VERSION "10.9.1"

NS_ :

BS_:

BU_: ACM ADAS_Body APM ASU_Gateway BCM BCM_BPM CCU_F CCU_R DUMMY_BCM_BPM DUMMY_ECU ETG LDM_L LDM_R OCS_P PSM_D SHVU_F SHVU_R TRM XGW_Body

BO_ 1112 MHU_BCM_Color_Req: 8 XGW_Body
 SG_ AmbLightColorZoneReq : 7|8@0+ (1,0) [0|31] "-"  BCM
 SG_ AmbLightColorRed : 15|8@0+ (1,0) [0|255] ""  BCM
 SG_ AmbLightColorGreen : 23|8@0+ (1,0) [0|255] "-"  BCM
 SG_ AmbLightColorBlue : 31|8@0+ (1,0) [0|255] "-"  BCM
 SG_ SECCAN_BCM_Clr_Rq : 63|8@0+ (1,0) [0|255] ""  BCM

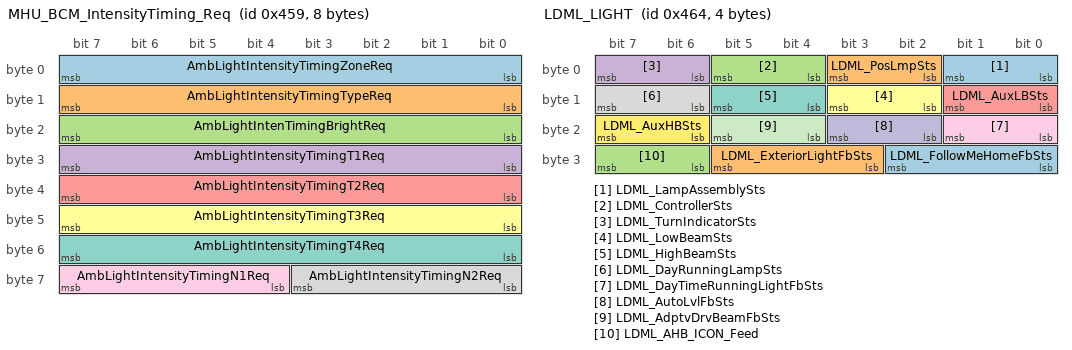
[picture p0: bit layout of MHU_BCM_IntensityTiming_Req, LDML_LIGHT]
BO_ 1113 MHU_BCM_IntensityTiming_Req: 8 XGW_Body
 SG_ AmbLightIntensityTimingZoneReq : 7|8@0+ (1,0) [0|31] ""  BCM
 SG_ AmbLightIntensityTimingTypeReq : 15|8@0+ (1,0) [0|5] ""  BCM
 SG_ AmbLightIntenTimingBrightReq : 23|8@0+ (1,0) [0|100] ""  BCM
 SG_ AmbLightIntensityTimingT1Req : 31|8@0+ (0.1,0) [0|25.5] "s"  BCM
 SG_ AmbLightIntensityTimingT2Req : 39|8@0+ (0.1,0) [0|25.5] "s"  BCM
 SG_ AmbLightIntensityTimingT3Req : 47|8@0+ (0.1,0) [0|25.5] "s"  BCM
 SG_ AmbLightIntensityTimingT4Req : 55|8@0+ (0.1,0) [0|25.5] "s"  BCM
 SG_ AmbLightIntensityTimingN2Req : 59|4@0+ (1,0) [0|15] "-"  BCM
 SG_ AmbLightIntensityTimingN1Req : 63|4@0+ (1,0) [0|15] ""  BCM

BO_ 1115 ADAS_HOD: 8 ADAS_Body
 SG_ HOD_steering_wheel_type : 5|4@0+ (1,0) [0|15] ""  XGW_Body
 SG_ HOD_vehicle_type : 15|8@0+ (1,0) [0|255] ""  XGW_Body
 SG_ ADAS_HOD_state_requesting : 57|2@0+ (1,0) [0|3] ""  XGW_Body

BO_ 1124 LDML_LIGHT: 4 LDM_L
 SG_ LDML_LampAssemblySts : 1|2@0+ (1,0) [0|3] "-"  BCM,XGW_Body
 SG_ LDML_PosLmpSts : 3|2@0+ (1,0) [0|3] ""  BCM,XGW_Body
 SG_ LDML_ControllerSts : 5|2@0+ (1,0) [0|3] ""  BCM,XGW_Body
 SG_ LDML_TurnIndicatorSts : 7|2@0+ (1,0) [0|3] ""  BCM,XGW_Body
 SG_ LDML_AuxLBSts : 9|2@0+ (1,0) [0|3] "-"  BCM,XGW_Body
 SG_ LDML_LowBeamSts : 11|2@0+ (1,0) [0|3] "-"  BCM,XGW_Body
 SG_ LDML_HighBeamSts : 13|2@0+ (1,0) [0|3] ""  BCM,XGW_Body
 SG_ LDML_DayRunningLampSts : 15|2@0+ (1,0) [0|3] ""  BCM,XGW_Body
 SG_ LDML_DayTimeRunningLightFbSts : 17|2@0+ (1,0) [0|3] ""  BCM,XGW_Body
 SG_ LDML_AutoLvlFbSts : 19|2@0+ (1,0) [0|3] ""  BCM,XGW_Body
 SG_ LDML_AdptvDrvBeamFbSts : 21|2@0+ (1,0) [0|3] "-"  BCM,XGW_Body
 SG_ LDML_AuxHBSts : 23|2@0+ (1,0) [0|3] "-"  BCM,XGW_Body
 SG_ LDML_FollowMeHomeFbSts : 26|3@0+ (1,0) [0|5] "-"  BCM,XGW_Body
 SG_ LDML_ExteriorLightFbSts : 29|3@0+ (1,0) [0|4] "-"  BCM,XGW_Body
 SG_ LDML_AHB_ICON_Feed : 31|2@0+ (1,0) [0|3] ""  XGW_Body

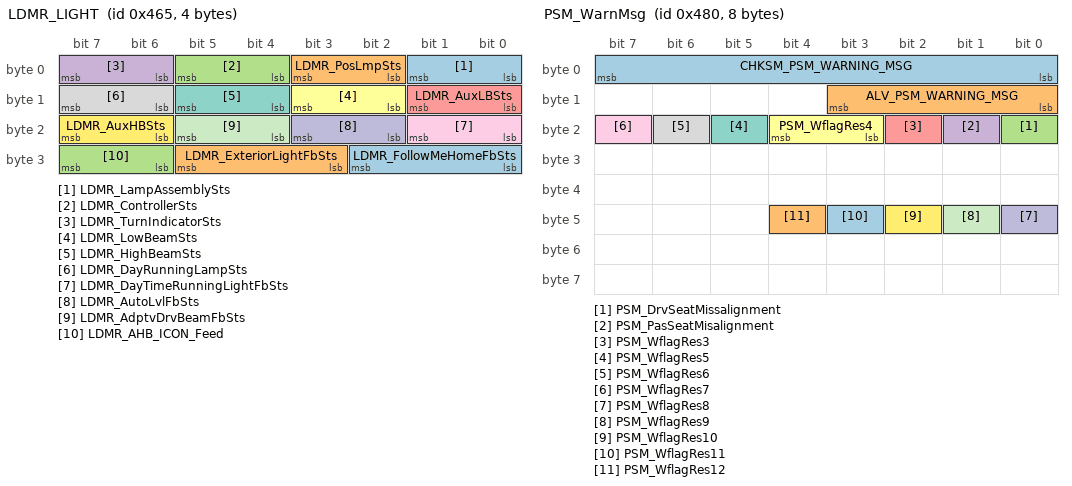
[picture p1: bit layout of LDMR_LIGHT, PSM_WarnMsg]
BO_ 1125 LDMR_LIGHT: 4 LDM_R
 SG_ LDMR_LampAssemblySts : 1|2@0+ (1,0) [0|3] ""  BCM,XGW_Body
 SG_ LDMR_PosLmpSts : 3|2@0+ (1,0) [0|3] "-"  BCM,XGW_Body
 SG_ LDMR_ControllerSts : 5|2@0+ (1,0) [0|3] ""  BCM,XGW_Body
 SG_ LDMR_TurnIndicatorSts : 7|2@0+ (1,0) [0|3] "-"  BCM,XGW_Body
 SG_ LDMR_AuxLBSts : 9|2@0+ (1,0) [0|3] "-"  BCM,XGW_Body
 SG_ LDMR_LowBeamSts : 11|2@0+ (1,0) [0|3] "-"  BCM,XGW_Body
 SG_ LDMR_HighBeamSts : 13|2@0+ (1,0) [0|3] ""  BCM,XGW_Body
 SG_ LDMR_DayRunningLampSts : 15|2@0+ (1,0) [0|3] ""  BCM,XGW_Body
 SG_ LDMR_DayTimeRunningLightFbSts : 17|2@0+ (1,0) [0|3] "-"  BCM,XGW_Body
 SG_ LDMR_AutoLvlFbSts : 19|2@0+ (1,0) [0|3] "-"  BCM,XGW_Body
 SG_ LDMR_AdptvDrvBeamFbSts : 21|2@0+ (1,0) [0|3] ""  BCM,XGW_Body
 SG_ LDMR_AuxHBSts : 23|2@0+ (1,0) [0|3] "-"  BCM,XGW_Body
 SG_ LDMR_FollowMeHomeFbSts : 26|3@0+ (1,0) [0|5] ""  BCM,XGW_Body
 SG_ LDMR_ExteriorLightFbSts : 29|3@0+ (1,0) [0|4] "-"  BCM,XGW_Body
 SG_ LDMR_AHB_ICON_Feed : 31|2@0+ (1,0) [0|3] ""  XGW_Body

BO_ 1152 PSM_WarnMsg: 8 PSM_D
 SG_ CHKSM_PSM_WARNING_MSG : 7|8@0+ (1,0) [0|255] ""  XGW_Body
 SG_ ALV_PSM_WARNING_MSG : 11|4@0+ (1,0) [0|14] ""  XGW_Body
 SG_ PSM_DrvSeatMissalignment : 16|1@0+ (1,0) [0|1] ""  XGW_Body
 SG_ PSM_PasSeatMisalignment : 17|1@0+ (1,0) [0|1] "Bit"  XGW_Body
 SG_ PSM_WflagRes3 : 18|1@0+ (1,0) [0|1] "Bit"  XGW_Body
 SG_ PSM_WflagRes4 : 20|2@0+ (1,0) [0|3] "Bit"  XGW_Body
 SG_ PSM_WflagRes5 : 21|1@0+ (1,0) [0|1] "-"  XGW_Body
 SG_ PSM_WflagRes6 : 22|1@0+ (1,0) [0|1] "-"  XGW_Body
 SG_ PSM_WflagRes7 : 23|1@0+ (1,0) [0|1] "-"  XGW_Body
 SG_ PSM_WflagRes8 : 40|1@0+ (1,0) [0|1] ""  XGW_Body
 SG_ PSM_WflagRes9 : 41|1@0+ (1,0) [0|1] ""  XGW_Body
 SG_ PSM_WflagRes10 : 42|1@0+ (1,0) [0|1] "-"  XGW_Body
 SG_ PSM_WflagRes11 : 43|1@0+ (1,0) [0|1] "-"  XGW_Body
 SG_ PSM_WflagRes12 : 44|1@0+ (1,0) [0|1] "-"  XGW_Body

BO_ 1153 BCM_WarnMsg: 8 BCM
 SG_ CHSKM_BCM_WarnMsg : 7|8@0+ (1,0) [0|255] "" XGW_Body
 SG_ ALV_BCM_WarnMsg : 11|4@0+ (1,0) [0|14] "" XGW_Body
 SG_ BCM_NoValidKey_1 : 12|1@0+ (1,0) [0|1] "" XGW_Body
 SG_ BCM_SSB_defect : 13|1@0+ (1,0) [0|1] "" XGW_Body
 SG_ BCM_WrongGearPosToStart : 14|1@0+ (1,0) [0|1] "" XGW_Body
 SG_ BCM_NoValidKey_2 : 15|1@0+ (1,0) [0|1] "" XGW_Body
 SG_ BCM_PressBrakeToStart : 16|1@0+ (1,0) [0|1] "" XGW_Body
 SG_ BCM_TurnOffPosLightRemindr : 17|1@0+ (1,0) [0|1] "" XGW_Body
 SG_ BCM_KeyFob_LowBattery : 18|1@0+ (1,0) [0|1] "" XGW_Body
 SG_ BCM_StopLightDefect : 19|1@0+ (1,0) [0|1] "" XGW_Body
 SG_ BCM_LowBeamDefect : 20|1@0+ (1,0) [0|1] "" XGW_Body
 SG_ BCM_HighBeamDefect : 21|1@0+ (1,0) [0|1] "" XGW_Body
 SG_ BCM_PositionLightDefect : 22|1@0+ (1,0) [0|1] "" XGW_Body
 SG_ BCM_CHMLS_Defect : 23|1@0+ (1,0) [0|1] "" XGW_Body
 SG_ BCM_LicencePlateLight_Defect : 24|1@0+ (1,0) [0|1] "" XGW_Body
 SG_ BCM_FrontFog_Defect : 25|1@0+ (1,0) [0|1] "" XGW_Body
 SG_ BCM_RearFog_Defect : 26|1@0+ (1,0) [0|1] "" XGW_Body
 SG_ BCM_ReverseLightDefect : 27|1@0+ (1,0) [0|1] "" XGW_Body
 SG_ BCM_RLS_Malfunction : 28|1@0+ (1,0) [0|1] "" XGW_Body
 SG_ BCM_12VBattery_LowLevel : 29|1@0+ (1,0) [0|1] "" XGW_Body
 SG_ BCM_ForgetKeyFOBInCar : 30|1@0+ (1,0) [0|1] "" XGW_Body
 SG_ BCM_12VBattery_Discharging : 31|1@0+ (1,0) [0|1] "" XGW_Body
 SG_ BCM_TurnIndicatorDefect : 32|1@0+ (1,0) [0|1] "" XGW_Body
 SG_ BCM_dTPMS_Malfunc : 33|1@0+ (1,0) [0|1] "" XGW_Body
 SG_ BCM_dTPMS_Malfunc_LostSensor : 34|1@0+ (1,0) [0|1] "" XGW_Body
 SG_ BCM_dTPMS_LowPressure : 35|1@0+ (1,0) [0|1] "" XGW_Body
 SG_ BCM_dTPMS_RapidLeak : 36|1@0+ (1,0) [0|1] "" XGW_Body
 SG_ BCM_dTPMS_HighTemperature : 37|1@0+ (1,0) [0|1] "" XGW_Body
 SG_ BCM_dTPMS_HighPressure : 38|1@0+ (1,0) [0|1] "" XGW_Body
 SG_ BCM_dTPMS_LowBattery : 39|1@0+ (1,0) [0|1] "" XGW_Body
 SG_ BCM_Keyfob_Leftcar : 40|1@0+ (1,0) [0|1] "" XGW_Body
 SG_ BCM_IDB_Brakelight_Malfunction : 41|1@0+ (1,0) [0|1] "" XGW_Body
 SG_ BCM_VCU_Brakelight_Malfunction : 42|1@0+ (1,0) [0|1] "" XGW_Body
 SG_ BCM_ADAS_Turnlight_Malfunction : 43|1@0+ (1,0) [0|1] "" XGW_Body
 SG_ BCM_ADAS_Highbeam_Malfunction : 44|1@0+ (1,0) [0|1] "" XGW_Body
 SG_ BCM_ADAS_LowBeam_Malfunction : 45|1@0+ (1,0) [0|1] "" XGW_Body
 SG_ BCM_MHU_Malfunction : 46|1@0+ (1,0) [0|1] "" XGW_Body
 SG_ BCM_BCM_Malfunction : 47|1@0+ (1,0) [0|1] "" XGW_Body
 SG_ BCM_SCM_Malfunction : 48|1@0+ (1,0) [0|1] "" XGW_Body
 SG_ BCM_CrashSignalDefect : 49|1@0+ (1,0) [0|1] "" XGW_Body
 SG_ BCM_FrontWiperDefect : 51|1@0+ (1,0) [0|1] "" XGW_Body
 SG_ BCM_Rear_RightDoorLockDefect : 52|1@0+ (1,0) [0|1] "" XGW_Body
 SG_ BCM_RearLeftDoorLockDefect : 53|1@0+ (1,0) [0|1] "" XGW_Body
 SG_ BCM_Front_RightDoorLockDefect : 54|1@0+ (1,0) [0|1] "" XGW_Body
 SG_ BCM_FrontLeftDoorLockDefect : 55|1@0+ (1,0) [0|1] "" XGW_Body
 SG_ BCM_LDML_Malfunction : 56|1@0+ (1,0) [0|1] "" XGW_Body
 SG_ BCM_LDMR_Malfunction : 57|1@0+ (1,0) [0|1] "" XGW_Body
 SG_ BCM_RLBL_Malfunction : 58|1@0+ (1,0) [0|1] "" XGW_Body
 SG_ BCM_RLBR_Malfunction : 59|1@0+ (1,0) [0|1] "" XGW_Body
 SG_ BCM_RLT_Malfunction : 60|1@0+ (1,0) [0|1] "" XGW_Body
 SG_ BCM_BCM_POWER_Malfunction : 61|1@0+ (1,0) [0|1] "" XGW_Body
 SG_ BCM_IDB_AutoHazardBlinking_Malf : 62|1@0+ (1,0) [0|1] "" XGW_Body

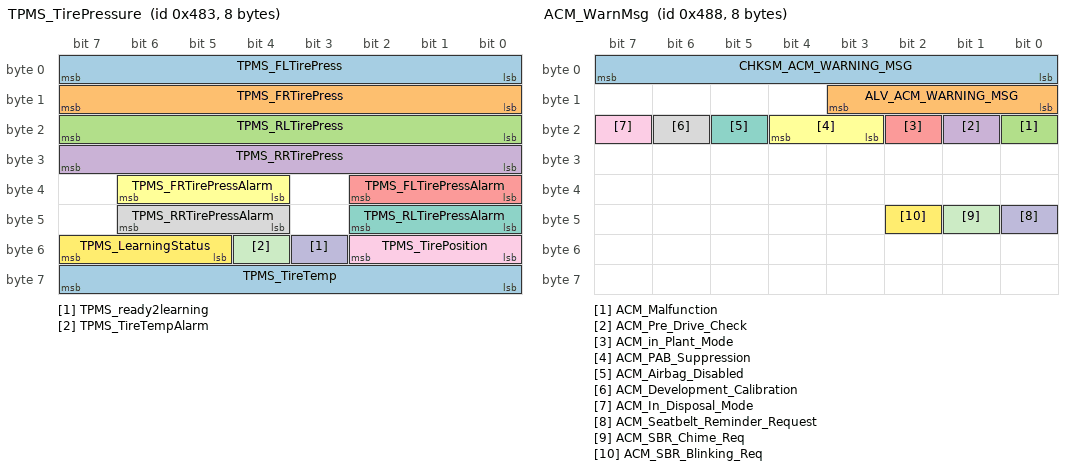
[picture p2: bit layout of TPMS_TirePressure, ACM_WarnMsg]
BO_ 1155 TPMS_TirePressure: 8 BCM
 SG_ TPMS_FLTirePress : 7|8@0+ (1.373,0) [0|350] "kPa"  ADAS_Body,XGW_Body
 SG_ TPMS_FRTirePress : 15|8@0+ (1.373,0) [0|350] "kPa"  ADAS_Body,XGW_Body
 SG_ TPMS_RLTirePress : 23|8@0+ (1.373,0) [0|350] "kPa"  ADAS_Body,XGW_Body
 SG_ TPMS_RRTirePress : 31|8@0+ (1.373,0) [0|350] "kPa"  ADAS_Body,XGW_Body
 SG_ TPMS_FLTirePressAlarm : 34|3@0+ (1,0) [0|7] ""  ADAS_Body,XGW_Body
 SG_ TPMS_FRTirePressAlarm : 38|3@0+ (1,0) [0|7] "-"  ADAS_Body,XGW_Body
 SG_ TPMS_RLTirePressAlarm : 42|3@0+ (1,0) [0|7] ""  ADAS_Body,XGW_Body
 SG_ TPMS_RRTirePressAlarm : 46|3@0+ (1,0) [0|7] ""  ADAS_Body,XGW_Body
 SG_ TPMS_TirePosition : 50|3@0+ (1,0) [0|7] "-"  XGW_Body
 SG_ TPMS_ready2learning : 51|1@0+ (1,0) [0|1] "-"  XGW_Body
 SG_ TPMS_TireTempAlarm : 52|1@0+ (1,0) [0|1] "-"  XGW_Body
 SG_ TPMS_LearningStatus : 55|3@0+ (1,0) [0|7] "-"  XGW_Body
 SG_ TPMS_TireTemp : 63|8@0+ (1,-40) [-40|215] "Degree C"  XGW_Body

BO_ 1160 ACM_WarnMsg: 8 ACM
 SG_ CHKSM_ACM_WARNING_MSG : 7|8@0+ (1,0) [0|255] ""  XGW_Body
 SG_ ALV_ACM_WARNING_MSG : 11|4@0+ (1,0) [0|14] ""  XGW_Body
 SG_ ACM_Malfunction : 16|1@0+ (1,0) [0|1] ""  XGW_Body
 SG_ ACM_Pre_Drive_Check : 17|1@0+ (1,0) [0|1] "Bit"  XGW_Body
 SG_ ACM_in_Plant_Mode : 18|1@0+ (1,0) [0|1] "Bit"  XGW_Body
 SG_ ACM_PAB_Suppression : 20|2@0+ (1,0) [0|3] "Bit"  XGW_Body
 SG_ ACM_Airbag_Disabled : 21|1@0+ (1,0) [0|1] "-"  XGW_Body
 SG_ ACM_Development_Calibration : 22|1@0+ (1,0) [0|1] "-"  XGW_Body
 SG_ ACM_In_Disposal_Mode : 23|1@0+ (1,0) [0|1] ""  XGW_Body
 SG_ ACM_Seatbelt_Reminder_Request : 40|1@0+ (1,0) [0|1] "-"  XGW_Body
 SG_ ACM_SBR_Chime_Req : 41|1@0+ (1,0) [0|1] ""  XGW_Body
 SG_ ACM_SBR_Blinking_Req : 42|1@0+ (1,0) [0|1] ""  XGW_Body

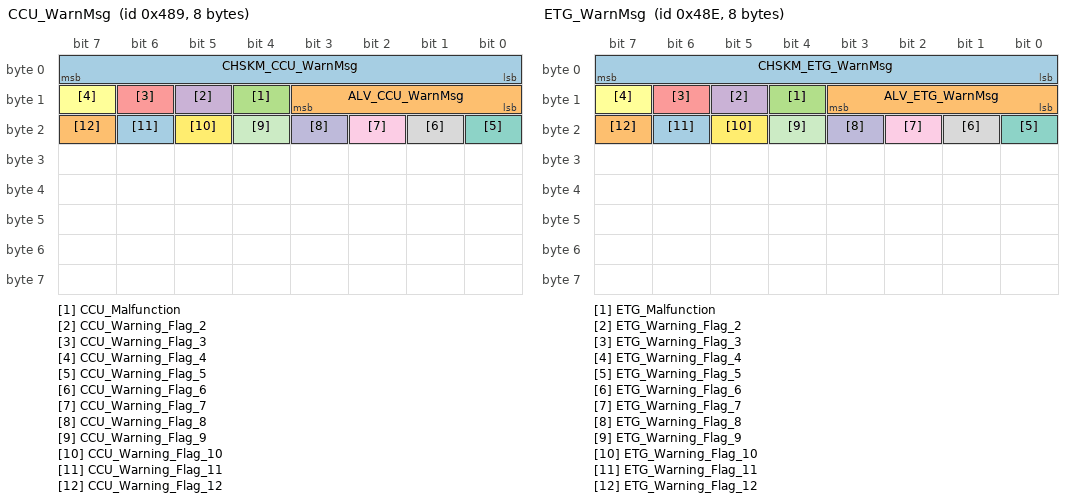
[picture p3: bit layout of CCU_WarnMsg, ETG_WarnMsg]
BO_ 1161 CCU_WarnMsg: 8 CCU_F
 SG_ CHSKM_CCU_WarnMsg : 7|8@0+ (1,0) [0|255] ""  XGW_Body
 SG_ ALV_CCU_WarnMsg : 11|4@0+ (1,0) [0|14] ""  XGW_Body
 SG_ CCU_Malfunction : 12|1@0+ (1,0) [0|1] ""  XGW_Body
 SG_ CCU_Warning_Flag_2 : 13|1@0+ (1,0) [0|1] "-"  XGW_Body
 SG_ CCU_Warning_Flag_3 : 14|1@0+ (1,0) [0|1] ""  XGW_Body
 SG_ CCU_Warning_Flag_4 : 15|1@0+ (1,0) [0|1] "-"  XGW_Body
 SG_ CCU_Warning_Flag_5 : 16|1@0+ (1,0) [0|1] "-"  XGW_Body
 SG_ CCU_Warning_Flag_6 : 17|1@0+ (1,0) [0|1] "-"  XGW_Body
 SG_ CCU_Warning_Flag_7 : 18|1@0+ (1,0) [0|1] "-"  XGW_Body
 SG_ CCU_Warning_Flag_8 : 19|1@0+ (1,0) [0|1] ""  XGW_Body
 SG_ CCU_Warning_Flag_9 : 20|1@0+ (1,0) [0|1] ""  XGW_Body
 SG_ CCU_Warning_Flag_10 : 21|1@0+ (1,0) [0|1] ""  XGW_Body
 SG_ CCU_Warning_Flag_11 : 22|1@0+ (1,0) [0|1] ""  XGW_Body
 SG_ CCU_Warning_Flag_12 : 23|1@0+ (1,0) [0|1] ""  XGW_Body

BO_ 1166 ETG_WarnMsg: 8 ETG
 SG_ CHSKM_ETG_WarnMsg : 7|8@0+ (1,0) [0|255] ""  XGW_Body
 SG_ ALV_ETG_WarnMsg : 11|4@0+ (1,0) [0|14] ""  XGW_Body
 SG_ ETG_Malfunction : 12|1@0+ (1,0) [0|1] "-"  XGW_Body
 SG_ ETG_Warning_Flag_2 : 13|1@0+ (1,0) [0|1] "-"  XGW_Body
 SG_ ETG_Warning_Flag_3 : 14|1@0+ (1,0) [0|1] ""  XGW_Body
 SG_ ETG_Warning_Flag_4 : 15|1@0+ (1,0) [0|1] ""  XGW_Body
 SG_ ETG_Warning_Flag_5 : 16|1@0+ (1,0) [0|1] "-"  XGW_Body
 SG_ ETG_Warning_Flag_6 : 17|1@0+ (1,0) [0|1] "-"  XGW_Body
 SG_ ETG_Warning_Flag_7 : 18|1@0+ (1,0) [0|1] "-"  XGW_Body
 SG_ ETG_Warning_Flag_8 : 19|1@0+ (1,0) [0|1] ""  XGW_Body
 SG_ ETG_Warning_Flag_9 : 20|1@0+ (1,0) [0|1] ""  XGW_Body
 SG_ ETG_Warning_Flag_10 : 21|1@0+ (1,0) [0|1] ""  XGW_Body
 SG_ ETG_Warning_Flag_11 : 22|1@0+ (1,0) [0|1] "-"  XGW_Body
 SG_ ETG_Warning_Flag_12 : 23|1@0+ (1,0) [0|1] ""  XGW_Body

BO_ 1171 BMS_WarnMsg: 8 XGW_Body
 SG_ CHSKM_BMS_WarnMsg : 7|8@0+ (1,0) [0|255] "" BCM
 SG_ ALV_BMS_WarnMsg : 11|4@0+ (1,0) [0|14] "" BCM
 SG_ BMS_PackTempSts : 13|2@0+ (1,0) [0|3] "" BCM
 SG_ BMS_ThermalRunaway : 14|1@0+ (1,0) [0|1] "" BCM
 SG_ BMS_BatteryReplacement : 15|1@0+ (1,0) [0|1] "" BCM
 SG_ BMS_Warning_PowerDegrade : 16|1@0+ (1,0) [0|1] "" BCM
 SG_ BMS_Warning_DeltaSoC : 17|1@0+ (1,0) [0|1] "" BCM
 SG_ BMS_Warning_HVILSts : 18|1@0+ (1,0) [0|1] "" BCM
 SG_ BMS_Warning_Isolation : 19|1@0+ (1,0) [0|1] "" BCM
 SG_ BMS_Warning_CoolantLeakage : 20|1@0+ (1,0) [0|1] "" BCM
 SG_ BMS_MalfunctionSts : 21|1@0+ (1,0) [0|1] "" BCM
 SG_ BMS_LowBattery : 23|2@0+ (1,0) [0|3] "" BCM
 SG_ BMS_Warning_DeltaTemperature : 31|8@0+ (1,0) [0|255] "" BCM
 SG_ BMS_Warning_BDUTemperatureSts : 39|8@0+ (1,0) [0|255] "" BCM
 SG_ BMS_Warning_Contactor_Aging : 47|1@0+ (1,0) [0|1] "" DUMMY_ECU
 SG_ BMS_Reserved_signal4 : 55|8@0+ (1,0) [0|255] "" BCM
 SG_ BMS_Reserved_signal5 : 63|8@0+ (1,0) [0|255] "" BCM

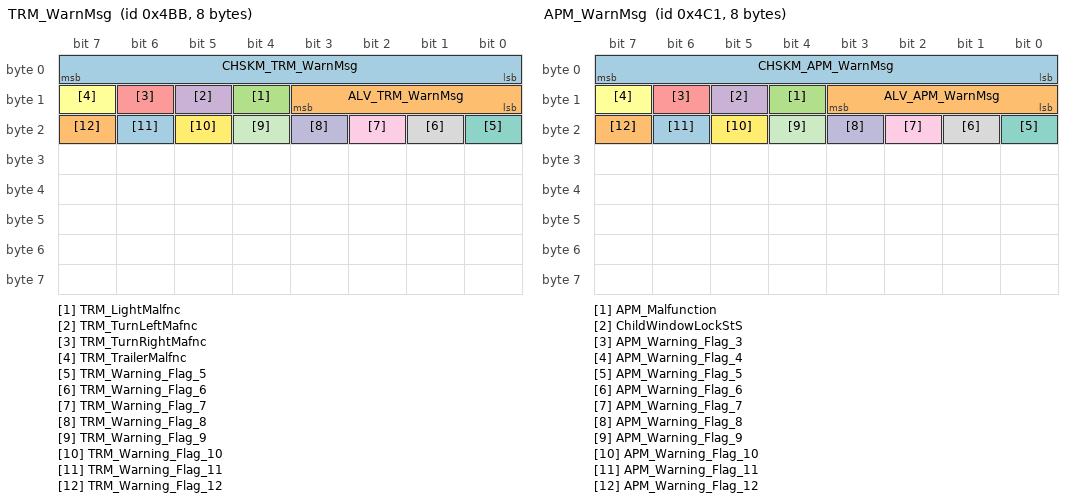
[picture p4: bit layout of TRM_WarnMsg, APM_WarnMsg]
BO_ 1211 TRM_WarnMsg: 8 TRM
 SG_ CHSKM_TRM_WarnMsg : 7|8@0+ (1,0) [0|255] ""  XGW_Body
 SG_ ALV_TRM_WarnMsg : 11|4@0+ (1,0) [0|14] ""  XGW_Body
 SG_ TRM_LightMalfnc : 12|1@0+ (1,0) [0|1] "-"  XGW_Body
 SG_ TRM_TurnLeftMafnc : 13|1@0+ (1,0) [0|1] "-"  XGW_Body
 SG_ TRM_TurnRightMafnc : 14|1@0+ (1,0) [0|1] ""  XGW_Body
 SG_ TRM_TrailerMalfnc : 15|1@0+ (1,0) [0|1] ""  XGW_Body
 SG_ TRM_Warning_Flag_5 : 16|1@0+ (1,0) [0|1] "-"  XGW_Body
 SG_ TRM_Warning_Flag_6 : 17|1@0+ (1,0) [0|1] ""  XGW_Body
 SG_ TRM_Warning_Flag_7 : 18|1@0+ (1,0) [0|1] ""  XGW_Body
 SG_ TRM_Warning_Flag_8 : 19|1@0+ (1,0) [0|1] "-"  XGW_Body
 SG_ TRM_Warning_Flag_9 : 20|1@0+ (1,0) [0|1] "-"  XGW_Body
 SG_ TRM_Warning_Flag_10 : 21|1@0+ (1,0) [0|1] "-"  XGW_Body
 SG_ TRM_Warning_Flag_11 : 22|1@0+ (1,0) [0|1] ""  XGW_Body
 SG_ TRM_Warning_Flag_12 : 23|1@0+ (1,0) [0|1] ""  XGW_Body

BO_ 1216 BCM_STAT_DOOR: 8 BCM
 SG_ SECCAN_BCM_STAT_Door : 55|8@0+ (1,0) [0|255] ""  ADAS_Body
 SG_ BCM_STAT_DoorHandleRR : 56|1@0+ (1,0) [0|1] ""  ADAS_Body
 SG_ BCM_STAT_DoorHandleRL : 57|1@0+ (1,0) [0|1] ""  ADAS_Body
 SG_ BCM_STAT_DoorHandleFR : 58|1@0+ (1,0) [0|1] ""  ADAS_Body
 SG_ BCM_STAT_DoorHandleFL : 59|1@0+ (1,0) [0|1] ""  ADAS_Body

BO_ 1217 APM_WarnMsg: 8 APM
 SG_ CHSKM_APM_WarnMsg : 7|8@0+ (1,0) [0|255] ""  XGW_Body
 SG_ ALV_APM_WarnMsg : 11|4@0+ (1,0) [0|14] ""  XGW_Body
 SG_ APM_Malfunction : 12|1@0+ (1,0) [0|1] ""  XGW_Body
 SG_ ChildWindowLockStS : 13|1@0+ (1,0) [0|1] "-"  XGW_Body
 SG_ APM_Warning_Flag_3 : 14|1@0+ (1,0) [0|1] ""  XGW_Body
 SG_ APM_Warning_Flag_4 : 15|1@0+ (1,0) [0|1] ""  XGW_Body
 SG_ APM_Warning_Flag_5 : 16|1@0+ (1,0) [0|1] "-"  XGW_Body
 SG_ APM_Warning_Flag_6 : 17|1@0+ (1,0) [0|1] ""  XGW_Body
 SG_ APM_Warning_Flag_7 : 18|1@0+ (1,0) [0|1] "-"  XGW_Body
 SG_ APM_Warning_Flag_8 : 19|1@0+ (1,0) [0|1] ""  XGW_Body
 SG_ APM_Warning_Flag_9 : 20|1@0+ (1,0) [0|1] ""  XGW_Body
 SG_ APM_Warning_Flag_10 : 21|1@0+ (1,0) [0|1] ""  XGW_Body
 SG_ APM_Warning_Flag_11 : 22|1@0+ (1,0) [0|1] ""  XGW_Body
 SG_ APM_Warning_Flag_12 : 23|1@0+ (1,0) [0|1] "-"  XGW_Body

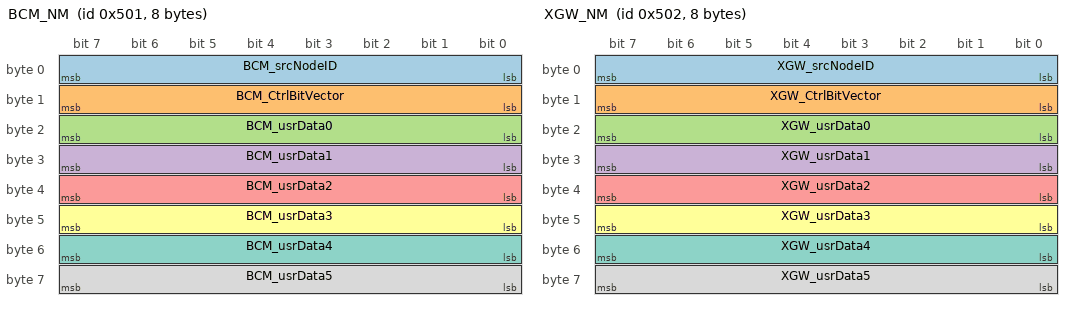
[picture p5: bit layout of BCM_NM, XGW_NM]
BO_ 1281 BCM_NM: 8 BCM
 SG_ BCM_srcNodeID : 7|8@0+ (1,0) [0|255] ""  APM,CCU_F,CCU_R,ETG,LDM_L,LDM_R,PSM_D,TRM,XGW_Body
 SG_ BCM_CtrlBitVector : 15|8@0+ (1,0) [0|255] ""  APM,CCU_F,CCU_R,ETG,LDM_L,LDM_R,PSM_D,TRM,XGW_Body
 SG_ BCM_usrData0 : 23|8@0+ (1,0) [0|255] ""  APM,CCU_F,CCU_R,ETG,LDM_L,LDM_R,PSM_D,TRM,XGW_Body
 SG_ BCM_usrData1 : 31|8@0+ (1,0) [0|255] ""  APM,CCU_F,CCU_R,ETG,LDM_L,LDM_R,PSM_D,TRM,XGW_Body
 SG_ BCM_usrData2 : 39|8@0+ (1,0) [0|255] ""  APM,CCU_F,CCU_R,ETG,LDM_L,LDM_R,PSM_D,TRM,XGW_Body
 SG_ BCM_usrData3 : 47|8@0+ (1,0) [0|255] ""  APM,CCU_F,CCU_R,ETG,LDM_L,LDM_R,PSM_D,TRM,XGW_Body
 SG_ BCM_usrData4 : 55|8@0+ (1,0) [0|255] ""  APM,CCU_F,CCU_R,ETG,LDM_L,LDM_R,PSM_D,TRM,XGW_Body
 SG_ BCM_usrData5 : 63|8@0+ (1,0) [0|255] ""  APM,CCU_F,CCU_R,ETG,LDM_L,LDM_R,PSM_D,TRM,XGW_Body

BO_ 1282 XGW_NM: 8 XGW_Body
 SG_ XGW_srcNodeID : 7|8@0+ (1,0) [0|255] ""  APM,ASU_Gateway,BCM,CCU_F,CCU_R,ETG,LDM_L,LDM_R,PSM_D,TRM
 SG_ XGW_CtrlBitVector : 15|8@0+ (1,0) [0|255] ""  APM,ASU_Gateway,BCM,CCU_F,CCU_R,ETG,LDM_L,LDM_R,PSM_D,TRM
 SG_ XGW_usrData0 : 23|8@0+ (1,0) [0|255] ""  APM,ASU_Gateway,BCM,CCU_F,CCU_R,ETG,LDM_L,LDM_R,PSM_D,TRM
 SG_ XGW_usrData1 : 31|8@0+ (1,0) [0|255] ""  APM,ASU_Gateway,BCM,CCU_F,CCU_R,ETG,LDM_L,LDM_R,PSM_D,TRM
 SG_ XGW_usrData2 : 39|8@0+ (1,0) [0|255] ""  APM,ASU_Gateway,BCM,CCU_F,CCU_R,ETG,LDM_L,LDM_R,PSM_D,TRM
 SG_ XGW_usrData3 : 47|8@0+ (1,0) [0|255] ""  APM,ASU_Gateway,BCM,CCU_F,CCU_R,ETG,LDM_L,LDM_R,PSM_D,TRM
 SG_ XGW_usrData4 : 55|8@0+ (1,0) [0|255] ""  APM,ASU_Gateway,BCM,CCU_F,CCU_R,ETG,LDM_L,LDM_R,PSM_D,TRM
 SG_ XGW_usrData5 : 63|8@0+ (1,0) [0|255] ""  APM,ASU_Gateway,BCM,CCU_F,CCU_R,ETG,LDM_L,LDM_R,PSM_D,TRM

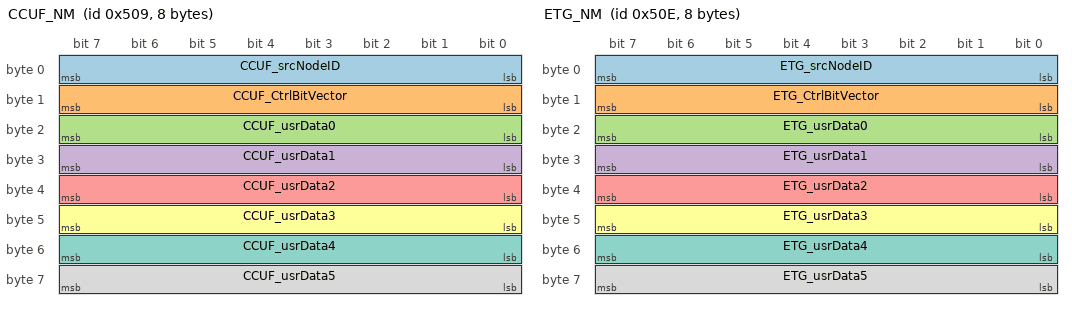
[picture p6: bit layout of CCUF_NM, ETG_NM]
BO_ 1289 CCUF_NM: 8 CCU_F
 SG_ CCUF_srcNodeID : 7|8@0+ (1,0) [0|255] ""  APM,BCM,CCU_R,ETG,LDM_L,LDM_R,PSM_D,TRM,XGW_Body
 SG_ CCUF_CtrlBitVector : 15|8@0+ (1,0) [0|255] ""  APM,BCM,CCU_R,ETG,LDM_L,LDM_R,PSM_D,TRM,XGW_Body
 SG_ CCUF_usrData0 : 23|8@0+ (1,0) [0|255] ""  APM,BCM,CCU_R,ETG,LDM_L,LDM_R,PSM_D,TRM,XGW_Body
 SG_ CCUF_usrData1 : 31|8@0+ (1,0) [0|255] ""  APM,BCM,CCU_R,ETG,LDM_L,LDM_R,PSM_D,TRM,XGW_Body
 SG_ CCUF_usrData2 : 39|8@0+ (1,0) [0|255] ""  APM,BCM,CCU_R,ETG,LDM_L,LDM_R,PSM_D,TRM,XGW_Body
 SG_ CCUF_usrData3 : 47|8@0+ (1,0) [0|255] ""  APM,BCM,CCU_R,ETG,LDM_L,LDM_R,PSM_D,TRM,XGW_Body
 SG_ CCUF_usrData4 : 55|8@0+ (1,0) [0|255] ""  APM,BCM,CCU_R,ETG,LDM_L,LDM_R,PSM_D,TRM,XGW_Body
 SG_ CCUF_usrData5 : 63|8@0+ (1,0) [0|255] ""  APM,BCM,CCU_R,ETG,LDM_L,LDM_R,PSM_D,TRM,XGW_Body

BO_ 1294 ETG_NM: 8 ETG
 SG_ ETG_srcNodeID : 7|8@0+ (1,0) [0|255] ""  APM,BCM,CCU_F,CCU_R,LDM_L,LDM_R,PSM_D,TRM,XGW_Body
 SG_ ETG_CtrlBitVector : 15|8@0+ (1,0) [0|255] ""  APM,BCM,CCU_F,CCU_R,LDM_L,LDM_R,PSM_D,TRM,XGW_Body
 SG_ ETG_usrData0 : 23|8@0+ (1,0) [0|255] ""  APM,BCM,CCU_F,CCU_R,LDM_L,LDM_R,PSM_D,TRM,XGW_Body
 SG_ ETG_usrData1 : 31|8@0+ (1,0) [0|255] ""  APM,BCM,CCU_F,CCU_R,LDM_L,LDM_R,PSM_D,TRM,XGW_Body
 SG_ ETG_usrData2 : 39|8@0+ (1,0) [0|255] ""  APM,BCM,CCU_F,CCU_R,LDM_L,LDM_R,PSM_D,TRM,XGW_Body
 SG_ ETG_usrData3 : 47|8@0+ (1,0) [0|255] ""  APM,BCM,CCU_F,CCU_R,LDM_L,LDM_R,PSM_D,TRM,XGW_Body
 SG_ ETG_usrData4 : 55|8@0+ (1,0) [0|255] ""  APM,BCM,CCU_F,CCU_R,LDM_L,LDM_R,PSM_D,TRM,XGW_Body
 SG_ ETG_usrData5 : 63|8@0+ (1,0) [0|255] ""  APM,BCM,CCU_F,CCU_R,LDM_L,LDM_R,PSM_D,TRM,XGW_Body

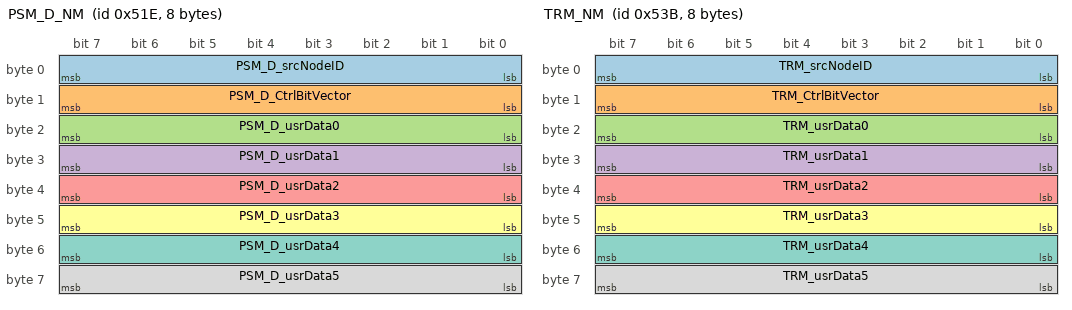
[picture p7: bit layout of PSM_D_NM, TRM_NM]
BO_ 1310 PSM_D_NM: 8 PSM_D
 SG_ PSM_D_srcNodeID : 7|8@0+ (1,0) [0|255] ""  APM,BCM,CCU_F,CCU_R,ETG,LDM_L,LDM_R,TRM,XGW_Body
 SG_ PSM_D_CtrlBitVector : 15|8@0+ (1,0) [0|255] ""  APM,BCM,CCU_F,CCU_R,ETG,LDM_L,LDM_R,TRM,XGW_Body
 SG_ PSM_D_usrData0 : 23|8@0+ (1,0) [0|255] ""  APM,BCM,CCU_F,CCU_R,ETG,LDM_L,LDM_R,TRM,XGW_Body
 SG_ PSM_D_usrData1 : 31|8@0+ (1,0) [0|255] ""  APM,BCM,CCU_F,CCU_R,ETG,LDM_L,LDM_R,TRM,XGW_Body
 SG_ PSM_D_usrData2 : 39|8@0+ (1,0) [0|255] ""  APM,BCM,CCU_F,CCU_R,ETG,LDM_L,LDM_R,TRM,XGW_Body
 SG_ PSM_D_usrData3 : 47|8@0+ (1,0) [0|255] ""  APM,BCM,CCU_F,CCU_R,ETG,LDM_L,LDM_R,TRM,XGW_Body
 SG_ PSM_D_usrData4 : 55|8@0+ (1,0) [0|255] ""  APM,BCM,CCU_F,CCU_R,ETG,LDM_L,LDM_R,TRM,XGW_Body
 SG_ PSM_D_usrData5 : 63|8@0+ (1,0) [0|255] ""  APM,BCM,CCU_F,CCU_R,ETG,LDM_L,LDM_R,TRM,XGW_Body

BO_ 1339 TRM_NM: 8 TRM
SG_ TRM_srcNodeID : 7|8@0+ (1,0) [0|255] ""  LDM_R,LDM_L,XGW_Body,BCM,ETG,APM,CCU_F,PSM_D,CCU_R
SG_ TRM_CtrlBitVector : 15|8@0+ (1,0) [0|255] ""  LDM_R,LDM_L,XGW_Body,BCM,ETG,APM,CCU_F,PSM_D,CCU_R
SG_ TRM_usrData0 : 23|8@0+ (1,0) [0|255] ""  LDM_R,LDM_L,XGW_Body,BCM,ETG,APM,CCU_F,PSM_D,CCU_R
SG_ TRM_usrData1 : 31|8@0+ (1,0) [0|255] ""  LDM_R,LDM_L,XGW_Body,BCM,ETG,APM,CCU_F,PSM_D,CCU_R
SG_ TRM_usrData2 : 39|8@0+ (1,0) [0|255] ""  LDM_R,LDM_L,XGW_Body,BCM,ETG,APM,CCU_F,PSM_D,CCU_R
SG_ TRM_usrData3 : 47|8@0+ (1,0) [0|255] ""  LDM_R,LDM_L,XGW_Body,BCM,ETG,APM,CCU_F,PSM_D,CCU_R
SG_ TRM_usrData4 : 55|8@0+ (1,0) [0|255] ""  LDM_R,LDM_L,XGW_Body,BCM,ETG,APM,CCU_F,PSM_D,CCU_R
SG_ TRM_usrData5 : 63|8@0+ (1,0) [0|255] ""  LDM_R,LDM_L,XGW_Body,BCM,ETG,APM,CCU_F,PSM_D,CCU_R

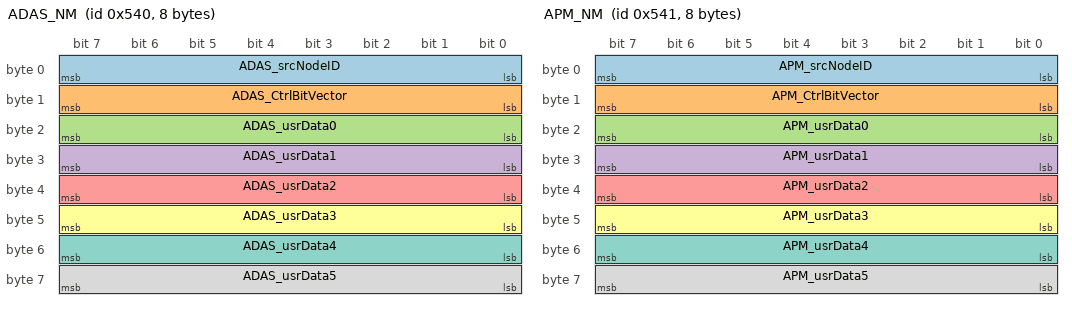
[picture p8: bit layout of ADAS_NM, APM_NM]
BO_ 1344 ADAS_NM: 8 ADAS_Body
 SG_ ADAS_srcNodeID : 7|8@0+ (1,0) [0|255] ""  ACM,APM,BCM,BCM_BPM,CCU_F,CCU_R,ETG,LDM_L,LDM_R,OCS_P,PSM_D,SHVU_F,SHVU_R,TRM,XGW_Body
 SG_ ADAS_CtrlBitVector : 15|8@0+ (1,0) [0|255] "-"  ACM,APM,BCM,BCM_BPM,CCU_F,CCU_R,ETG,LDM_L,LDM_R,OCS_P,PSM_D,SHVU_F,SHVU_R,TRM,XGW_Body
 SG_ ADAS_usrData0 : 23|8@0+ (1,0) [0|255] ""  ACM,APM,BCM,BCM_BPM,CCU_F,CCU_R,ETG,LDM_L,LDM_R,OCS_P,PSM_D,SHVU_F,SHVU_R,TRM,XGW_Body
 SG_ ADAS_usrData1 : 31|8@0+ (1,0) [0|255] ""  ACM,APM,BCM,BCM_BPM,CCU_F,CCU_R,ETG,LDM_L,LDM_R,OCS_P,PSM_D,SHVU_F,SHVU_R,TRM,XGW_Body
 SG_ ADAS_usrData2 : 39|8@0+ (1,0) [0|255] ""  ACM,APM,BCM,BCM_BPM,CCU_F,CCU_R,ETG,LDM_L,LDM_R,OCS_P,PSM_D,SHVU_F,SHVU_R,TRM,XGW_Body
 SG_ ADAS_usrData3 : 47|8@0+ (1,0) [0|255] "-"  ACM,APM,BCM,BCM_BPM,CCU_F,CCU_R,ETG,LDM_L,LDM_R,OCS_P,PSM_D,SHVU_F,SHVU_R,TRM,XGW_Body
 SG_ ADAS_usrData4 : 55|8@0+ (1,0) [0|255] "-"  ACM,APM,BCM,BCM_BPM,CCU_F,CCU_R,ETG,LDM_L,LDM_R,OCS_P,PSM_D,SHVU_F,SHVU_R,TRM,XGW_Body
 SG_ ADAS_usrData5 : 63|8@0+ (1,0) [0|255] "-"  ACM,APM,BCM,BCM_BPM,CCU_F,CCU_R,ETG,LDM_L,LDM_R,OCS_P,PSM_D,SHVU_F,SHVU_R,TRM,XGW_Body

BO_ 1345 APM_NM: 8 APM
 SG_ APM_srcNodeID : 7|8@0+ (1,0) [0|255] ""  BCM,CCU_F,CCU_R,ETG,LDM_L,LDM_R,PSM_D,TRM,XGW_Body
 SG_ APM_CtrlBitVector : 15|8@0+ (1,0) [0|255] ""  BCM,CCU_F,CCU_R,ETG,LDM_L,LDM_R,PSM_D,TRM,XGW_Body
 SG_ APM_usrData0 : 23|8@0+ (1,0) [0|255] ""  BCM,CCU_F,CCU_R,ETG,LDM_L,LDM_R,PSM_D,TRM,XGW_Body
 SG_ APM_usrData1 : 31|8@0+ (1,0) [0|255] ""  BCM,CCU_F,CCU_R,ETG,LDM_L,LDM_R,PSM_D,TRM,XGW_Body
 SG_ APM_usrData2 : 39|8@0+ (1,0) [0|255] ""  BCM,CCU_F,CCU_R,ETG,LDM_L,LDM_R,PSM_D,TRM,XGW_Body
 SG_ APM_usrData3 : 47|8@0+ (1,0) [0|255] ""  BCM,CCU_F,CCU_R,ETG,LDM_L,LDM_R,PSM_D,TRM,XGW_Body
 SG_ APM_usrData4 : 55|8@0+ (1,0) [0|255] ""  BCM,CCU_F,CCU_R,ETG,LDM_L,LDM_R,PSM_D,TRM,XGW_Body
 SG_ APM_usrData5 : 63|8@0+ (1,0) [0|255] ""  BCM,CCU_F,CCU_R,ETG,LDM_L,LDM_R,PSM_D,TRM,XGW_Body

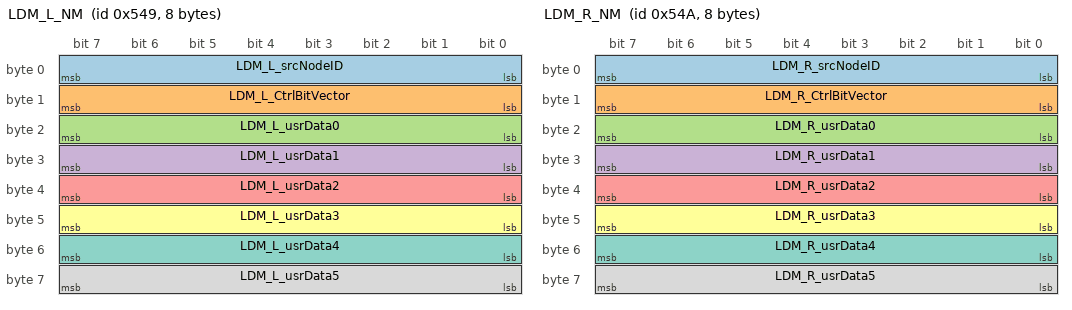
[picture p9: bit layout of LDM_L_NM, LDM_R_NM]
BO_ 1353 LDM_L_NM: 8 LDM_L
 SG_ LDM_L_srcNodeID : 7|8@0+ (1,0) [0|255] ""  APM,BCM,CCU_F,CCU_R,ETG,PSM_D,TRM,XGW_Body
 SG_ LDM_L_CtrlBitVector : 15|8@0+ (1,0) [0|255] ""  APM,BCM,CCU_F,CCU_R,ETG,PSM_D,TRM,XGW_Body
 SG_ LDM_L_usrData0 : 23|8@0+ (1,0) [0|255] ""  APM,BCM,CCU_F,CCU_R,ETG,PSM_D,TRM,XGW_Body
 SG_ LDM_L_usrData1 : 31|8@0+ (1,0) [0|255] ""  APM,BCM,CCU_F,CCU_R,ETG,PSM_D,TRM,XGW_Body
 SG_ LDM_L_usrData2 : 39|8@0+ (1,0) [0|255] ""  APM,BCM,CCU_F,CCU_R,ETG,PSM_D,TRM,XGW_Body
 SG_ LDM_L_usrData3 : 47|8@0+ (1,0) [0|255] ""  APM,BCM,CCU_F,CCU_R,ETG,PSM_D,TRM,XGW_Body
 SG_ LDM_L_usrData4 : 55|8@0+ (1,0) [0|255] ""  APM,BCM,CCU_F,CCU_R,ETG,PSM_D,TRM,XGW_Body
 SG_ LDM_L_usrData5 : 63|8@0+ (1,0) [0|255] ""  APM,BCM,CCU_F,CCU_R,ETG,PSM_D,TRM,XGW_Body

BO_ 1354 LDM_R_NM: 8 LDM_R
 SG_ LDM_R_srcNodeID : 7|8@0+ (1,0) [0|255] ""  APM,BCM,CCU_F,CCU_R,ETG,LDM_L,PSM_D,TRM,XGW_Body
 SG_ LDM_R_CtrlBitVector : 15|8@0+ (1,0) [0|255] ""  APM,BCM,CCU_F,CCU_R,ETG,LDM_L,PSM_D,TRM,XGW_Body
 SG_ LDM_R_usrData0 : 23|8@0+ (1,0) [0|255] ""  APM,BCM,CCU_F,CCU_R,ETG,LDM_L,PSM_D,TRM,XGW_Body
 SG_ LDM_R_usrData1 : 31|8@0+ (1,0) [0|255] ""  APM,BCM,CCU_F,CCU_R,ETG,LDM_L,PSM_D,TRM,XGW_Body
 SG_ LDM_R_usrData2 : 39|8@0+ (1,0) [0|255] ""  APM,BCM,CCU_F,CCU_R,ETG,LDM_L,PSM_D,TRM,XGW_Body
 SG_ LDM_R_usrData3 : 47|8@0+ (1,0) [0|255] ""  APM,BCM,CCU_F,CCU_R,ETG,LDM_L,PSM_D,TRM,XGW_Body
 SG_ LDM_R_usrData4 : 55|8@0+ (1,0) [0|255] ""  APM,BCM,CCU_F,CCU_R,ETG,LDM_L,PSM_D,TRM,XGW_Body
 SG_ LDM_R_usrData5 : 63|8@0+ (1,0) [0|255] ""  APM,BCM,CCU_F,CCU_R,ETG,LDM_L,PSM_D,TRM,XGW_Body

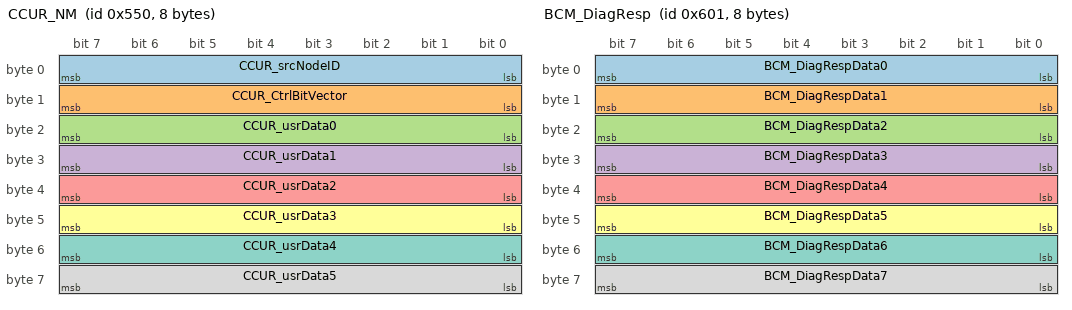
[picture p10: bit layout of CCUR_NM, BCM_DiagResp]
BO_ 1360 CCUR_NM: 8 CCU_R
 SG_ CCUR_srcNodeID : 7|8@0+ (1,0) [0|255] ""  APM,BCM,CCU_F,ETG,LDM_L,LDM_R,PSM_D,TRM,XGW_Body
 SG_ CCUR_CtrlBitVector : 15|8@0+ (1,0) [0|255] ""  APM,BCM,CCU_F,ETG,LDM_L,LDM_R,PSM_D,TRM,XGW_Body
 SG_ CCUR_usrData0 : 23|8@0+ (1,0) [0|255] ""  APM,BCM,CCU_F,ETG,LDM_L,LDM_R,PSM_D,TRM,XGW_Body
 SG_ CCUR_usrData1 : 31|8@0+ (1,0) [0|255] ""  APM,BCM,CCU_F,ETG,LDM_L,LDM_R,PSM_D,TRM,XGW_Body
 SG_ CCUR_usrData2 : 39|8@0+ (1,0) [0|255] ""  APM,BCM,CCU_F,ETG,LDM_L,LDM_R,PSM_D,TRM,XGW_Body
 SG_ CCUR_usrData3 : 47|8@0+ (1,0) [0|255] ""  APM,BCM,CCU_F,ETG,LDM_L,LDM_R,PSM_D,TRM,XGW_Body
 SG_ CCUR_usrData4 : 55|8@0+ (1,0) [0|255] ""  APM,BCM,CCU_F,ETG,LDM_L,LDM_R,PSM_D,TRM,XGW_Body
 SG_ CCUR_usrData5 : 63|8@0+ (1,0) [0|255] ""  APM,BCM,CCU_F,ETG,LDM_L,LDM_R,PSM_D,TRM,XGW_Body

BO_ 1537 BCM_DiagResp: 8 BCM
 SG_ BCM_DiagRespData0 : 7|8@0+ (1,0) [0|255] ""  XGW_Body
 SG_ BCM_DiagRespData1 : 15|8@0+ (1,0) [0|255] "-"  XGW_Body
 SG_ BCM_DiagRespData2 : 23|8@0+ (1,0) [0|255] ""  XGW_Body
 SG_ BCM_DiagRespData3 : 31|8@0+ (1,0) [0|255] ""  XGW_Body
 SG_ BCM_DiagRespData4 : 39|8@0+ (1,0) [0|255] ""  XGW_Body
 SG_ BCM_DiagRespData5 : 47|8@0+ (1,0) [0|255] ""  XGW_Body
 SG_ BCM_DiagRespData6 : 55|8@0+ (1,0) [0|255] "-"  XGW_Body
 SG_ BCM_DiagRespData7 : 63|8@0+ (1,0) [0|255] ""  XGW_Body

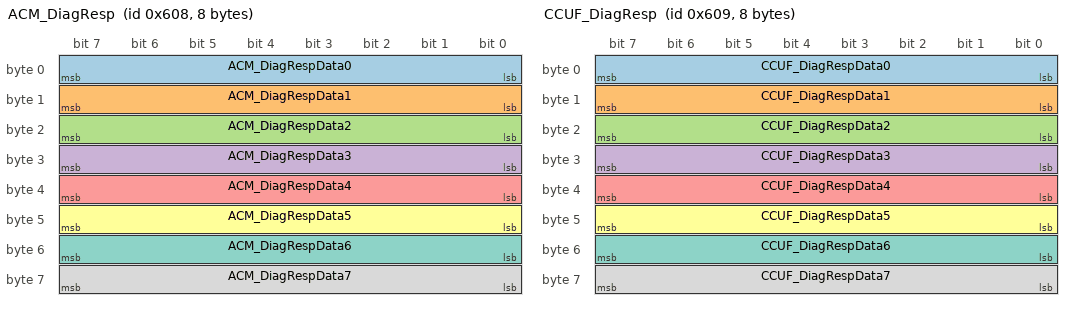
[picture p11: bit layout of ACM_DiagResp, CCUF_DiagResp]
BO_ 1544 ACM_DiagResp: 8 ACM
 SG_ ACM_DiagRespData0 : 7|8@0+ (1,0) [0|255] ""  XGW_Body
 SG_ ACM_DiagRespData1 : 15|8@0+ (1,0) [0|255] "-"  XGW_Body
 SG_ ACM_DiagRespData2 : 23|8@0+ (1,0) [0|255] ""  XGW_Body
 SG_ ACM_DiagRespData3 : 31|8@0+ (1,0) [0|255] "-"  XGW_Body
 SG_ ACM_DiagRespData4 : 39|8@0+ (1,0) [0|255] ""  XGW_Body
 SG_ ACM_DiagRespData5 : 47|8@0+ (1,0) [0|255] "-"  XGW_Body
 SG_ ACM_DiagRespData6 : 55|8@0+ (1,0) [0|255] ""  XGW_Body
 SG_ ACM_DiagRespData7 : 63|8@0+ (1,0) [0|255] "-"  XGW_Body

BO_ 1545 CCUF_DiagResp: 8 CCU_F
 SG_ CCUF_DiagRespData0 : 7|8@0+ (1,0) [0|255] ""  XGW_Body
 SG_ CCUF_DiagRespData1 : 15|8@0+ (1,0) [0|255] "-"  XGW_Body
 SG_ CCUF_DiagRespData2 : 23|8@0+ (1,0) [0|255] "-"  XGW_Body
 SG_ CCUF_DiagRespData3 : 31|8@0+ (1,0) [0|255] ""  XGW_Body
 SG_ CCUF_DiagRespData4 : 39|8@0+ (1,0) [0|255] ""  XGW_Body
 SG_ CCUF_DiagRespData5 : 47|8@0+ (1,0) [0|255] "-"  XGW_Body
 SG_ CCUF_DiagRespData6 : 55|8@0+ (1,0) [0|255] "-"  XGW_Body
 SG_ CCUF_DiagRespData7 : 63|8@0+ (1,0) [0|255] ""  XGW_Body

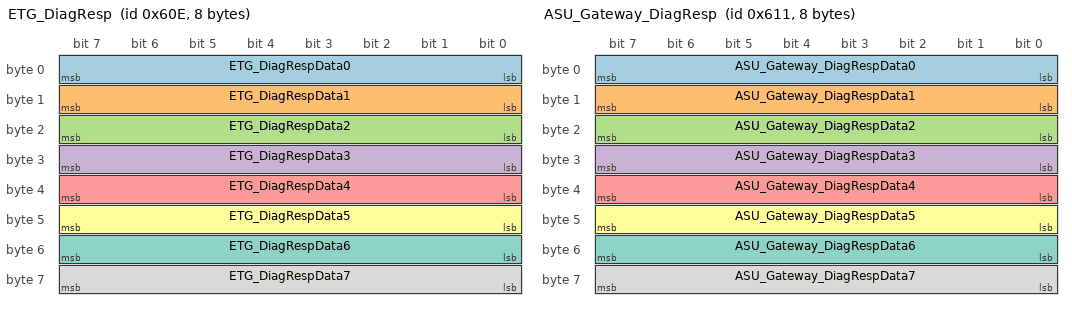
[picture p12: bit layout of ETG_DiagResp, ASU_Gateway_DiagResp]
BO_ 1550 ETG_DiagResp: 8 ETG
 SG_ ETG_DiagRespData0 : 7|8@0+ (1,0) [0|255] ""  XGW_Body
 SG_ ETG_DiagRespData1 : 15|8@0+ (1,0) [0|255] ""  XGW_Body
 SG_ ETG_DiagRespData2 : 23|8@0+ (1,0) [0|255] ""  XGW_Body
 SG_ ETG_DiagRespData3 : 31|8@0+ (1,0) [0|255] "-"  XGW_Body
 SG_ ETG_DiagRespData4 : 39|8@0+ (1,0) [0|255] ""  XGW_Body
 SG_ ETG_DiagRespData5 : 47|8@0+ (1,0) [0|255] ""  XGW_Body
 SG_ ETG_DiagRespData6 : 55|8@0+ (1,0) [0|255] ""  XGW_Body
 SG_ ETG_DiagRespData7 : 63|8@0+ (1,0) [0|255] ""  XGW_Body

BO_ 1553 ASU_Gateway_DiagResp: 8 ASU_Gateway
 SG_ ASU_Gateway_DiagRespData0 : 7|8@0+ (1,0) [0|255] "-"  XGW_Body
 SG_ ASU_Gateway_DiagRespData1 : 15|8@0+ (1,0) [0|255] "-"  XGW_Body
 SG_ ASU_Gateway_DiagRespData2 : 23|8@0+ (1,0) [0|255] "-"  XGW_Body
 SG_ ASU_Gateway_DiagRespData3 : 31|8@0+ (1,0) [0|255] "-"  XGW_Body
 SG_ ASU_Gateway_DiagRespData4 : 39|8@0+ (1,0) [0|255] "-"  XGW_Body
 SG_ ASU_Gateway_DiagRespData5 : 47|8@0+ (1,0) [0|255] "-"  XGW_Body
 SG_ ASU_Gateway_DiagRespData6 : 55|8@0+ (1,0) [0|255] "-"  XGW_Body
 SG_ ASU_Gateway_DiagRespData7 : 63|8@0+ (1,0) [0|255] "-"  XGW_Body

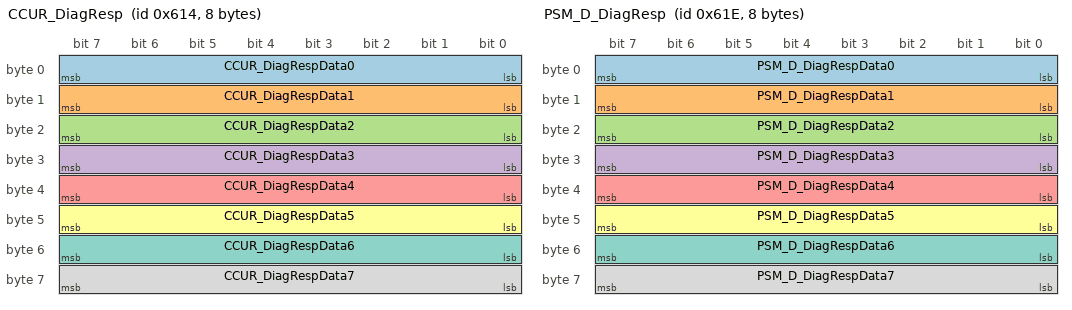
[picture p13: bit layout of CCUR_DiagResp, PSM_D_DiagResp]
BO_ 1556 CCUR_DiagResp: 8 CCU_R
 SG_ CCUR_DiagRespData0 : 7|8@0+ (1,0) [0|255] ""  XGW_Body
 SG_ CCUR_DiagRespData1 : 15|8@0+ (1,0) [0|255] ""  XGW_Body
 SG_ CCUR_DiagRespData2 : 23|8@0+ (1,0) [0|255] ""  XGW_Body
 SG_ CCUR_DiagRespData3 : 31|8@0+ (1,0) [0|255] ""  XGW_Body
 SG_ CCUR_DiagRespData4 : 39|8@0+ (1,0) [0|255] "-"  XGW_Body
 SG_ CCUR_DiagRespData5 : 47|8@0+ (1,0) [0|255] ""  XGW_Body
 SG_ CCUR_DiagRespData6 : 55|8@0+ (1,0) [0|255] "-"  XGW_Body
 SG_ CCUR_DiagRespData7 : 63|8@0+ (1,0) [0|255] ""  XGW_Body

BO_ 1566 PSM_D_DiagResp: 8 PSM_D
 SG_ PSM_D_DiagRespData0 : 7|8@0+ (1,0) [0|255] ""  XGW_Body
 SG_ PSM_D_DiagRespData1 : 15|8@0+ (1,0) [0|255] ""  XGW_Body
 SG_ PSM_D_DiagRespData2 : 23|8@0+ (1,0) [0|255] ""  XGW_Body
 SG_ PSM_D_DiagRespData3 : 31|8@0+ (1,0) [0|255] "-"  XGW_Body
 SG_ PSM_D_DiagRespData4 : 39|8@0+ (1,0) [0|255] ""  XGW_Body
 SG_ PSM_D_DiagRespData5 : 47|8@0+ (1,0) [0|255] ""  XGW_Body
 SG_ PSM_D_DiagRespData6 : 55|8@0+ (1,0) [0|255] ""  XGW_Body
 SG_ PSM_D_DiagRespData7 : 63|8@0+ (1,0) [0|255] ""  XGW_Body

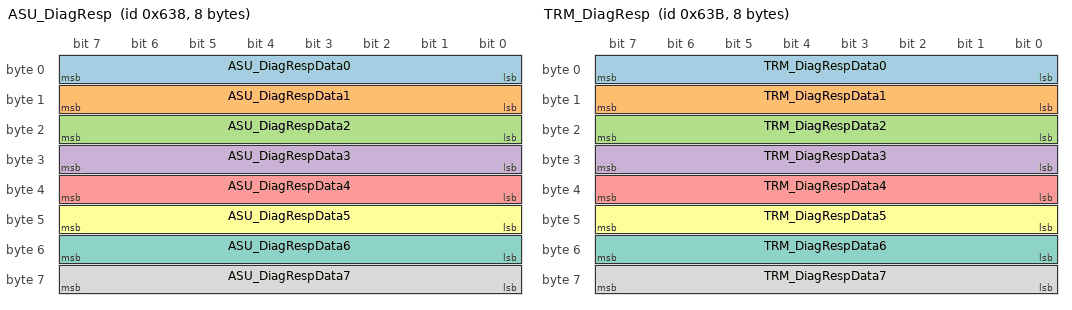
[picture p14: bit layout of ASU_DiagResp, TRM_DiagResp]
BO_ 1592 ASU_DiagResp: 8 ASU_Gateway
 SG_ ASU_DiagRespData0 : 7|8@0+ (1,0) [0|255] "-"  XGW_Body
 SG_ ASU_DiagRespData1 : 15|8@0+ (1,0) [0|255] "-"  XGW_Body
 SG_ ASU_DiagRespData2 : 23|8@0+ (1,0) [0|255] "-"  XGW_Body
 SG_ ASU_DiagRespData3 : 31|8@0+ (1,0) [0|255] "-"  XGW_Body
 SG_ ASU_DiagRespData4 : 39|8@0+ (1,0) [0|255] "-"  XGW_Body
 SG_ ASU_DiagRespData5 : 47|8@0+ (1,0) [0|255] "-"  XGW_Body
 SG_ ASU_DiagRespData6 : 55|8@0+ (1,0) [0|255] "-"  XGW_Body
 SG_ ASU_DiagRespData7 : 63|8@0+ (1,0) [0|255] "-"  XGW_Body

BO_ 1595 TRM_DiagResp: 8 TRM
 SG_ TRM_DiagRespData0 : 7|8@0+ (1,0) [0|255] ""  XGW_Body
 SG_ TRM_DiagRespData1 : 15|8@0+ (1,0) [0|255] ""  XGW_Body
 SG_ TRM_DiagRespData2 : 23|8@0+ (1,0) [0|255] ""  XGW_Body
 SG_ TRM_DiagRespData3 : 31|8@0+ (1,0) [0|255] "-"  XGW_Body
 SG_ TRM_DiagRespData4 : 39|8@0+ (1,0) [0|255] "-"  XGW_Body
 SG_ TRM_DiagRespData5 : 47|8@0+ (1,0) [0|255] "-"  XGW_Body
 SG_ TRM_DiagRespData6 : 55|8@0+ (1,0) [0|255] ""  XGW_Body
 SG_ TRM_DiagRespData7 : 63|8@0+ (1,0) [0|255] "-"  XGW_Body

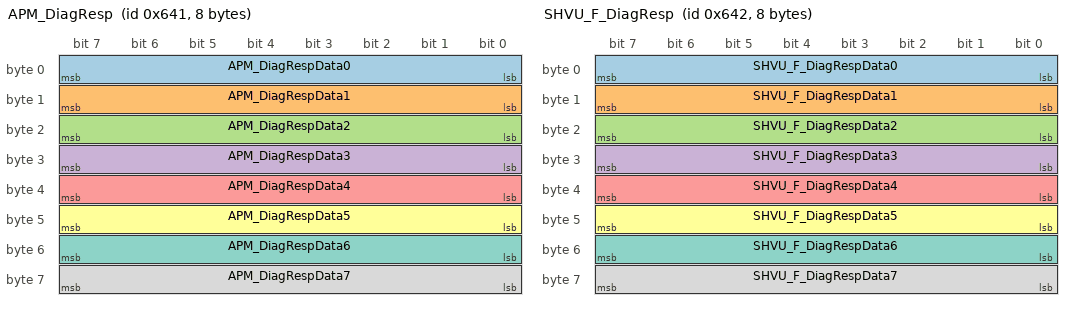
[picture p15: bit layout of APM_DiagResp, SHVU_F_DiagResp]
BO_ 1601 APM_DiagResp: 8 APM
 SG_ APM_DiagRespData0 : 7|8@0+ (1,0) [0|255] ""  XGW_Body
 SG_ APM_DiagRespData1 : 15|8@0+ (1,0) [0|255] ""  XGW_Body
 SG_ APM_DiagRespData2 : 23|8@0+ (1,0) [0|255] ""  XGW_Body
 SG_ APM_DiagRespData3 : 31|8@0+ (1,0) [0|255] ""  XGW_Body
 SG_ APM_DiagRespData4 : 39|8@0+ (1,0) [0|255] "-"  XGW_Body
 SG_ APM_DiagRespData5 : 47|8@0+ (1,0) [0|255] ""  XGW_Body
 SG_ APM_DiagRespData6 : 55|8@0+ (1,0) [0|255] "-"  XGW_Body
 SG_ APM_DiagRespData7 : 63|8@0+ (1,0) [0|255] ""  XGW_Body

BO_ 1602 SHVU_F_DiagResp: 8 SHVU_F
 SG_ SHVU_F_DiagRespData0 : 7|8@0+ (1,0) [0|255] ""  XGW_Body
 SG_ SHVU_F_DiagRespData1 : 15|8@0+ (1,0) [0|255] ""  XGW_Body
 SG_ SHVU_F_DiagRespData2 : 23|8@0+ (1,0) [0|255] "-"  XGW_Body
 SG_ SHVU_F_DiagRespData3 : 31|8@0+ (1,0) [0|255] ""  XGW_Body
 SG_ SHVU_F_DiagRespData4 : 39|8@0+ (1,0) [0|255] ""  XGW_Body
 SG_ SHVU_F_DiagRespData5 : 47|8@0+ (1,0) [0|255] ""  XGW_Body
 SG_ SHVU_F_DiagRespData6 : 55|8@0+ (1,0) [0|255] "-"  XGW_Body
 SG_ SHVU_F_DiagRespData7 : 63|8@0+ (1,0) [0|255] ""  XGW_Body

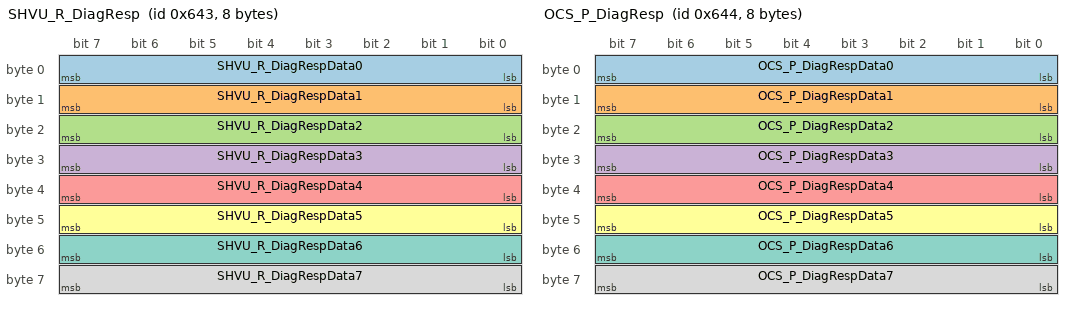
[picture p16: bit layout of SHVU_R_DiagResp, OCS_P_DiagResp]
BO_ 1603 SHVU_R_DiagResp: 8 SHVU_R
 SG_ SHVU_R_DiagRespData0 : 7|8@0+ (1,0) [0|255] ""  XGW_Body
 SG_ SHVU_R_DiagRespData1 : 15|8@0+ (1,0) [0|255] "-"  XGW_Body
 SG_ SHVU_R_DiagRespData2 : 23|8@0+ (1,0) [0|255] ""  XGW_Body
 SG_ SHVU_R_DiagRespData3 : 31|8@0+ (1,0) [0|255] "-"  XGW_Body
 SG_ SHVU_R_DiagRespData4 : 39|8@0+ (1,0) [0|255] "-"  XGW_Body
 SG_ SHVU_R_DiagRespData5 : 47|8@0+ (1,0) [0|255] ""  XGW_Body
 SG_ SHVU_R_DiagRespData6 : 55|8@0+ (1,0) [0|255] "-"  XGW_Body
 SG_ SHVU_R_DiagRespData7 : 63|8@0+ (1,0) [0|255] ""  XGW_Body

BO_ 1604 OCS_P_DiagResp: 8 OCS_P
 SG_ OCS_P_DiagRespData0 : 7|8@0+ (1,0) [0|255] ""  XGW_Body
 SG_ OCS_P_DiagRespData1 : 15|8@0+ (1,0) [0|255] "-"  XGW_Body
 SG_ OCS_P_DiagRespData2 : 23|8@0+ (1,0) [0|255] ""  XGW_Body
 SG_ OCS_P_DiagRespData3 : 31|8@0+ (1,0) [0|255] "-"  XGW_Body
 SG_ OCS_P_DiagRespData4 : 39|8@0+ (1,0) [0|255] ""  XGW_Body
 SG_ OCS_P_DiagRespData5 : 47|8@0+ (1,0) [0|255] ""  XGW_Body
 SG_ OCS_P_DiagRespData6 : 55|8@0+ (1,0) [0|255] ""  XGW_Body
 SG_ OCS_P_DiagRespData7 : 63|8@0+ (1,0) [0|255] ""  XGW_Body

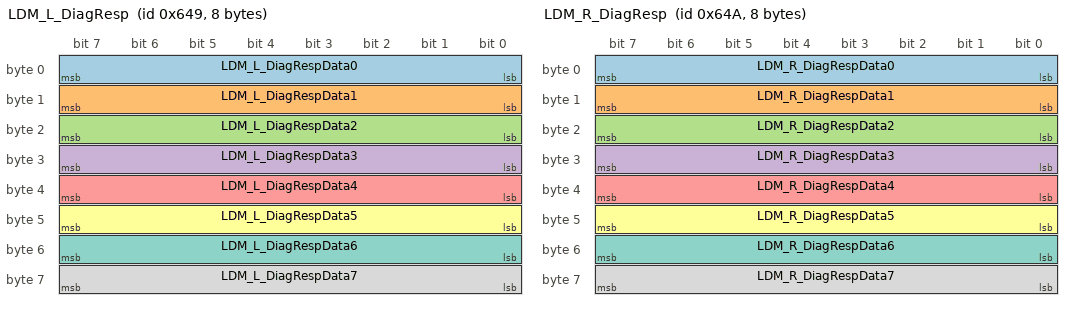
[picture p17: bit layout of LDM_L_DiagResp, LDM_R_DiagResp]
BO_ 1609 LDM_L_DiagResp: 8 LDM_L
 SG_ LDM_L_DiagRespData0 : 7|8@0+ (1,0) [0|255] "-"  XGW_Body
 SG_ LDM_L_DiagRespData1 : 15|8@0+ (1,0) [0|255] ""  XGW_Body
 SG_ LDM_L_DiagRespData2 : 23|8@0+ (1,0) [0|255] "-"  XGW_Body
 SG_ LDM_L_DiagRespData3 : 31|8@0+ (1,0) [0|255] ""  XGW_Body
 SG_ LDM_L_DiagRespData4 : 39|8@0+ (1,0) [0|255] ""  XGW_Body
 SG_ LDM_L_DiagRespData5 : 47|8@0+ (1,0) [0|255] "-"  XGW_Body
 SG_ LDM_L_DiagRespData6 : 55|8@0+ (1,0) [0|255] ""  XGW_Body
 SG_ LDM_L_DiagRespData7 : 63|8@0+ (1,0) [0|255] "-"  XGW_Body

BO_ 1610 LDM_R_DiagResp: 8 LDM_R
 SG_ LDM_R_DiagRespData0 : 7|8@0+ (1,0) [0|255] ""  XGW_Body
 SG_ LDM_R_DiagRespData1 : 15|8@0+ (1,0) [0|255] "-"  XGW_Body
 SG_ LDM_R_DiagRespData2 : 23|8@0+ (1,0) [0|255] ""  XGW_Body
 SG_ LDM_R_DiagRespData3 : 31|8@0+ (1,0) [0|255] ""  XGW_Body
 SG_ LDM_R_DiagRespData4 : 39|8@0+ (1,0) [0|255] "-"  XGW_Body
 SG_ LDM_R_DiagRespData5 : 47|8@0+ (1,0) [0|255] ""  XGW_Body
 SG_ LDM_R_DiagRespData6 : 55|8@0+ (1,0) [0|255] ""  XGW_Body
 SG_ LDM_R_DiagRespData7 : 63|8@0+ (1,0) [0|255] "-"  XGW_Body

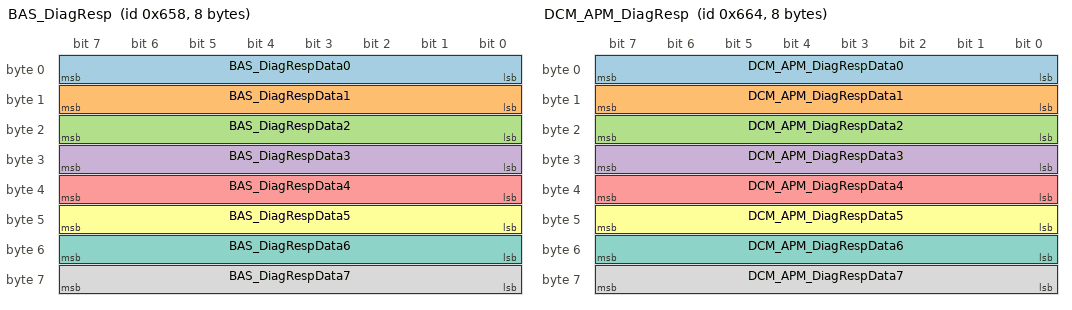
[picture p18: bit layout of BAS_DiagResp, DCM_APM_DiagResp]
BO_ 1624 BAS_DiagResp: 8 BCM
 SG_ BAS_DiagRespData0 : 7|8@0+ (1,0) [0|255] ""  XGW_Body
 SG_ BAS_DiagRespData1 : 15|8@0+ (1,0) [0|255] ""  XGW_Body
 SG_ BAS_DiagRespData2 : 23|8@0+ (1,0) [0|255] ""  XGW_Body
 SG_ BAS_DiagRespData3 : 31|8@0+ (1,0) [0|255] ""  XGW_Body
 SG_ BAS_DiagRespData4 : 39|8@0+ (1,0) [0|255] ""  XGW_Body
 SG_ BAS_DiagRespData5 : 47|8@0+ (1,0) [0|255] ""  XGW_Body
 SG_ BAS_DiagRespData6 : 55|8@0+ (1,0) [0|255] ""  XGW_Body
 SG_ BAS_DiagRespData7 : 63|8@0+ (1,0) [0|255] ""  XGW_Body

BO_ 1636 DCM_APM_DiagResp: 8 APM
 SG_ DCM_APM_DiagRespData0 : 7|8@0+ (1,0) [0|255] "-"  XGW_Body
 SG_ DCM_APM_DiagRespData1 : 15|8@0+ (1,0) [0|255] "-"  XGW_Body
 SG_ DCM_APM_DiagRespData2 : 23|8@0+ (1,0) [0|255] ""  XGW_Body
 SG_ DCM_APM_DiagRespData3 : 31|8@0+ (1,0) [0|255] "-"  XGW_Body
 SG_ DCM_APM_DiagRespData4 : 39|8@0+ (1,0) [0|255] ""  XGW_Body
 SG_ DCM_APM_DiagRespData5 : 47|8@0+ (1,0) [0|255] "-"  XGW_Body
 SG_ DCM_APM_DiagRespData6 : 55|8@0+ (1,0) [0|255] "-"  XGW_Body
 SG_ DCM_APM_DiagRespData7 : 63|8@0+ (1,0) [0|255] ""  XGW_Body

BO_ 1659 BCM_BPM_DiagResp: 8 BCM
 SG_ BCM_BPM_DiagRespData0 : 7|8@0+ (1,0) [0|255] ""  XGW_Body
 SG_ BCM_BPM_DiagRespData1 : 15|8@0+ (1,0) [0|255] "-"  XGW_Body
 SG_ BCM_BPM_DiagRespData2 : 23|8@0+ (1,0) [0|255] ""  XGW_Body
 SG_ BCM_BPM_DiagRespData3 : 31|8@0+ (1,0) [0|255] ""  XGW_Body
 SG_ BCM_BPM_DiagRespData4 : 39|8@0+ (1,0) [0|255] "-"  XGW_Body
 SG_ BCM_BPM_DiagRespData5 : 47|8@0+ (1,0) [0|255] ""  XGW_Body
 SG_ BCM_BPM_DiagRespData6 : 55|8@0+ (1,0) [0|255] "-"  XGW_Body
 SG_ BCM_BPM_DiagRespData7 : 63|8@0+ (1,0) [0|255] ""  XGW_Body

BO_ 1665 BCM_DiagReq: 8 XGW_Body
 SG_ BCM_DiagReqData0 : 7|8@0+ (1,0) [0|255] ""  BCM
 SG_ BCM_DiagReqData1 : 15|8@0+ (1,0) [0|255] ""  BCM
 SG_ BCM_DiagReqData2 : 23|8@0+ (1,0) [0|255] ""  BCM
 SG_ BCM_DiagReqData3 : 31|8@0+ (1,0) [0|255] ""  BCM
 SG_ BCM_DiagReqData4 : 39|8@0+ (1,0) [0|255] ""  BCM
 SG_ BCM_DiagReqData5 : 47|8@0+ (1,0) [0|255] ""  BCM
 SG_ BCM_DiagReqData6 : 55|8@0+ (1,0) [0|255] "-"  BCM
 SG_ BCM_DiagReqData7 : 63|8@0+ (1,0) [0|255] "-"  BCM

BO_ 1672 ACM_DiagReq: 8 XGW_Body
 SG_ ACM_DiagReqData0 : 7|8@0+ (1,0) [0|255] ""  ACM
 SG_ ACM_DiagReqData1 : 15|8@0+ (1,0) [0|255] ""  ACM
 SG_ ACM_DiagReqData2 : 23|8@0+ (1,0) [0|255] ""  ACM
 SG_ ACM_DiagReqData3 : 31|8@0+ (1,0) [0|255] "-"  ACM
 SG_ ACM_DiagReqData4 : 39|8@0+ (1,0) [0|255] ""  ACM
 SG_ ACM_DiagReqData5 : 47|8@0+ (1,0) [0|255] ""  ACM
 SG_ ACM_DiagReqData6 : 55|8@0+ (1,0) [0|255] "-"  ACM
 SG_ ACM_DiagReqData7 : 63|8@0+ (1,0) [0|255] ""  ACM

BO_ 1673 CCUF_DiagReq: 8 XGW_Body
 SG_ CCUF_DiagReqData0 : 7|8@0+ (1,0) [0|255] "-"  CCU_F
 SG_ CCUF_DiagReqData1 : 15|8@0+ (1,0) [0|255] ""  CCU_F
 SG_ CCUF_DiagReqData2 : 23|8@0+ (1,0) [0|255] ""  CCU_F
 SG_ CCUF_DiagReqData3 : 31|8@0+ (1,0) [0|255] ""  CCU_F
 SG_ CCUF_DiagReqData4 : 39|8@0+ (1,0) [0|255] ""  CCU_F
 SG_ CCUF_DiagReqData5 : 47|8@0+ (1,0) [0|255] ""  CCU_F
 SG_ CCUF_DiagReqData6 : 55|8@0+ (1,0) [0|255] ""  CCU_F
 SG_ CCUF_DiagReqData7 : 63|8@0+ (1,0) [0|255] ""  CCU_F

BO_ 1678 ETG_DiagReq: 8 XGW_Body
 SG_ ETG_DiagReqData0 : 7|8@0+ (1,0) [0|255] ""  ETG
 SG_ ETG_DiagReqData1 : 15|8@0+ (1,0) [0|255] ""  ETG
 SG_ ETG_DiagReqData2 : 23|8@0+ (1,0) [0|255] ""  ETG
 SG_ ETG_DiagReqData3 : 31|8@0+ (1,0) [0|255] ""  ETG
 SG_ ETG_DiagReqData4 : 39|8@0+ (1,0) [0|255] ""  ETG
 SG_ ETG_DiagReqData5 : 47|8@0+ (1,0) [0|255] ""  ETG
 SG_ ETG_DiagReqData6 : 55|8@0+ (1,0) [0|255] ""  ETG
 SG_ ETG_DiagReqData7 : 63|8@0+ (1,0) [0|255] "-"  ETG

BO_ 1681 ASU_Gateway_DiagReq: 8 XGW_Body
 SG_ ASU_Gateway_DiagReqData0 : 7|8@0+ (1,0) [0|255] "-"  ASU_Gateway
 SG_ ASU_Gateway_DiagReqData1 : 15|8@0+ (1,0) [0|255] "-"  ASU_Gateway
 SG_ ASU_Gateway_DiagReqData2 : 23|8@0+ (1,0) [0|255] "-"  ASU_Gateway
 SG_ ASU_Gateway_DiagReqData3 : 31|8@0+ (1,0) [0|255] "-"  ASU_Gateway
 SG_ ASU_Gateway_DiagReqData4 : 39|8@0+ (1,0) [0|255] "-"  ASU_Gateway
 SG_ ASU_Gateway_DiagReqData5 : 47|8@0+ (1,0) [0|255] "-"  ASU_Gateway
 SG_ ASU_Gateway_DiagReqData6 : 55|8@0+ (1,0) [0|255] "-"  ASU_Gateway
 SG_ ASU_Gateway_DiagReqData7 : 63|8@0+ (1,0) [0|255] "-"  ASU_Gateway

BO_ 1684 CCUR_DiagReq: 8 XGW_Body
 SG_ CCUR_DiagReqData0 : 7|8@0+ (1,0) [0|255] ""  CCU_R
 SG_ CCUR_DiagReqData1 : 15|8@0+ (1,0) [0|255] ""  CCU_R
 SG_ CCUR_DiagReqData2 : 23|8@0+ (1,0) [0|255] ""  CCU_R
 SG_ CCUR_DiagReqData3 : 31|8@0+ (1,0) [0|255] "-"  CCU_R
 SG_ CCUR_DiagReqData4 : 39|8@0+ (1,0) [0|255] "-"  CCU_R
 SG_ CCUR_DiagReqData5 : 47|8@0+ (1,0) [0|255] ""  CCU_R
 SG_ CCUR_DiagReqData6 : 55|8@0+ (1,0) [0|255] ""  CCU_R
 SG_ CCUR_DiagReqData7 : 63|8@0+ (1,0) [0|255] ""  CCU_R

BO_ 1694 PSM_D_DiagReq: 8 XGW_Body
 SG_ PSM_D_DiagReqData0 : 7|8@0+ (1,0) [0|255] "-"  PSM_D
 SG_ PSM_D_DiagReqData1 : 15|8@0+ (1,0) [0|255] ""  PSM_D
 SG_ PSM_D_DiagReqData2 : 23|8@0+ (1,0) [0|255] "-"  PSM_D
 SG_ PSM_D_DiagReqData3 : 31|8@0+ (1,0) [0|255] ""  PSM_D
 SG_ PSM_D_DiagReqData4 : 39|8@0+ (1,0) [0|255] ""  PSM_D
 SG_ PSM_D_DiagReqData5 : 47|8@0+ (1,0) [0|255] "-"  PSM_D
 SG_ PSM_D_DiagReqData6 : 55|8@0+ (1,0) [0|255] "-"  PSM_D
 SG_ PSM_D_DiagReqData7 : 63|8@0+ (1,0) [0|255] ""  PSM_D

BO_ 1723 TRM_DiagReq: 8 XGW_Body
 SG_ TRM_DiagReqData0 : 7|8@0+ (1,0) [0|255] ""  TRM
 SG_ TRM_DiagReqData1 : 15|8@0+ (1,0) [0|255] ""  TRM
 SG_ TRM_DiagReqData2 : 23|8@0+ (1,0) [0|255] "-"  TRM
 SG_ TRM_DiagReqData3 : 31|8@0+ (1,0) [0|255] "-"  TRM
 SG_ TRM_DiagReqData4 : 39|8@0+ (1,0) [0|255] "-"  TRM
 SG_ TRM_DiagReqData5 : 47|8@0+ (1,0) [0|255] ""  TRM
 SG_ TRM_DiagReqData6 : 55|8@0+ (1,0) [0|255] ""  TRM
 SG_ TRM_DiagReqData7 : 63|8@0+ (1,0) [0|255] "-"  TRM

BO_ 1729 APM_DiagReq: 8 XGW_Body
 SG_ APM_DiagReqData0 : 7|8@0+ (1,0) [0|255] ""  APM
 SG_ APM_DiagReqData1 : 15|8@0+ (1,0) [0|255] ""  APM
 SG_ APM_DiagReqData2 : 23|8@0+ (1,0) [0|255] "-"  APM
 SG_ APM_DiagReqData3 : 31|8@0+ (1,0) [0|255] ""  APM
 SG_ APM_DiagReqData4 : 39|8@0+ (1,0) [0|255] ""  APM
 SG_ APM_DiagReqData5 : 47|8@0+ (1,0) [0|255] "-"  APM
 SG_ APM_DiagReqData6 : 55|8@0+ (1,0) [0|255] ""  APM
 SG_ APM_DiagReqData7 : 63|8@0+ (1,0) [0|255] ""  APM

BO_ 1730 SHVU_F_DiagReq: 8 XGW_Body
 SG_ SHVU_F_DiagReqData0 : 7|8@0+ (1,0) [0|255] ""  SHVU_F
 SG_ SHVU_F_DiagReqData1 : 15|8@0+ (1,0) [0|255] ""  SHVU_F
 SG_ SHVU_F_DiagReqData2 : 23|8@0+ (1,0) [0|255] ""  SHVU_F
 SG_ SHVU_F_DiagReqData3 : 31|8@0+ (1,0) [0|255] "-"  SHVU_F
 SG_ SHVU_F_DiagReqData4 : 39|8@0+ (1,0) [0|255] ""  SHVU_F
 SG_ SHVU_F_DiagReqData5 : 47|8@0+ (1,0) [0|255] ""  SHVU_F
 SG_ SHVU_F_DiagReqData6 : 55|8@0+ (1,0) [0|255] "-"  SHVU_F
 SG_ SHVU_F_DiagReqData7 : 63|8@0+ (1,0) [0|255] ""  SHVU_F

BO_ 1731 SHVU_R_DiagReq: 8 XGW_Body
 SG_ SHVU_R_DiagReqData0 : 7|8@0+ (1,0) [0|255] ""  SHVU_R
 SG_ SHVU_R_DiagReqData1 : 15|8@0+ (1,0) [0|255] ""  SHVU_R
 SG_ SHVU_R_DiagReqData2 : 23|8@0+ (1,0) [0|255] ""  SHVU_R
 SG_ SHVU_R_DiagReqData3 : 31|8@0+ (1,0) [0|255] ""  SHVU_R
 SG_ SHVU_R_DiagReqData4 : 39|8@0+ (1,0) [0|255] ""  SHVU_R
 SG_ SHVU_R_DiagReqData5 : 47|8@0+ (1,0) [0|255] "-"  SHVU_R
 SG_ SHVU_R_DiagReqData6 : 55|8@0+ (1,0) [0|255] ""  SHVU_R
 SG_ SHVU_R_DiagReqData7 : 63|8@0+ (1,0) [0|255] ""  SHVU_R

BO_ 1732 OCS_P_DiagReq: 8 XGW_Body
 SG_ OCS_P_DiagReqData0 : 7|8@0+ (1,0) [0|255] "-"  OCS_P
 SG_ OCS_P_DiagReqData1 : 15|8@0+ (1,0) [0|255] ""  OCS_P
 SG_ OCS_P_DiagReqData2 : 23|8@0+ (1,0) [0|255] ""  OCS_P
 SG_ OCS_P_DiagReqData3 : 31|8@0+ (1,0) [0|255] ""  OCS_P
 SG_ OCS_P_DiagReqData4 : 39|8@0+ (1,0) [0|255] ""  OCS_P
 SG_ OCS_P_DiagReqData5 : 47|8@0+ (1,0) [0|255] ""  OCS_P
 SG_ OCS_P_DiagReqData6 : 55|8@0+ (1,0) [0|255] ""  OCS_P
 SG_ OCS_P_DiagReqData7 : 63|8@0+ (1,0) [0|255] "-"  OCS_P

BO_ 1737 LDM_L_DiagReq: 8 XGW_Body
 SG_ LDM_L_DiagReqData0 : 7|8@0+ (1,0) [0|255] "-"  LDM_L
 SG_ LDM_L_DiagReqData1 : 15|8@0+ (1,0) [0|255] ""  LDM_L
 SG_ LDM_L_DiagReqData2 : 23|8@0+ (1,0) [0|255] ""  LDM_L
 SG_ LDM_L_DiagReqData3 : 31|8@0+ (1,0) [0|255] ""  LDM_L
 SG_ LDM_L_DiagReqData4 : 39|8@0+ (1,0) [0|255] "-"  LDM_L
 SG_ LDM_L_DiagReqData5 : 47|8@0+ (1,0) [0|255] ""  LDM_L
 SG_ LDM_L_DiagReqData6 : 55|8@0+ (1,0) [0|255] ""  LDM_L
 SG_ LDM_L_DiagReqData7 : 63|8@0+ (1,0) [0|255] ""  LDM_L

BO_ 1738 LDM_R_DiagReq: 8 XGW_Body
 SG_ LDM_R_DiagReqData0 : 7|8@0+ (1,0) [0|255] ""  LDM_R
 SG_ LDM_R_DiagReqData1 : 15|8@0+ (1,0) [0|255] ""  LDM_R
 SG_ LDM_R_DiagReqData2 : 23|8@0+ (1,0) [0|255] ""  LDM_R
 SG_ LDM_R_DiagReqData3 : 31|8@0+ (1,0) [0|255] "-"  LDM_R
 SG_ LDM_R_DiagReqData4 : 39|8@0+ (1,0) [0|255] ""  LDM_R
 SG_ LDM_R_DiagReqData5 : 47|8@0+ (1,0) [0|255] ""  LDM_R
 SG_ LDM_R_DiagReqData6 : 55|8@0+ (1,0) [0|255] "-"  LDM_R
 SG_ LDM_R_DiagReqData7 : 63|8@0+ (1,0) [0|255] "-"  LDM_R

BO_ 1752 BAS_DiagReq: 8 XGW_Body
 SG_ BAS_DiagReqData0 : 7|8@0+ (1,0) [0|255] ""  BCM
 SG_ BAS_DiagReqData1 : 15|8@0+ (1,0) [0|255] ""  BCM
 SG_ BAS_DiagReqData2 : 23|8@0+ (1,0) [0|255] ""  BCM
 SG_ BAS_DiagReqData3 : 31|8@0+ (1,0) [0|255] ""  BCM
 SG_ BAS_DiagReqData4 : 39|8@0+ (1,0) [0|255] ""  BCM
 SG_ BAS_DiagReqData5 : 47|8@0+ (1,0) [0|255] ""  BCM
 SG_ BAS_DiagReqData6 : 55|8@0+ (1,0) [0|255] ""  BCM
 SG_ BAS_DiagReqData7 : 63|8@0+ (1,0) [0|255] ""  BCM

BO_ 1764 DCM_APM_DiagReq: 8 XGW_Body
 SG_ DCM_APM_DiagReqData0 : 7|8@0+ (1,0) [0|255] "-"  APM,BCM
 SG_ DCM_APM_DiagReqData1 : 15|8@0+ (1,0) [0|255] "-"  APM
 SG_ DCM_APM_DiagReqData2 : 23|8@0+ (1,0) [0|255] "-"  APM
 SG_ DCM_APM_DiagReqData3 : 31|8@0+ (1,0) [0|255] "-"  APM
 SG_ DCM_APM_DiagReqData4 : 39|8@0+ (1,0) [0|255] ""  APM
 SG_ DCM_APM_DiagReqData5 : 47|8@0+ (1,0) [0|255] ""  APM
 SG_ DCM_APM_DiagReqData6 : 55|8@0+ (1,0) [0|255] ""  APM
 SG_ DCM_APM_DiagReqData7 : 63|8@0+ (1,0) [0|255] ""  APM

BO_ 1775 DIAG_Req_All_CAN: 8 XGW_Body
 SG_ DiagReqAllCANData0 : 7|8@0+ (1,0) [0|255] "-"  ACM,APM,ASU_Gateway,BCM,BCM_BPM,CCU_F,CCU_R,ETG,LDM_L,LDM_R,OCS_P,PSM_D,TRM
 SG_ DiagReqAllCANData1 : 15|8@0+ (1,0) [0|255] ""  ACM,APM,ASU_Gateway,BCM,BCM_BPM,CCU_F,CCU_R,ETG,LDM_L,LDM_R,OCS_P,PSM_D,TRM
 SG_ DiagReqAllCANData2 : 23|8@0+ (1,0) [0|255] "-"  ACM,APM,ASU_Gateway,BCM,BCM_BPM,CCU_F,CCU_R,ETG,LDM_L,LDM_R,OCS_P,PSM_D,TRM
 SG_ DiagReqAllCANData3 : 31|8@0+ (1,0) [0|255] "-"  ACM,APM,ASU_Gateway,BCM,BCM_BPM,CCU_F,CCU_R,ETG,LDM_L,LDM_R,OCS_P,PSM_D,TRM
 SG_ DiagReqAllCANData4 : 39|8@0+ (1,0) [0|255] ""  ACM,APM,ASU_Gateway,BCM,BCM_BPM,CCU_F,CCU_R,ETG,LDM_L,LDM_R,OCS_P,PSM_D,TRM
 SG_ DiagReqAllCANData5 : 47|8@0+ (1,0) [0|255] ""  ACM,APM,ASU_Gateway,BCM,BCM_BPM,CCU_F,CCU_R,ETG,LDM_L,LDM_R,OCS_P,PSM_D,TRM
 SG_ DiagReqAllCANData6 : 55|8@0+ (1,0) [0|255] ""  ACM,APM,ASU_Gateway,BCM,BCM_BPM,CCU_F,CCU_R,ETG,LDM_L,LDM_R,OCS_P,PSM_D,TRM
 SG_ DiagReqAllCANData7 : 63|8@0+ (1,0) [0|255] ""  ACM,APM,ASU_Gateway,BCM,BCM_BPM,CCU_F,CCU_R,ETG,LDM_L,LDM_R,OCS_P,PSM_D,TRM

BO_ 1777 ASU_DiagReq: 8 XGW_Body
 SG_ ASU_DiagReqData0 : 7|8@0+ (1,0) [0|255] "-"  ASU_Gateway
 SG_ ASU_DiagReqData1 : 15|8@0+ (1,0) [0|255] "-"  ASU_Gateway
 SG_ ASU_DiagReqData2 : 23|8@0+ (1,0) [0|255] "-"  ASU_Gateway
 SG_ ASU_DiagReqData3 : 31|8@0+ (1,0) [0|255] "-"  ASU_Gateway
 SG_ ASU_DiagReqData4 : 39|8@0+ (1,0) [0|255] "-"  ASU_Gateway
 SG_ ASU_DiagReqData5 : 47|8@0+ (1,0) [0|255] "-"  ASU_Gateway
 SG_ ASU_DiagReqData6 : 55|8@0+ (1,0) [0|255] "-"  ASU_Gateway
 SG_ ASU_DiagReqData7 : 63|8@0+ (1,0) [0|255] "-"  ASU_Gateway

BO_ 1787 BCM_BPM_DiagReq: 8 XGW_Body
 SG_ BCM_BPM_DiagReqData0 : 7|8@0+ (1,0) [0|255] "-"  DUMMY_BCM_BPM
 SG_ BCM_BPM_DiagReqData1 : 15|8@0+ (1,0) [0|255] ""  DUMMY_BCM_BPM
 SG_ BCM_BPM_DiagReqData2 : 23|8@0+ (1,0) [0|255] ""  DUMMY_BCM_BPM
 SG_ BCM_BPM_DiagReqData3 : 31|8@0+ (1,0) [0|255] ""  DUMMY_BCM_BPM
 SG_ BCM_BPM_DiagReqData4 : 39|8@0+ (1,0) [0|255] ""  DUMMY_BCM_BPM
 SG_ BCM_BPM_DiagReqData5 : 47|8@0+ (1,0) [0|255] ""  DUMMY_BCM_BPM
 SG_ BCM_BPM_DiagReqData6 : 55|8@0+ (1,0) [0|255] "-"  DUMMY_BCM_BPM
 SG_ BCM_BPM_DiagReqData7 : 63|8@0+ (1,0) [0|255] "-"  DUMMY_BCM_BPM

BO_ 1791 DIAG_Req_All_Ecu: 8 XGW_Body
 SG_ OBD_Func_DiagReqData0 : 7|8@0+ (1,0) [0|255] ""  ACM,APM,ASU_Gateway,BCM,BCM_BPM,CCU_F,CCU_R,ETG,LDM_L,LDM_R,OCS_P,PSM_D,SHVU_F,SHVU_R,TRM
 SG_ OBD_Func_DiagReqData1 : 15|8@0+ (1,0) [0|255] ""  ACM,APM,ASU_Gateway,BCM,BCM_BPM,CCU_F,CCU_R,ETG,LDM_L,LDM_R,OCS_P,PSM_D,SHVU_F,SHVU_R,TRM
 SG_ OBD_Func_DiagReqData2 : 23|8@0+ (1,0) [0|255] ""  ACM,APM,ASU_Gateway,BCM,BCM_BPM,CCU_F,CCU_R,ETG,LDM_L,LDM_R,OCS_P,PSM_D,SHVU_F,SHVU_R,TRM
 SG_ OBD_Func_DiagReqData3 : 31|8@0+ (1,0) [0|255] ""  ACM,APM,ASU_Gateway,BCM,BCM_BPM,CCU_F,CCU_R,ETG,LDM_L,LDM_R,OCS_P,PSM_D,SHVU_F,SHVU_R,TRM
 SG_ OBD_Func_DiagReqData4 : 39|8@0+ (1,0) [0|255] ""  ACM,APM,ASU_Gateway,BCM,BCM_BPM,CCU_F,CCU_R,ETG,LDM_L,LDM_R,OCS_P,PSM_D,SHVU_F,SHVU_R,TRM
 SG_ OBD_Func_DiagReqData5 : 47|8@0+ (1,0) [0|255] ""  ACM,APM,ASU_Gateway,BCM,BCM_BPM,CCU_F,CCU_R,ETG,LDM_L,LDM_R,OCS_P,PSM_D,SHVU_F,SHVU_R,TRM
 SG_ OBD_Func_DiagReqData6 : 55|8@0+ (1,0) [0|255] ""  ACM,APM,ASU_Gateway,BCM,BCM_BPM,CCU_F,CCU_R,ETG,LDM_L,LDM_R,OCS_P,PSM_D,SHVU_F,SHVU_R,TRM
 SG_ OBD_Func_DiagReqData7 : 63|8@0+ (1,0) [0|255] ""  ACM,APM,ASU_Gateway,BCM,BCM_BPM,CCU_F,CCU_R,ETG,LDM_L,LDM_R,OCS_P,PSM_D,SHVU_F,SHVU_R,TRM

BO_ 1793 SEED_CAN_Req1_CCU_R: 8 CCU_R
 SG_ SEED_CAN_Req1 : 7|64@0+ (1,0) [0|1.84467440737096E+019] ""  CCU_F,XGW_Body

BO_ 1795 SEED_CAN_Req2_CCU_F: 8 CCU_F
 SG_ SEED_CAN_Req2 : 7|64@0+ (1,0) [0|1.84467440737096E+019] ""  CCU_R,XGW_Body

BO_ 1797 SEED_CAN_Req3_ADAS_Body: 8 ADAS_Body
 SG_ SEED_CAN_Req3 : 7|64@0+ (1,0) [0|1.84467440737096E+019] ""  BCM,XGW_Body

BO_ 1803 SEED_CAN_Req6_BCM: 8 BCM
 SG_ SEED_CAN_Req6 : 7|64@0+ (1,0) [0|1.84467440737096E+019] ""  ADAS_Body,XGW_Body

BO_ 1805 SEED_CAN_Req7_VCU_PT: 8 XGW_Body
 SG_ SEED_CAN_Req7 : 7|64@0+ (1,0) [0|1.84467440737096E+019] ""  BCM,CCU_F,CCU_R

BO_ 1809 BCM_Data: 8 BCM
 SG_ BCM_Data0 : 7|8@0+ (1,0) [0|255] ""  BCM_BPM
 SG_ BCM_Data1 : 15|8@0+ (1,0) [0|255] ""  BCM_BPM
 SG_ BCM_Data2 : 23|8@0+ (1,0) [0|255] ""  BCM_BPM
 SG_ BCM_Data3 : 31|8@0+ (1,0) [0|255] ""  BCM_BPM
 SG_ BCM_Data4 : 39|8@0+ (1,0) [0|255] ""  BCM_BPM
 SG_ BCM_Data5 : 47|8@0+ (1,0) [0|255] ""  BCM_BPM
 SG_ BCM_Data6 : 55|8@0+ (1,0) [0|255] ""  BCM_BPM
 SG_ BCM_Data7 : 63|8@0+ (1,0) [0|255] ""  BCM_BPM

BO_ 1810 BCM_BPM_Data: 8 BCM
 SG_ BCM_BPM_Data0 : 7|8@0+ (1,0) [0|255] ""  BCM_BPM
 SG_ BCM_BPM_Data1 : 15|8@0+ (1,0) [0|255] ""  BCM_BPM
 SG_ BCM_BPM_Data2 : 23|8@0+ (1,0) [0|255] ""  BCM_BPM
 SG_ BCM_BPM_Data3 : 31|8@0+ (1,0) [0|255] ""  BCM_BPM
 SG_ BCM_BPM_Data4 : 39|8@0+ (1,0) [0|255] ""  BCM_BPM
 SG_ BCM_BPM_Data5 : 47|8@0+ (1,0) [0|255] ""  BCM_BPM
 SG_ BCM_BPM_Data6 : 55|8@0+ (1,0) [0|255] ""  BCM_BPM
 SG_ BCM_BPM_Data7 : 63|8@0+ (1,0) [0|255] ""  BCM_BPM

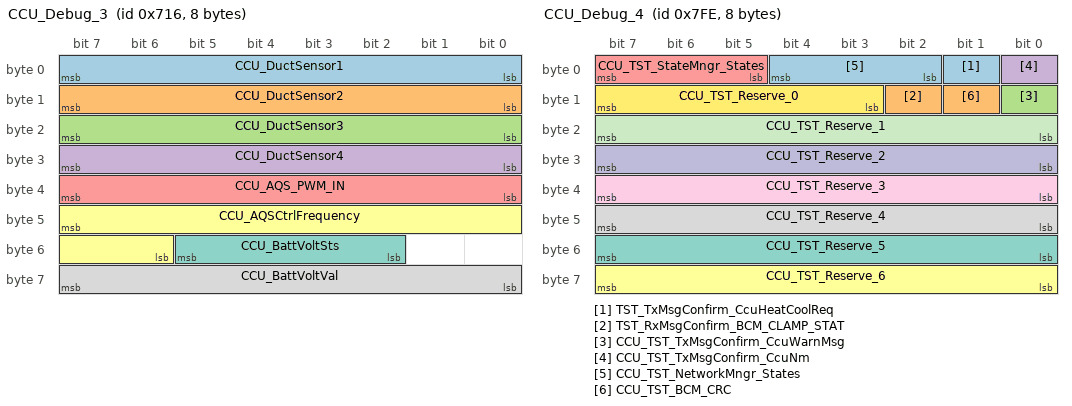
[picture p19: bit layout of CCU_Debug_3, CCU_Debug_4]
BO_ 1814 CCU_Debug_3: 8 CCU_F
 SG_ CCU_DuctSensor1 : 7|8@0+ (0.5,-30) [-30|97.5] "degree C" Vector__XXX
 SG_ CCU_DuctSensor2 : 15|8@0+ (0.5,-30) [-30|97.5] "degree C" Vector__XXX
 SG_ CCU_DuctSensor3 : 23|8@0+ (0.5,-30) [-30|97.5] "degree C" Vector__XXX
 SG_ CCU_DuctSensor4 : 31|8@0+ (0.5,-30) [-30|97.5] "degree C" Vector__XXX
 SG_ CCU_AQS_PWM_IN : 39|8@0+ (0.5,0) [0|100] "%" Vector__XXX
 SG_ CCU_AQSCtrlFrequency : 47|10@0+ (1,0) [0|1000] "Hz" Vector__XXX
 SG_ CCU_BattVoltSts : 53|4@0+ (1,0) [0|14] "" Vector__XXX
 SG_ CCU_BattVoltVal : 63|8@0+ (0.1,0) [0|25] "V" Vector__XXX

BO_ 1843 SEED_CAN_Req18_MHU: 8 XGW_Body
 SG_ SEED_CAN_Req18 : 7|64@0+ (1,0) [0|1.84467440737096E+019] ""  BCM,ETG

BO_ 1847 SEED_CAN_Req21_ETG: 8 ETG
 SG_ SEED_CAN_Req21 : 7|64@0+ (1,0) [0|1.84467440737096E+019] ""  XGW_Body

BO_ 1857 CCU_Debug_1: 8 CCU_F
 SG_ CCU_ERL_FL : 7|8@0+ (1,0) [0|255] ""  DUMMY_ECU
 SG_ CCU_ERL_FR : 15|8@0+ (1,0) [0|255] ""  DUMMY_ECU
 SG_ CCU_EvapTempSet : 23|8@0+ (0.1,-5) [-5|20.5] "Degree C"  DUMMY_ECU
 SG_ CCU_BlowerFltPWM : 31|8@0+ (0.5,0) [0|100] "%"  DUMMY_ECU
 SG_ CCU_AirDistribFlapPos : 39|8@0+ (0.5,0) [0|100] "%"  DUMMY_ECU
 SG_ CCU_RecircFlapPos : 47|8@0+ (0.5,0) [0|100] "%"  DUMMY_ECU
 SG_ CCU_AirDistribFeedback : 55|8@0+ (0.05,0) [0|5] "V"  DUMMY_ECU
 SG_ CCU_RecircFlapFeedback : 63|8@0+ (0.05,0) [0|5] "V"  DUMMY_ECU

BO_ 1858 CCU_Debug_2: 8 CCU_F
 SG_ CCU_TempFlapPos_FL : 7|8@0+ (0.5,0) [0|100] "%"  DUMMY_ECU
 SG_ CCU_TempFlapPos_FR : 15|8@0+ (0.5,0) [0|100] "%"  DUMMY_ECU
 SG_ CCU_DuctTargetTemp_FL : 23|8@0+ (0.5,-40) [-40|85] "Degree C"  DUMMY_ECU
 SG_ CCU_DuctTargetTemp_FR : 31|8@0+ (0.5,-40) [-40|85] "Degree C"  DUMMY_ECU
 SG_ CCU_TempFLFeedback : 39|8@0+ (0.05,0) [0|5] "V"  DUMMY_ECU
 SG_ CCU_TempFRFeedback : 47|8@0+ (0.05,0) [0|5] "V"  DUMMY_ECU
 SG_ CCU_PTCSetTemp : 55|8@0+ (0.5,0) [0|127] "Degree C"  DUMMY_ECU

BO_ 2046 CCU_Debug_4: 8 CCU_F
 SG_ TST_TxMsgConfirm_CcuHeatCoolReq : 1|1@0+ (1,0) [0|1] ""  DUMMY_ECU
 SG_ TST_RxMsgConfirm_BCM_CLAMP_STAT : 10|1@0+ (1,0) [0|1] ""  DUMMY_ECU
 SG_ CCU_TST_TxMsgConfirm_CcuWarnMsg : 8|1@0+ (1,0) [0|1] ""  DUMMY_ECU
 SG_ CCU_TST_TxMsgConfirm_CcuNm : 0|1@0+ (1,0) [0|1] ""  DUMMY_ECU
 SG_ CCU_TST_StateMngr_States : 7|3@0+ (1,0) [0|7] ""  DUMMY_ECU
 SG_ CCU_TST_Reserve_6 : 63|8@0+ (1,0) [0|255] ""  DUMMY_ECU
 SG_ CCU_TST_Reserve_5 : 55|8@0+ (1,0) [0|255] ""  DUMMY_ECU
 SG_ CCU_TST_Reserve_4 : 47|8@0+ (1,0) [0|255] ""  DUMMY_ECU
 SG_ CCU_TST_Reserve_3 : 39|8@0+ (1,0) [0|255] ""  DUMMY_ECU
 SG_ CCU_TST_Reserve_2 : 31|8@0+ (1,0) [0|255] ""  DUMMY_ECU
 SG_ CCU_TST_Reserve_1 : 23|8@0+ (1,0) [0|255] ""  DUMMY_ECU
 SG_ CCU_TST_Reserve_0 : 15|5@0+ (1,0) [0|31] "" DUMMY_ECU
 SG_ CCU_TST_NetworkMngr_States : 4|3@0+ (1,0) [0|7] ""  DUMMY_ECU
 SG_ CCU_TST_BCM_CRC : 9|1@0+ (1,0) [0|1] ""  DUMMY_ECU

BO_ 1938 CCU_Resp_CCP: 8 CCU_F
 SG_ CCU_Resp_CCP : 7|64@0+ (1,0) [0|0] ""  DUMMY_ECU

BO_ 1939 Internal_MSG_1: 8 LDM_L
 SG_ LDML_FltReactn : 7|32@0+ (1,0) [0|4294967295] ""  LDM_R
 SG_ LDML_RiAdjstAgOutp : 39|11@0+ (0.01,-10) [-10|10] "degree"  LDM_R

BO_ 1940 Internal_MSG_2: 8 LDM_R
 SG_ LDMR_FltReactn : 7|32@0+ (1,0) [0|4294967295] ""  LDM_L
 SG_ LDMR_ModuleCurAg : 39|11@0+ (0.01,-10) [-10|10] "degree"  LDM_L

BO_ 1976 CCU_Req_EOL: 8 DUMMY_ECU
 SG_ CCU_Req_EOL : 7|64@0+ (1,0) [0|0] ""  CCU_F

BO_ 1977 CCU_Resp_EOL: 8 CCU_F
 SG_ CCU_Resp_EOL : 7|64@0+ (1,0) [0|0] ""  DUMMY_ECU

BO_ 1978 CCUR_Req_EOL: 8 DUMMY_ECU
 SG_ CCUR_Req_EOL : 7|64@0+ (1,0) [0|0] ""  CCU_R

BO_ 1980 CCUR_Resp_EOL: 8 CCU_R
 SG_ CCUR_Resp_EOL_ : 7|64@0+ (1,0) [0|0] ""  DUMMY_ECU

BO_ 1985 CCU_Req_CCP: 8 DUMMY_ECU
 SG_ CCU_Req_CCP : 7|64@0+ (1,0) [0|0] ""  CCU_F

BO_ 2015 Diag_Request_ECU: 8 XGW_Body
 SG_ Diag_Request_ECU_Data0 : 7|8@0+ (1,0) [0|255] ""  ACM,APM,BCM,BCM_BPM,CCU_F,ETG,LDM_L,LDM_R,OCS_P,PSM_D,SHVU_F,SHVU_R,TRM
 SG_ Diag_Request_ECU_Data1 : 15|8@0+ (1,0) [0|255] "-"  ACM,APM,BCM,BCM_BPM,CCU_F,ETG,LDM_L,LDM_R,OCS_P,PSM_D,SHVU_F,SHVU_R,TRM
 SG_ Diag_Request_ECU_Data2 : 23|8@0+ (1,0) [0|255] "-"  ACM,APM,BCM,BCM_BPM,CCU_F,ETG,LDM_L,LDM_R,OCS_P,PSM_D,SHVU_F,SHVU_R,TRM
 SG_ Diag_Request_ECU_Data3 : 31|8@0+ (1,0) [0|255] ""  ACM,APM,BCM,BCM_BPM,CCU_F,ETG,LDM_L,LDM_R,OCS_P,PSM_D,SHVU_F,SHVU_R,TRM
 SG_ Diag_Request_ECU_Data4 : 39|8@0+ (1,0) [0|255] "-"  ACM,APM,BCM,BCM_BPM,CCU_F,ETG,LDM_L,LDM_R,OCS_P,PSM_D,SHVU_F,SHVU_R,TRM
 SG_ Diag_Request_ECU_Data5 : 47|8@0+ (1,0) [0|255] ""  ACM,APM,BCM,BCM_BPM,CCU_F,ETG,LDM_L,LDM_R,OCS_P,PSM_D,SHVU_F,SHVU_R,TRM
 SG_ Diag_Request_ECU_Data6 : 55|8@0+ (1,0) [0|255] "-"  ACM,APM,BCM,BCM_BPM,CCU_F,ETG,LDM_L,LDM_R,OCS_P,PSM_D,SHVU_F,SHVU_R,TRM
 SG_ Diag_Request_ECU_Data7 : 63|8@0+ (1,0) [0|255] ""  ACM,APM,BCM,BCM_BPM,CCU_F,ETG,LDM_L,LDM_R,OCS_P,PSM_D,SHVU_F,SHVU_R,TRM

BO_ 2033 DIAG_Req_Airbag_Deploy: 8 XGW_Body
 SG_ Request_Airbag_Deployment : 7|64@0+ (1,0) [0|1.84467440737096E+019] ""  ACM

BO_ 2041 DIAG_Resp_Airbag_Deploy: 8 ACM
 SG_ Response_Airbag_Deployment : 7|64@0+ (1,0) [0|255] ""  XGW_Body

BA_DEF_ BO_  "GenMsgSendType" ENUM  "Cyclic","NotUsed","NotUsed","NotUsed","NotUsed","NotUsed","NotUsed","IfActive","NoMsgSendType","NotUsed";
BA_DEF_ BO_  "GenMsgILSupport" ENUM  "No","Yes";
BA_DEF_ BO_  "DiagResponse" ENUM  "No","Yes";
BA_DEF_ BO_  "DiagRequest" ENUM  "No","Yes";
BA_DEF_ BO_  "NmAsrMessage" ENUM  "No","Yes";
BA_DEF_ BO_  "DiagState" ENUM  "No","Yes";
BA_DEF_ BO_  "DiagUudtResponse" ENUM  "False","True";
BA_DEF_ BO_  "GenMsgStartDelayTime" INT 0 65535;
BA_DEF_ BO_  "GenMsgDelayTime" INT 0 0;
BA_DEF_ BO_  "GenMsgNrOfRepetition" INT 0 0;
BA_DEF_ BO_  "GenMsgCycleTimeFast" INT 0 0;
BA_DEF_ BO_  "GenMsgCycleTime" INT 0 0;
BA_DEF_ SG_  "GenSigSendType" ENUM  "Cyclic","OnWrite","OnWriteWithRepetition","OnChange","OnChangeWithRepetition","IfActive","IfActiveWithRepetition","NoSigSendType","NotUsed","NotUsed","NotUsed","NotUsed","NotUsed";
BA_DEF_ SG_  "InvalidValue" STRING ;
BA_DEF_ SG_  "GenSigStartValue" INT 0 0;
BA_DEF_ SG_  "GenSigTimeoutTime_ALL" INT 0 65535;
BA_DEF_DEF_  "GenMsgSendType" "NoMsgSendType";
BA_DEF_DEF_  "GenMsgILSupport" "Yes";
BA_DEF_DEF_  "DiagResponse" "No";
BA_DEF_DEF_  "DiagRequest" "No";
BA_DEF_DEF_  "NmAsrMessage" "No";
BA_DEF_DEF_  "DiagState" "No";
BA_DEF_DEF_  "DiagUudtResponse" "False";
BA_DEF_DEF_  "GenMsgStartDelayTime" 0;
BA_DEF_DEF_  "GenMsgDelayTime" 0;
BA_DEF_DEF_  "GenMsgNrOfRepetition" 0;
BA_DEF_DEF_  "GenMsgCycleTimeFast" 0;
BA_DEF_DEF_  "GenMsgCycleTime" 0;
BA_DEF_DEF_  "GenSigSendType" "Cyclic";
BA_DEF_DEF_  "InvalidValue" "";
BA_DEF_DEF_  "GenSigStartValue" 0;
BA_DEF_DEF_  "GenSigTimeoutTime_ALL" 0;
BA_ "GenMsgCycleTimeFast" BO_ 1112 100;
BA_ "GenMsgNrOfRepetition" BO_ 1112 3;
BA_ "GenMsgCycleTimeFast" BO_ 1113 100;
BA_ "GenMsgNrOfRepetition" BO_ 1113 3;
BA_ "GenMsgCycleTime" BO_ 1115 500;
BA_ "GenMsgSendType" BO_ 1115 0;
BA_ "GenMsgCycleTime" BO_ 1124 50;
BA_ "GenMsgSendType" BO_ 1124 0;
BA_ "GenMsgCycleTime" BO_ 1125 50;
BA_ "GenMsgSendType" BO_ 1125 0;
BA_ "GenMsgCycleTime" BO_ 1152 1000;
BA_ "GenMsgCycleTimeFast" BO_ 1152 100;
BA_ "GenMsgNrOfRepetition" BO_ 1152 2;
BA_ "GenMsgSendType" BO_ 1152 0;
BA_ "GenMsgCycleTime" BO_ 1153 1000;
BA_ "GenMsgCycleTimeFast" BO_ 1153 100;
BA_ "GenMsgDelayTime" BO_ 1153 25;
BA_ "GenMsgNrOfRepetition" BO_ 1153 2;
BA_ "GenMsgSendType" BO_ 1153 0;
BA_ "GenMsgCycleTime" BO_ 1155 50;
BA_ "GenMsgSendType" BO_ 1155 0;
BA_ "GenMsgCycleTime" BO_ 1160 1000;
BA_ "GenMsgCycleTimeFast" BO_ 1160 100;
BA_ "GenMsgNrOfRepetition" BO_ 1160 2;
BA_ "GenMsgSendType" BO_ 1160 0;
BA_ "GenMsgCycleTime" BO_ 1161 1000;
BA_ "GenMsgSendType" BO_ 1161 0;
BA_ "GenMsgStartDelayTime" BO_ 1161 30;
BA_ "GenMsgCycleTime" BO_ 1166 100;
BA_ "GenMsgSendType" BO_ 1166 0;
BA_ "GenMsgCycleTime" BO_ 1171 1000;
BA_ "GenMsgCycleTimeFast" BO_ 1171 100;
BA_ "GenMsgNrOfRepetition" BO_ 1171 2;
BA_ "GenMsgSendType" BO_ 1171 0;
BA_ "GenMsgCycleTime" BO_ 1211 100;
BA_ "GenMsgCycleTimeFast" BO_ 1211 25;
BA_ "GenMsgNrOfRepetition" BO_ 1211 3;
BA_ "GenMsgSendType" BO_ 1211 0;
BA_ "GenMsgDelayTime" BO_ 1211 25;
BA_ "GenMsgCycleTime" BO_ 1217 1000;
BA_ "GenMsgSendType" BO_ 1217 0;
BA_ "GenMsgCycleTime" BO_ 1281 640;
BA_ "GenMsgILSupport" BO_ 1281 0;
BA_ "GenMsgSendType" BO_ 1281 0;
BA_ "NmAsrMessage" BO_ 1281 1;
BA_ "GenMsgCycleTime" BO_ 1282 640;
BA_ "GenMsgILSupport" BO_ 1282 0;
BA_ "GenMsgSendType" BO_ 1282 0;
BA_ "NmAsrMessage" BO_ 1282 1;
BA_ "GenMsgCycleTime" BO_ 1289 640;
BA_ "GenMsgILSupport" BO_ 1289 0;
BA_ "GenMsgSendType" BO_ 1289 0;
BA_ "NmAsrMessage" BO_ 1289 1;
BA_ "GenMsgCycleTime" BO_ 1294 640;
BA_ "GenMsgILSupport" BO_ 1294 0;
BA_ "GenMsgSendType" BO_ 1294 0;
BA_ "NmAsrMessage" BO_ 1294 1;
BA_ "GenMsgCycleTime" BO_ 1310 640;
BA_ "GenMsgILSupport" BO_ 1310 0;
BA_ "GenMsgSendType" BO_ 1310 0;
BA_ "NmAsrMessage" BO_ 1310 1;
BA_ "GenMsgCycleTime" BO_ 1339 640;
BA_ "GenMsgILSupport" BO_ 1339 0;
BA_ "GenMsgSendType" BO_ 1339 0;
BA_ "NmAsrMessage" BO_ 1339 1;
BA_ "GenMsgCycleTime" BO_ 1344 640;
BA_ "GenMsgILSupport" BO_ 1344 0;
BA_ "GenMsgSendType" BO_ 1344 0;
BA_ "NmAsrMessage" BO_ 1344 1;
BA_ "GenMsgCycleTime" BO_ 1345 640;
BA_ "GenMsgILSupport" BO_ 1345 0;
BA_ "GenMsgSendType" BO_ 1345 0;
BA_ "NmAsrMessage" BO_ 1345 1;
BA_ "GenMsgCycleTime" BO_ 1353 640;
BA_ "GenMsgILSupport" BO_ 1353 0;
BA_ "GenMsgSendType" BO_ 1353 0;
BA_ "NmAsrMessage" BO_ 1353 1;
BA_ "GenMsgCycleTime" BO_ 1354 640;
BA_ "GenMsgILSupport" BO_ 1354 0;
BA_ "GenMsgSendType" BO_ 1354 0;
BA_ "NmAsrMessage" BO_ 1354 1;
BA_ "GenMsgCycleTime" BO_ 1360 640;
BA_ "GenMsgILSupport" BO_ 1360 0;
BA_ "GenMsgSendType" BO_ 1360 0;
BA_ "NmAsrMessage" BO_ 1360 1;
BA_ "DiagResponse" BO_ 1537 1;
BA_ "GenMsgILSupport" BO_ 1537 0;
BA_ "DiagResponse" BO_ 1544 1;
BA_ "GenMsgILSupport" BO_ 1544 0;
BA_ "DiagResponse" BO_ 1545 1;
BA_ "GenMsgILSupport" BO_ 1545 0;
BA_ "DiagResponse" BO_ 1550 1;
BA_ "GenMsgILSupport" BO_ 1550 0;
BA_ "DiagResponse" BO_ 1553 1;
BA_ "DiagResponse" BO_ 1556 1;
BA_ "GenMsgILSupport" BO_ 1556 0;
BA_ "DiagResponse" BO_ 1566 1;
BA_ "GenMsgILSupport" BO_ 1566 0;
BA_ "DiagResponse" BO_ 1592 1;
BA_ "DiagResponse" BO_ 1595 1;
BA_ "GenMsgILSupport" BO_ 1595 0;
BA_ "DiagResponse" BO_ 1601 1;
BA_ "GenMsgILSupport" BO_ 1601 0;
BA_ "DiagResponse" BO_ 1602 1;
BA_ "GenMsgILSupport" BO_ 1602 0;
BA_ "DiagResponse" BO_ 1603 1;
BA_ "GenMsgILSupport" BO_ 1603 0;
BA_ "DiagResponse" BO_ 1604 1;
BA_ "GenMsgILSupport" BO_ 1604 0;
BA_ "DiagResponse" BO_ 1609 1;
BA_ "GenMsgILSupport" BO_ 1609 0;
BA_ "DiagResponse" BO_ 1610 1;
BA_ "GenMsgILSupport" BO_ 1610 0;
BA_ "DiagResponse" BO_ 1624 1;
BA_ "GenMsgILSupport" BO_ 1624 0;
BA_ "DiagResponse" BO_ 1636 1;
BA_ "GenMsgILSupport" BO_ 1636 0;
BA_ "DiagResponse" BO_ 1659 1;
BA_ "GenMsgILSupport" BO_ 1659 0;
BA_ "DiagRequest" BO_ 1665 1;
BA_ "GenMsgILSupport" BO_ 1665 0;
BA_ "DiagRequest" BO_ 1672 1;
BA_ "GenMsgILSupport" BO_ 1672 0;
BA_ "DiagRequest" BO_ 1673 1;
BA_ "GenMsgILSupport" BO_ 1673 0;
BA_ "DiagRequest" BO_ 1678 1;
BA_ "GenMsgILSupport" BO_ 1678 0;
BA_ "DiagRequest" BO_ 1681 1;
BA_ "DiagRequest" BO_ 1684 1;
BA_ "GenMsgILSupport" BO_ 1684 0;
BA_ "DiagRequest" BO_ 1694 1;
BA_ "GenMsgILSupport" BO_ 1694 0;
BA_ "DiagRequest" BO_ 1723 1;
BA_ "GenMsgILSupport" BO_ 1723 0;
BA_ "DiagRequest" BO_ 1729 1;
BA_ "GenMsgILSupport" BO_ 1729 0;
BA_ "DiagRequest" BO_ 1730 1;
BA_ "GenMsgILSupport" BO_ 1730 0;
BA_ "DiagRequest" BO_ 1731 1;
BA_ "GenMsgILSupport" BO_ 1731 0;
BA_ "DiagRequest" BO_ 1732 1;
BA_ "GenMsgILSupport" BO_ 1732 0;
BA_ "DiagRequest" BO_ 1737 1;
BA_ "GenMsgILSupport" BO_ 1737 0;
BA_ "DiagRequest" BO_ 1738 1;
BA_ "GenMsgILSupport" BO_ 1738 0;
BA_ "DiagRequest" BO_ 1752 1;
BA_ "GenMsgILSupport" BO_ 1752 0;
BA_ "DiagRequest" BO_ 1764 1;
BA_ "GenMsgILSupport" BO_ 1764 0;
BA_ "DiagRequest" BO_ 1775 1;
BA_ "DiagState" BO_ 1775 1;
BA_ "GenMsgILSupport" BO_ 1775 0;
BA_ "DiagRequest" BO_ 1777 1;
BA_ "DiagRequest" BO_ 1787 1;
BA_ "GenMsgILSupport" BO_ 1787 0;
BA_ "DiagRequest" BO_ 1791 1;
BA_ "DiagState" BO_ 1791 1;
BA_ "GenMsgILSupport" BO_ 1791 0;
BA_ "GenMsgCycleTime" BO_ 1809 50;
BA_ "GenMsgSendType" BO_ 1809 0;
BA_ "GenMsgCycleTime" BO_ 1810 50;
BA_ "GenMsgSendType" BO_ 1810 0;
BA_ "GenMsgCycleTime" BO_ 1814 200;
BA_ "GenMsgSendType" BO_ 1814 0;
BA_ "GenMsgStartDelayTime" BO_ 1814 45;
BA_ "GenMsgCycleTime" BO_ 1857 200;
BA_ "GenMsgSendType" BO_ 1857 0;
BA_ "GenMsgStartDelayTime" BO_ 1857 35;
BA_ "GenMsgCycleTime" BO_ 1858 200;
BA_ "GenMsgSendType" BO_ 1858 0;
BA_ "GenMsgStartDelayTime" BO_ 1858 40;
BA_ "GenMsgSendType" BO_ 2046 0;
BA_ "GenMsgStartDelayTime" BO_ 2046 50;
BA_ "GenMsgCycleTime" BO_ 2046 200;
BA_ "DiagResponse" BO_ 1938 1;
BA_ "GenMsgCycleTime" BO_ 1939 50;
BA_ "GenMsgSendType" BO_ 1939 0;
BA_ "GenMsgCycleTime" BO_ 1940 50;
BA_ "GenMsgSendType" BO_ 1940 0;
BA_ "DiagRequest" BO_ 1976 1;
BA_ "DiagResponse" BO_ 1977 1;
BA_ "DiagRequest" BO_ 1978 1;
BA_ "DiagResponse" BO_ 1980 1;
BA_ "DiagRequest" BO_ 1985 1;
BA_ "DiagRequest" BO_ 2015 1;
BA_ "DiagRequest" BO_ 2033 1;
BA_ "GenMsgILSupport" BO_ 2033 0;
BA_ "DiagResponse" BO_ 2041 1;
BA_ "GenMsgILSupport" BO_ 2041 0;
BA_ "GenSigSendType" SG_ 1112 AmbLightColorZoneReq 2;
BA_ "InvalidValue" SG_ 1112 AmbLightColorZoneReq "null";
BA_ "GenSigSendType" SG_ 1112 AmbLightColorRed 2;
BA_ "InvalidValue" SG_ 1112 AmbLightColorRed "null";
BA_ "GenSigSendType" SG_ 1112 AmbLightColorGreen 2;
BA_ "InvalidValue" SG_ 1112 AmbLightColorGreen "null";
BA_ "GenSigSendType" SG_ 1112 AmbLightColorBlue 2;
BA_ "InvalidValue" SG_ 1112 AmbLightColorBlue "null";
BA_ "GenSigSendType" SG_ 1112 SECCAN_BCM_Clr_Rq 2;
BA_ "InvalidValue" SG_ 1112 SECCAN_BCM_Clr_Rq "null";
BA_ "GenSigSendType" SG_ 1113 AmbLightIntensityTimingZoneReq 2;
BA_ "InvalidValue" SG_ 1113 AmbLightIntensityTimingZoneReq "null";
BA_ "GenSigSendType" SG_ 1113 AmbLightIntensityTimingTypeReq 2;
BA_ "InvalidValue" SG_ 1113 AmbLightIntensityTimingTypeReq "null";
BA_ "GenSigSendType" SG_ 1113 AmbLightIntenTimingBrightReq 2;
BA_ "InvalidValue" SG_ 1113 AmbLightIntenTimingBrightReq "null";
BA_ "GenSigSendType" SG_ 1113 AmbLightIntensityTimingT1Req 2;
BA_ "InvalidValue" SG_ 1113 AmbLightIntensityTimingT1Req "null";
BA_ "GenSigSendType" SG_ 1113 AmbLightIntensityTimingT2Req 2;
BA_ "InvalidValue" SG_ 1113 AmbLightIntensityTimingT2Req "null";
BA_ "GenSigSendType" SG_ 1113 AmbLightIntensityTimingT3Req 2;
BA_ "InvalidValue" SG_ 1113 AmbLightIntensityTimingT3Req "null";
BA_ "GenSigSendType" SG_ 1113 AmbLightIntensityTimingT4Req 2;
BA_ "InvalidValue" SG_ 1113 AmbLightIntensityTimingT4Req "null";
BA_ "GenSigSendType" SG_ 1113 AmbLightIntensityTimingN2Req 2;
BA_ "InvalidValue" SG_ 1113 AmbLightIntensityTimingN2Req "null";
BA_ "GenSigSendType" SG_ 1113 AmbLightIntensityTimingN1Req 2;
BA_ "InvalidValue" SG_ 1113 AmbLightIntensityTimingN1Req "null";
BA_ "GenSigTimeoutTime_ALL" SG_ 1115 HOD_steering_wheel_type 2500;
BA_ "InvalidValue" SG_ 1115 HOD_steering_wheel_type "null";
BA_ "GenSigTimeoutTime_ALL" SG_ 1115 HOD_vehicle_type 2500;
BA_ "InvalidValue" SG_ 1115 HOD_vehicle_type "null";
BA_ "GenSigTimeoutTime_ALL" SG_ 1115 ADAS_HOD_state_requesting 2500;
BA_ "InvalidValue" SG_ 1115 ADAS_HOD_state_requesting "3h";
BA_ "GenSigTimeoutTime_ALL" SG_ 1124 LDML_LampAssemblySts 500;
BA_ "InvalidValue" SG_ 1124 LDML_LampAssemblySts "3h";
BA_ "GenSigTimeoutTime_ALL" SG_ 1124 LDML_PosLmpSts 500;
BA_ "InvalidValue" SG_ 1124 LDML_PosLmpSts "3h";
BA_ "GenSigTimeoutTime_ALL" SG_ 1124 LDML_ControllerSts 500;
BA_ "InvalidValue" SG_ 1124 LDML_ControllerSts "3h";
BA_ "GenSigTimeoutTime_ALL" SG_ 1124 LDML_TurnIndicatorSts 500;
BA_ "InvalidValue" SG_ 1124 LDML_TurnIndicatorSts "3h";
BA_ "GenSigTimeoutTime_ALL" SG_ 1124 LDML_AuxLBSts 500;
BA_ "InvalidValue" SG_ 1124 LDML_AuxLBSts "3h";
BA_ "GenSigTimeoutTime_ALL" SG_ 1124 LDML_LowBeamSts 500;
BA_ "InvalidValue" SG_ 1124 LDML_LowBeamSts "3h";
BA_ "GenSigTimeoutTime_ALL" SG_ 1124 LDML_HighBeamSts 500;
BA_ "InvalidValue" SG_ 1124 LDML_HighBeamSts "3h";
BA_ "GenSigTimeoutTime_ALL" SG_ 1124 LDML_DayRunningLampSts 500;
BA_ "InvalidValue" SG_ 1124 LDML_DayRunningLampSts "3h";
BA_ "GenSigTimeoutTime_ALL" SG_ 1124 LDML_DayTimeRunningLightFbSts 500;
BA_ "InvalidValue" SG_ 1124 LDML_DayTimeRunningLightFbSts "3h";
BA_ "GenSigTimeoutTime_ALL" SG_ 1124 LDML_AutoLvlFbSts 500;
BA_ "InvalidValue" SG_ 1124 LDML_AutoLvlFbSts "3h";
BA_ "GenSigTimeoutTime_ALL" SG_ 1124 LDML_AdptvDrvBeamFbSts 500;
BA_ "InvalidValue" SG_ 1124 LDML_AdptvDrvBeamFbSts "3h";
BA_ "GenSigTimeoutTime_ALL" SG_ 1124 LDML_AuxHBSts 500;
BA_ "InvalidValue" SG_ 1124 LDML_AuxHBSts "3h";
BA_ "GenSigTimeoutTime_ALL" SG_ 1124 LDML_FollowMeHomeFbSts 500;
BA_ "InvalidValue" SG_ 1124 LDML_FollowMeHomeFbSts "5h";
BA_ "GenSigTimeoutTime_ALL" SG_ 1124 LDML_ExteriorLightFbSts 500;
BA_ "InvalidValue" SG_ 1124 LDML_ExteriorLightFbSts "4h";
BA_ "GenSigStartValue" SG_ 1124 LDML_AHB_ICON_Feed 3;
BA_ "GenSigTimeoutTime_ALL" SG_ 1124 LDML_AHB_ICON_Feed 500;
BA_ "InvalidValue" SG_ 1124 LDML_AHB_ICON_Feed "3h";
BA_ "GenSigTimeoutTime_ALL" SG_ 1125 LDMR_LampAssemblySts 500;
BA_ "InvalidValue" SG_ 1125 LDMR_LampAssemblySts "3h";
BA_ "GenSigTimeoutTime_ALL" SG_ 1125 LDMR_PosLmpSts 500;
BA_ "InvalidValue" SG_ 1125 LDMR_PosLmpSts "3h";
BA_ "GenSigTimeoutTime_ALL" SG_ 1125 LDMR_ControllerSts 500;
BA_ "InvalidValue" SG_ 1125 LDMR_ControllerSts "3h";
BA_ "GenSigTimeoutTime_ALL" SG_ 1125 LDMR_TurnIndicatorSts 500;
BA_ "InvalidValue" SG_ 1125 LDMR_TurnIndicatorSts "3h";
BA_ "GenSigTimeoutTime_ALL" SG_ 1125 LDMR_AuxLBSts 500;
BA_ "InvalidValue" SG_ 1125 LDMR_AuxLBSts "3h";
BA_ "GenSigTimeoutTime_ALL" SG_ 1125 LDMR_LowBeamSts 500;
BA_ "InvalidValue" SG_ 1125 LDMR_LowBeamSts "3h";
BA_ "GenSigTimeoutTime_ALL" SG_ 1125 LDMR_HighBeamSts 500;
BA_ "InvalidValue" SG_ 1125 LDMR_HighBeamSts "3h";
BA_ "GenSigTimeoutTime_ALL" SG_ 1125 LDMR_DayRunningLampSts 500;
BA_ "InvalidValue" SG_ 1125 LDMR_DayRunningLampSts "3h";
BA_ "GenSigTimeoutTime_ALL" SG_ 1125 LDMR_DayTimeRunningLightFbSts 500;
BA_ "InvalidValue" SG_ 1125 LDMR_DayTimeRunningLightFbSts "3h";
BA_ "GenSigTimeoutTime_ALL" SG_ 1125 LDMR_AutoLvlFbSts 500;
BA_ "InvalidValue" SG_ 1125 LDMR_AutoLvlFbSts "3h";
BA_ "GenSigTimeoutTime_ALL" SG_ 1125 LDMR_AdptvDrvBeamFbSts 500;
BA_ "InvalidValue" SG_ 1125 LDMR_AdptvDrvBeamFbSts "3h";
BA_ "GenSigTimeoutTime_ALL" SG_ 1125 LDMR_AuxHBSts 500;
BA_ "InvalidValue" SG_ 1125 LDMR_AuxHBSts "3h";
BA_ "GenSigTimeoutTime_ALL" SG_ 1125 LDMR_FollowMeHomeFbSts 500;
BA_ "InvalidValue" SG_ 1125 LDMR_FollowMeHomeFbSts "5h";
BA_ "GenSigTimeoutTime_ALL" SG_ 1125 LDMR_ExteriorLightFbSts 500;
BA_ "InvalidValue" SG_ 1125 LDMR_ExteriorLightFbSts "4h";
BA_ "GenSigStartValue" SG_ 1125 LDMR_AHB_ICON_Feed 3;
BA_ "GenSigTimeoutTime_ALL" SG_ 1125 LDMR_AHB_ICON_Feed 500;
BA_ "InvalidValue" SG_ 1125 LDMR_AHB_ICON_Feed "3h";
BA_ "GenSigSendType" SG_ 1152 CHKSM_PSM_WARNING_MSG 3;
BA_ "GenSigTimeoutTime_ALL" SG_ 1152 CHKSM_PSM_WARNING_MSG 5000;
BA_ "InvalidValue" SG_ 1152 CHKSM_PSM_WARNING_MSG "null";
BA_ "GenSigSendType" SG_ 1152 ALV_PSM_WARNING_MSG 3;
BA_ "GenSigTimeoutTime_ALL" SG_ 1152 ALV_PSM_WARNING_MSG 5000;
BA_ "InvalidValue" SG_ 1152 ALV_PSM_WARNING_MSG "Fh";
BA_ "GenSigSendType" SG_ 1152 PSM_DrvSeatMissalignment 4;
BA_ "GenSigTimeoutTime_ALL" SG_ 1152 PSM_DrvSeatMissalignment 5000;
BA_ "InvalidValue" SG_ 1152 PSM_DrvSeatMissalignment "null";
BA_ "GenSigSendType" SG_ 1152 PSM_PasSeatMisalignment 4;
BA_ "GenSigTimeoutTime_ALL" SG_ 1152 PSM_PasSeatMisalignment 5000;
BA_ "InvalidValue" SG_ 1152 PSM_PasSeatMisalignment "null";
BA_ "GenSigSendType" SG_ 1152 PSM_WflagRes3 4;
BA_ "GenSigTimeoutTime_ALL" SG_ 1152 PSM_WflagRes3 5000;
BA_ "InvalidValue" SG_ 1152 PSM_WflagRes3 "null";
BA_ "GenSigSendType" SG_ 1152 PSM_WflagRes4 4;
BA_ "GenSigTimeoutTime_ALL" SG_ 1152 PSM_WflagRes4 5000;
BA_ "InvalidValue" SG_ 1152 PSM_WflagRes4 "3h";
BA_ "GenSigSendType" SG_ 1152 PSM_WflagRes5 4;
BA_ "GenSigTimeoutTime_ALL" SG_ 1152 PSM_WflagRes5 5000;
BA_ "InvalidValue" SG_ 1152 PSM_WflagRes5 "null";
BA_ "GenSigSendType" SG_ 1152 PSM_WflagRes6 4;
BA_ "GenSigTimeoutTime_ALL" SG_ 1152 PSM_WflagRes6 5000;
BA_ "InvalidValue" SG_ 1152 PSM_WflagRes6 "null";
BA_ "GenSigSendType" SG_ 1152 PSM_WflagRes7 4;
BA_ "GenSigTimeoutTime_ALL" SG_ 1152 PSM_WflagRes7 5000;
BA_ "InvalidValue" SG_ 1152 PSM_WflagRes7 "null";
BA_ "GenSigSendType" SG_ 1152 PSM_WflagRes8 4;
BA_ "GenSigTimeoutTime_ALL" SG_ 1152 PSM_WflagRes8 5000;
BA_ "InvalidValue" SG_ 1152 PSM_WflagRes8 "null";
BA_ "GenSigSendType" SG_ 1152 PSM_WflagRes9 4;
BA_ "GenSigTimeoutTime_ALL" SG_ 1152 PSM_WflagRes9 5000;
BA_ "InvalidValue" SG_ 1152 PSM_WflagRes9 "null";
BA_ "GenSigSendType" SG_ 1152 PSM_WflagRes10 4;
BA_ "GenSigTimeoutTime_ALL" SG_ 1152 PSM_WflagRes10 5000;
BA_ "InvalidValue" SG_ 1152 PSM_WflagRes10 "null";
BA_ "GenSigSendType" SG_ 1152 PSM_WflagRes11 4;
BA_ "GenSigTimeoutTime_ALL" SG_ 1152 PSM_WflagRes11 5000;
BA_ "InvalidValue" SG_ 1152 PSM_WflagRes11 "null";
BA_ "GenSigSendType" SG_ 1152 PSM_WflagRes12 4;
BA_ "GenSigTimeoutTime_ALL" SG_ 1152 PSM_WflagRes12 5000;
BA_ "InvalidValue" SG_ 1152 PSM_WflagRes12 "null";
BA_ "GenSigSendType" SG_ 1153 CHSKM_BCM_WarnMsg 3;
BA_ "GenSigTimeoutTime_ALL" SG_ 1153 CHSKM_BCM_WarnMsg 5000;
BA_ "InvalidValue" SG_ 1153 CHSKM_BCM_WarnMsg "-";
BA_ "GenSigSendType" SG_ 1153 ALV_BCM_WarnMsg 3;
BA_ "GenSigTimeoutTime_ALL" SG_ 1153 ALV_BCM_WarnMsg 5000;
BA_ "InvalidValue" SG_ 1153 ALV_BCM_WarnMsg "Fh";
BA_ "GenSigSendType" SG_ 1153 BCM_NoValidKey_1 4;
BA_ "GenSigTimeoutTime_ALL" SG_ 1153 BCM_NoValidKey_1 5000;
BA_ "InvalidValue" SG_ 1153 BCM_NoValidKey_1 "-";
BA_ "GenSigSendType" SG_ 1153 BCM_SSB_defect 4;
BA_ "GenSigTimeoutTime_ALL" SG_ 1153 BCM_SSB_defect 5000;
BA_ "InvalidValue" SG_ 1153 BCM_SSB_defect "-";
BA_ "GenSigSendType" SG_ 1153 BCM_WrongGearPosToStart 4;
BA_ "GenSigTimeoutTime_ALL" SG_ 1153 BCM_WrongGearPosToStart 5000;
BA_ "InvalidValue" SG_ 1153 BCM_WrongGearPosToStart "-";
BA_ "GenSigSendType" SG_ 1153 BCM_NoValidKey_2 4;
BA_ "GenSigTimeoutTime_ALL" SG_ 1153 BCM_NoValidKey_2 5000;
BA_ "InvalidValue" SG_ 1153 BCM_NoValidKey_2 "-";
BA_ "GenSigSendType" SG_ 1153 BCM_PressBrakeToStart 4;
BA_ "GenSigTimeoutTime_ALL" SG_ 1153 BCM_PressBrakeToStart 5000;
BA_ "InvalidValue" SG_ 1153 BCM_PressBrakeToStart "-";
BA_ "GenSigSendType" SG_ 1153 BCM_TurnOffPosLightRemindr 4;
BA_ "GenSigTimeoutTime_ALL" SG_ 1153 BCM_TurnOffPosLightRemindr 5000;
BA_ "InvalidValue" SG_ 1153 BCM_TurnOffPosLightRemindr "-";
BA_ "GenSigSendType" SG_ 1153 BCM_KeyFob_LowBattery 4;
BA_ "GenSigTimeoutTime_ALL" SG_ 1153 BCM_KeyFob_LowBattery 5000;
BA_ "InvalidValue" SG_ 1153 BCM_KeyFob_LowBattery "-";
BA_ "GenSigSendType" SG_ 1153 BCM_StopLightDefect 4;
BA_ "GenSigTimeoutTime_ALL" SG_ 1153 BCM_StopLightDefect 5000;
BA_ "InvalidValue" SG_ 1153 BCM_StopLightDefect "-";
BA_ "GenSigSendType" SG_ 1153 BCM_LowBeamDefect 4;
BA_ "GenSigTimeoutTime_ALL" SG_ 1153 BCM_LowBeamDefect 5000;
BA_ "InvalidValue" SG_ 1153 BCM_LowBeamDefect "-";
BA_ "GenSigSendType" SG_ 1153 BCM_HighBeamDefect 4;
BA_ "GenSigTimeoutTime_ALL" SG_ 1153 BCM_HighBeamDefect 5000;
BA_ "InvalidValue" SG_ 1153 BCM_HighBeamDefect "-";
BA_ "GenSigSendType" SG_ 1153 BCM_PositionLightDefect 4;
BA_ "GenSigTimeoutTime_ALL" SG_ 1153 BCM_PositionLightDefect 5000;
BA_ "InvalidValue" SG_ 1153 BCM_PositionLightDefect "-";
BA_ "GenSigSendType" SG_ 1153 BCM_CHMLS_Defect 4;
BA_ "GenSigTimeoutTime_ALL" SG_ 1153 BCM_CHMLS_Defect 5000;
BA_ "InvalidValue" SG_ 1153 BCM_CHMLS_Defect "-";
BA_ "GenSigSendType" SG_ 1153 BCM_LicencePlateLight_Defect 4;
BA_ "GenSigTimeoutTime_ALL" SG_ 1153 BCM_LicencePlateLight_Defect 5000;
BA_ "InvalidValue" SG_ 1153 BCM_LicencePlateLight_Defect "-";
BA_ "GenSigSendType" SG_ 1153 BCM_FrontFog_Defect 4;
BA_ "GenSigTimeoutTime_ALL" SG_ 1153 BCM_FrontFog_Defect 5000;
BA_ "InvalidValue" SG_ 1153 BCM_FrontFog_Defect "-";
BA_ "GenSigSendType" SG_ 1153 BCM_RearFog_Defect 4;
BA_ "GenSigTimeoutTime_ALL" SG_ 1153 BCM_RearFog_Defect 5000;
BA_ "InvalidValue" SG_ 1153 BCM_RearFog_Defect "-";
BA_ "GenSigSendType" SG_ 1153 BCM_ReverseLightDefect 4;
BA_ "GenSigTimeoutTime_ALL" SG_ 1153 BCM_ReverseLightDefect 5000;
BA_ "InvalidValue" SG_ 1153 BCM_ReverseLightDefect "-";
BA_ "GenSigSendType" SG_ 1153 BCM_RLS_Malfunction 4;
BA_ "GenSigTimeoutTime_ALL" SG_ 1153 BCM_RLS_Malfunction 5000;
BA_ "InvalidValue" SG_ 1153 BCM_RLS_Malfunction "-";
BA_ "GenSigSendType" SG_ 1153 BCM_12VBattery_LowLevel 4;
BA_ "GenSigTimeoutTime_ALL" SG_ 1153 BCM_12VBattery_LowLevel 5000;
BA_ "InvalidValue" SG_ 1153 BCM_12VBattery_LowLevel "-";
BA_ "GenSigSendType" SG_ 1153 BCM_ForgetKeyFOBInCar 4;
BA_ "GenSigTimeoutTime_ALL" SG_ 1153 BCM_ForgetKeyFOBInCar 5000;
BA_ "InvalidValue" SG_ 1153 BCM_ForgetKeyFOBInCar "-";
BA_ "GenSigSendType" SG_ 1153 BCM_12VBattery_Discharging 4;
BA_ "GenSigTimeoutTime_ALL" SG_ 1153 BCM_12VBattery_Discharging 5000;
BA_ "InvalidValue" SG_ 1153 BCM_12VBattery_Discharging "-";
BA_ "GenSigSendType" SG_ 1153 BCM_TurnIndicatorDefect 4;
BA_ "GenSigTimeoutTime_ALL" SG_ 1153 BCM_TurnIndicatorDefect 5000;
BA_ "InvalidValue" SG_ 1153 BCM_TurnIndicatorDefect "-";
BA_ "GenSigSendType" SG_ 1153 BCM_dTPMS_Malfunc 4;
BA_ "GenSigTimeoutTime_ALL" SG_ 1153 BCM_dTPMS_Malfunc 5000;
BA_ "InvalidValue" SG_ 1153 BCM_dTPMS_Malfunc "-";
BA_ "GenSigSendType" SG_ 1153 BCM_dTPMS_Malfunc_LostSensor 4;
BA_ "GenSigTimeoutTime_ALL" SG_ 1153 BCM_dTPMS_Malfunc_LostSensor 5000;
BA_ "InvalidValue" SG_ 1153 BCM_dTPMS_Malfunc_LostSensor "-";
BA_ "GenSigSendType" SG_ 1153 BCM_dTPMS_LowPressure 4;
BA_ "GenSigTimeoutTime_ALL" SG_ 1153 BCM_dTPMS_LowPressure 5000;
BA_ "InvalidValue" SG_ 1153 BCM_dTPMS_LowPressure "-";
BA_ "GenSigSendType" SG_ 1153 BCM_dTPMS_RapidLeak 4;
BA_ "GenSigTimeoutTime_ALL" SG_ 1153 BCM_dTPMS_RapidLeak 5000;
BA_ "InvalidValue" SG_ 1153 BCM_dTPMS_RapidLeak "-";
BA_ "GenSigSendType" SG_ 1153 BCM_dTPMS_HighTemperature 4;
BA_ "GenSigTimeoutTime_ALL" SG_ 1153 BCM_dTPMS_HighTemperature 5000;
BA_ "InvalidValue" SG_ 1153 BCM_dTPMS_HighTemperature "-";
BA_ "GenSigSendType" SG_ 1153 BCM_dTPMS_HighPressure 4;
BA_ "GenSigTimeoutTime_ALL" SG_ 1153 BCM_dTPMS_HighPressure 5000;
BA_ "InvalidValue" SG_ 1153 BCM_dTPMS_HighPressure "-";
BA_ "GenSigSendType" SG_ 1153 BCM_dTPMS_LowBattery 4;
BA_ "GenSigTimeoutTime_ALL" SG_ 1153 BCM_dTPMS_LowBattery 5000;
BA_ "InvalidValue" SG_ 1153 BCM_dTPMS_LowBattery "-";
BA_ "GenSigSendType" SG_ 1153 BCM_Keyfob_Leftcar 4;
BA_ "GenSigTimeoutTime_ALL" SG_ 1153 BCM_Keyfob_Leftcar 5000;
BA_ "InvalidValue" SG_ 1153 BCM_Keyfob_Leftcar "-";
BA_ "GenSigSendType" SG_ 1153 BCM_IDB_Brakelight_Malfunction 4;
BA_ "GenSigTimeoutTime_ALL" SG_ 1153 BCM_IDB_Brakelight_Malfunction 5000;
BA_ "InvalidValue" SG_ 1153 BCM_IDB_Brakelight_Malfunction "-";
BA_ "GenSigSendType" SG_ 1153 BCM_VCU_Brakelight_Malfunction 4;
BA_ "GenSigTimeoutTime_ALL" SG_ 1153 BCM_VCU_Brakelight_Malfunction 5000;
BA_ "InvalidValue" SG_ 1153 BCM_VCU_Brakelight_Malfunction "-";
BA_ "GenSigSendType" SG_ 1153 BCM_ADAS_Turnlight_Malfunction 4;
BA_ "GenSigTimeoutTime_ALL" SG_ 1153 BCM_ADAS_Turnlight_Malfunction 5000;
BA_ "InvalidValue" SG_ 1153 BCM_ADAS_Turnlight_Malfunction "-";
BA_ "GenSigSendType" SG_ 1153 BCM_ADAS_Highbeam_Malfunction 4;
BA_ "GenSigTimeoutTime_ALL" SG_ 1153 BCM_ADAS_Highbeam_Malfunction 5000;
BA_ "InvalidValue" SG_ 1153 BCM_ADAS_Highbeam_Malfunction "-";
BA_ "GenSigSendType" SG_ 1153 BCM_ADAS_LowBeam_Malfunction 4;
BA_ "GenSigTimeoutTime_ALL" SG_ 1153 BCM_ADAS_LowBeam_Malfunction 5000;
BA_ "InvalidValue" SG_ 1153 BCM_ADAS_LowBeam_Malfunction "-";
BA_ "GenSigSendType" SG_ 1153 BCM_MHU_Malfunction 4;
BA_ "GenSigTimeoutTime_ALL" SG_ 1153 BCM_MHU_Malfunction 5000;
BA_ "InvalidValue" SG_ 1153 BCM_MHU_Malfunction "-";
BA_ "GenSigSendType" SG_ 1153 BCM_BCM_Malfunction 4;
BA_ "GenSigTimeoutTime_ALL" SG_ 1153 BCM_BCM_Malfunction 5000;
BA_ "InvalidValue" SG_ 1153 BCM_BCM_Malfunction "-";
BA_ "GenSigSendType" SG_ 1153 BCM_SCM_Malfunction 4;
BA_ "GenSigTimeoutTime_ALL" SG_ 1153 BCM_SCM_Malfunction 5000;
BA_ "InvalidValue" SG_ 1153 BCM_SCM_Malfunction "-";
BA_ "GenSigSendType" SG_ 1153 BCM_CrashSignalDefect 4;
BA_ "GenSigTimeoutTime_ALL" SG_ 1153 BCM_CrashSignalDefect 5000;
BA_ "InvalidValue" SG_ 1153 BCM_CrashSignalDefect "-";
BA_ "GenSigSendType" SG_ 1153 BCM_FrontWiperDefect 4;
BA_ "GenSigTimeoutTime_ALL" SG_ 1153 BCM_FrontWiperDefect 5000;
BA_ "InvalidValue" SG_ 1153 BCM_FrontWiperDefect "-";
BA_ "GenSigSendType" SG_ 1153 BCM_Rear_RightDoorLockDefect 4;
BA_ "GenSigTimeoutTime_ALL" SG_ 1153 BCM_Rear_RightDoorLockDefect 5000;
BA_ "InvalidValue" SG_ 1153 BCM_Rear_RightDoorLockDefect "-";
BA_ "GenSigSendType" SG_ 1153 BCM_RearLeftDoorLockDefect 4;
BA_ "GenSigTimeoutTime_ALL" SG_ 1153 BCM_RearLeftDoorLockDefect 5000;
BA_ "InvalidValue" SG_ 1153 BCM_RearLeftDoorLockDefect "-";
BA_ "GenSigSendType" SG_ 1153 BCM_Front_RightDoorLockDefect 4;
BA_ "GenSigTimeoutTime_ALL" SG_ 1153 BCM_Front_RightDoorLockDefect 5000;
BA_ "InvalidValue" SG_ 1153 BCM_Front_RightDoorLockDefect "-";
BA_ "GenSigSendType" SG_ 1153 BCM_FrontLeftDoorLockDefect 4;
BA_ "GenSigTimeoutTime_ALL" SG_ 1153 BCM_FrontLeftDoorLockDefect 5000;
BA_ "InvalidValue" SG_ 1153 BCM_FrontLeftDoorLockDefect "-";
BA_ "GenSigSendType" SG_ 1153 BCM_LDML_Malfunction 4;
BA_ "GenSigTimeoutTime_ALL" SG_ 1153 BCM_LDML_Malfunction 5000;
BA_ "InvalidValue" SG_ 1153 BCM_LDML_Malfunction "-";
BA_ "GenSigSendType" SG_ 1153 BCM_LDMR_Malfunction 4;
BA_ "GenSigTimeoutTime_ALL" SG_ 1153 BCM_LDMR_Malfunction 5000;
BA_ "InvalidValue" SG_ 1153 BCM_LDMR_Malfunction "-";
BA_ "GenSigSendType" SG_ 1153 BCM_RLBL_Malfunction 4;
BA_ "GenSigTimeoutTime_ALL" SG_ 1153 BCM_RLBL_Malfunction 5000;
BA_ "InvalidValue" SG_ 1153 BCM_RLBL_Malfunction "-";
BA_ "GenSigSendType" SG_ 1153 BCM_RLBR_Malfunction 4;
BA_ "GenSigTimeoutTime_ALL" SG_ 1153 BCM_RLBR_Malfunction 5000;
BA_ "InvalidValue" SG_ 1153 BCM_RLBR_Malfunction "-";
BA_ "GenSigSendType" SG_ 1153 BCM_RLT_Malfunction 4;
BA_ "GenSigTimeoutTime_ALL" SG_ 1153 BCM_RLT_Malfunction 5000;
BA_ "InvalidValue" SG_ 1153 BCM_RLT_Malfunction "-";
BA_ "GenSigSendType" SG_ 1153 BCM_BCM_POWER_Malfunction 4;
BA_ "GenSigTimeoutTime_ALL" SG_ 1153 BCM_BCM_POWER_Malfunction 5000;
BA_ "InvalidValue" SG_ 1153 BCM_BCM_POWER_Malfunction "-";
BA_ "GenSigSendType" SG_ 1153 BCM_IDB_AutoHazardBlinking_Malf 4;
BA_ "GenSigTimeoutTime_ALL" SG_ 1153 BCM_IDB_AutoHazardBlinking_Malf 5000;
BA_ "InvalidValue" SG_ 1153 BCM_IDB_AutoHazardBlinking_Malf "-";
BA_ "GenSigTimeoutTime_ALL" SG_ 1155 TPMS_FLTirePress 500;
BA_ "InvalidValue" SG_ 1155 TPMS_FLTirePress "FFh";
BA_ "GenSigTimeoutTime_ALL" SG_ 1155 TPMS_FRTirePress 500;
BA_ "InvalidValue" SG_ 1155 TPMS_FRTirePress "FFh";
BA_ "GenSigTimeoutTime_ALL" SG_ 1155 TPMS_RLTirePress 500;
BA_ "InvalidValue" SG_ 1155 TPMS_RLTirePress "FFh";
BA_ "GenSigTimeoutTime_ALL" SG_ 1155 TPMS_RRTirePress 500;
BA_ "InvalidValue" SG_ 1155 TPMS_RRTirePress "FFh";
BA_ "GenSigTimeoutTime_ALL" SG_ 1155 TPMS_FLTirePressAlarm 500;
BA_ "InvalidValue" SG_ 1155 TPMS_FLTirePressAlarm "0";
BA_ "GenSigTimeoutTime_ALL" SG_ 1155 TPMS_FRTirePressAlarm 500;
BA_ "InvalidValue" SG_ 1155 TPMS_FRTirePressAlarm "null";
BA_ "GenSigTimeoutTime_ALL" SG_ 1155 TPMS_RLTirePressAlarm 500;
BA_ "InvalidValue" SG_ 1155 TPMS_RLTirePressAlarm "0";
BA_ "GenSigTimeoutTime_ALL" SG_ 1155 TPMS_RRTirePressAlarm 500;
BA_ "InvalidValue" SG_ 1155 TPMS_RRTirePressAlarm "null";
BA_ "GenSigTimeoutTime_ALL" SG_ 1155 TPMS_TirePosition 500;
BA_ "InvalidValue" SG_ 1155 TPMS_TirePosition "null";
BA_ "GenSigTimeoutTime_ALL" SG_ 1155 TPMS_ready2learning 500;
BA_ "InvalidValue" SG_ 1155 TPMS_ready2learning "0";
BA_ "GenSigTimeoutTime_ALL" SG_ 1155 TPMS_TireTempAlarm 500;
BA_ "InvalidValue" SG_ 1155 TPMS_TireTempAlarm "null";
BA_ "GenSigTimeoutTime_ALL" SG_ 1155 TPMS_LearningStatus 500;
BA_ "InvalidValue" SG_ 1155 TPMS_LearningStatus "0";
BA_ "GenSigStartValue" SG_ 1155 TPMS_TireTemp 68;
BA_ "GenSigTimeoutTime_ALL" SG_ 1155 TPMS_TireTemp 500;
BA_ "InvalidValue" SG_ 1155 TPMS_TireTemp "FFh";
BA_ "GenSigSendType" SG_ 1160 CHKSM_ACM_WARNING_MSG 3;
BA_ "GenSigTimeoutTime_ALL" SG_ 1160 CHKSM_ACM_WARNING_MSG 5000;
BA_ "InvalidValue" SG_ 1160 CHKSM_ACM_WARNING_MSG "null";
BA_ "GenSigSendType" SG_ 1160 ALV_ACM_WARNING_MSG 3;
BA_ "GenSigTimeoutTime_ALL" SG_ 1160 ALV_ACM_WARNING_MSG 5000;
BA_ "InvalidValue" SG_ 1160 ALV_ACM_WARNING_MSG "Fh";
BA_ "GenSigSendType" SG_ 1160 ACM_Malfunction 4;
BA_ "GenSigTimeoutTime_ALL" SG_ 1160 ACM_Malfunction 5000;
BA_ "InvalidValue" SG_ 1160 ACM_Malfunction "null";
BA_ "GenSigSendType" SG_ 1160 ACM_Pre_Drive_Check 4;
BA_ "GenSigTimeoutTime_ALL" SG_ 1160 ACM_Pre_Drive_Check 5000;
BA_ "InvalidValue" SG_ 1160 ACM_Pre_Drive_Check "null";
BA_ "GenSigSendType" SG_ 1160 ACM_in_Plant_Mode 4;
BA_ "GenSigTimeoutTime_ALL" SG_ 1160 ACM_in_Plant_Mode 5000;
BA_ "InvalidValue" SG_ 1160 ACM_in_Plant_Mode "null";
BA_ "GenSigSendType" SG_ 1160 ACM_PAB_Suppression 4;
BA_ "GenSigTimeoutTime_ALL" SG_ 1160 ACM_PAB_Suppression 5000;
BA_ "InvalidValue" SG_ 1160 ACM_PAB_Suppression "3h";
BA_ "GenSigSendType" SG_ 1160 ACM_Airbag_Disabled 4;
BA_ "GenSigTimeoutTime_ALL" SG_ 1160 ACM_Airbag_Disabled 5000;
BA_ "InvalidValue" SG_ 1160 ACM_Airbag_Disabled "null";
BA_ "GenSigSendType" SG_ 1160 ACM_Development_Calibration 4;
BA_ "GenSigTimeoutTime_ALL" SG_ 1160 ACM_Development_Calibration 5000;
BA_ "InvalidValue" SG_ 1160 ACM_Development_Calibration "null";
BA_ "GenSigSendType" SG_ 1160 ACM_In_Disposal_Mode 4;
BA_ "GenSigTimeoutTime_ALL" SG_ 1160 ACM_In_Disposal_Mode 5000;
BA_ "InvalidValue" SG_ 1160 ACM_In_Disposal_Mode "null";
BA_ "GenSigSendType" SG_ 1160 ACM_Seatbelt_Reminder_Request 4;
BA_ "GenSigTimeoutTime_ALL" SG_ 1160 ACM_Seatbelt_Reminder_Request 5000;
BA_ "InvalidValue" SG_ 1160 ACM_Seatbelt_Reminder_Request "null";
BA_ "GenSigSendType" SG_ 1160 ACM_SBR_Chime_Req 4;
BA_ "GenSigTimeoutTime_ALL" SG_ 1160 ACM_SBR_Chime_Req 5000;
BA_ "InvalidValue" SG_ 1160 ACM_SBR_Chime_Req "null";
BA_ "GenSigSendType" SG_ 1160 ACM_SBR_Blinking_Req 4;
BA_ "GenSigTimeoutTime_ALL" SG_ 1160 ACM_SBR_Blinking_Req 5000;
BA_ "InvalidValue" SG_ 1160 ACM_SBR_Blinking_Req "null";
BA_ "GenSigTimeoutTime_ALL" SG_ 1161 CHSKM_CCU_WarnMsg 500;
BA_ "InvalidValue" SG_ 1161 CHSKM_CCU_WarnMsg "null";
BA_ "GenSigTimeoutTime_ALL" SG_ 1161 ALV_CCU_WarnMsg 500;
BA_ "InvalidValue" SG_ 1161 ALV_CCU_WarnMsg "Fh";
BA_ "GenSigTimeoutTime_ALL" SG_ 1161 CCU_Malfunction 500;
BA_ "InvalidValue" SG_ 1161 CCU_Malfunction "null";
BA_ "GenSigTimeoutTime_ALL" SG_ 1161 CCU_Warning_Flag_2 500;
BA_ "InvalidValue" SG_ 1161 CCU_Warning_Flag_2 "null";
BA_ "GenSigTimeoutTime_ALL" SG_ 1161 CCU_Warning_Flag_3 500;
BA_ "InvalidValue" SG_ 1161 CCU_Warning_Flag_3 "null";
BA_ "GenSigTimeoutTime_ALL" SG_ 1161 CCU_Warning_Flag_4 500;
BA_ "InvalidValue" SG_ 1161 CCU_Warning_Flag_4 "null";
BA_ "GenSigTimeoutTime_ALL" SG_ 1161 CCU_Warning_Flag_5 500;
BA_ "InvalidValue" SG_ 1161 CCU_Warning_Flag_5 "null";
BA_ "GenSigTimeoutTime_ALL" SG_ 1161 CCU_Warning_Flag_6 500;
BA_ "InvalidValue" SG_ 1161 CCU_Warning_Flag_6 "null";
BA_ "GenSigTimeoutTime_ALL" SG_ 1161 CCU_Warning_Flag_7 500;
BA_ "InvalidValue" SG_ 1161 CCU_Warning_Flag_7 "null";
BA_ "GenSigTimeoutTime_ALL" SG_ 1161 CCU_Warning_Flag_8 500;
BA_ "InvalidValue" SG_ 1161 CCU_Warning_Flag_8 "null";
BA_ "GenSigTimeoutTime_ALL" SG_ 1161 CCU_Warning_Flag_9 500;
BA_ "InvalidValue" SG_ 1161 CCU_Warning_Flag_9 "null";
BA_ "GenSigTimeoutTime_ALL" SG_ 1161 CCU_Warning_Flag_10 500;
BA_ "InvalidValue" SG_ 1161 CCU_Warning_Flag_10 "null";
BA_ "GenSigTimeoutTime_ALL" SG_ 1161 CCU_Warning_Flag_11 500;
BA_ "InvalidValue" SG_ 1161 CCU_Warning_Flag_11 "null";
BA_ "GenSigTimeoutTime_ALL" SG_ 1161 CCU_Warning_Flag_12 500;
BA_ "InvalidValue" SG_ 1161 CCU_Warning_Flag_12 "null";
BA_ "GenSigTimeoutTime_ALL" SG_ 1166 CHSKM_ETG_WarnMsg 500;
BA_ "InvalidValue" SG_ 1166 CHSKM_ETG_WarnMsg "null";
BA_ "GenSigTimeoutTime_ALL" SG_ 1166 ALV_ETG_WarnMsg 500;
BA_ "InvalidValue" SG_ 1166 ALV_ETG_WarnMsg "Fh";
BA_ "GenSigTimeoutTime_ALL" SG_ 1166 ETG_Malfunction 500;
BA_ "InvalidValue" SG_ 1166 ETG_Malfunction "null";
BA_ "GenSigTimeoutTime_ALL" SG_ 1166 ETG_Warning_Flag_2 500;
BA_ "InvalidValue" SG_ 1166 ETG_Warning_Flag_2 "null";
BA_ "GenSigTimeoutTime_ALL" SG_ 1166 ETG_Warning_Flag_3 500;
BA_ "InvalidValue" SG_ 1166 ETG_Warning_Flag_3 "null";
BA_ "GenSigTimeoutTime_ALL" SG_ 1166 ETG_Warning_Flag_4 500;
BA_ "InvalidValue" SG_ 1166 ETG_Warning_Flag_4 "null";
BA_ "GenSigTimeoutTime_ALL" SG_ 1166 ETG_Warning_Flag_5 500;
BA_ "InvalidValue" SG_ 1166 ETG_Warning_Flag_5 "null";
BA_ "GenSigTimeoutTime_ALL" SG_ 1166 ETG_Warning_Flag_6 500;
BA_ "InvalidValue" SG_ 1166 ETG_Warning_Flag_6 "null";
BA_ "GenSigTimeoutTime_ALL" SG_ 1166 ETG_Warning_Flag_7 500;
BA_ "InvalidValue" SG_ 1166 ETG_Warning_Flag_7 "null";
BA_ "GenSigTimeoutTime_ALL" SG_ 1166 ETG_Warning_Flag_8 500;
BA_ "InvalidValue" SG_ 1166 ETG_Warning_Flag_8 "null";
BA_ "GenSigTimeoutTime_ALL" SG_ 1166 ETG_Warning_Flag_9 500;
BA_ "InvalidValue" SG_ 1166 ETG_Warning_Flag_9 "null";
BA_ "GenSigTimeoutTime_ALL" SG_ 1166 ETG_Warning_Flag_10 500;
BA_ "InvalidValue" SG_ 1166 ETG_Warning_Flag_10 "null";
BA_ "GenSigTimeoutTime_ALL" SG_ 1166 ETG_Warning_Flag_11 500;
BA_ "InvalidValue" SG_ 1166 ETG_Warning_Flag_11 "null";
BA_ "GenSigTimeoutTime_ALL" SG_ 1166 ETG_Warning_Flag_12 500;
BA_ "InvalidValue" SG_ 1166 ETG_Warning_Flag_12 "null";
BA_ "GenSigSendType" SG_ 1171 CHSKM_BMS_WarnMsg 3;
BA_ "GenSigTimeoutTime_ALL" SG_ 1171 CHSKM_BMS_WarnMsg 5000;
BA_ "InvalidValue" SG_ 1171 CHSKM_BMS_WarnMsg "null";
BA_ "GenSigSendType" SG_ 1171 ALV_BMS_WarnMsg 3;
BA_ "GenSigTimeoutTime_ALL" SG_ 1171 ALV_BMS_WarnMsg 5000;
BA_ "InvalidValue" SG_ 1171 ALV_BMS_WarnMsg "Fh";
BA_ "GenSigSendType" SG_ 1171 BMS_PackTempSts 4;
BA_ "GenSigTimeoutTime_ALL" SG_ 1171 BMS_PackTempSts 5000;
BA_ "InvalidValue" SG_ 1171 BMS_PackTempSts "null";
BA_ "GenSigSendType" SG_ 1171 BMS_ThermalRunaway 4;
BA_ "GenSigTimeoutTime_ALL" SG_ 1171 BMS_ThermalRunaway 5000;
BA_ "InvalidValue" SG_ 1171 BMS_ThermalRunaway "null";
BA_ "GenSigSendType" SG_ 1171 BMS_BatteryReplacement 4;
BA_ "GenSigTimeoutTime_ALL" SG_ 1171 BMS_BatteryReplacement 5000;
BA_ "InvalidValue" SG_ 1171 BMS_BatteryReplacement "null";
BA_ "GenSigSendType" SG_ 1171 BMS_Warning_PowerDegrade 4;
BA_ "GenSigTimeoutTime_ALL" SG_ 1171 BMS_Warning_PowerDegrade 5000;
BA_ "InvalidValue" SG_ 1171 BMS_Warning_PowerDegrade "null";
BA_ "GenSigSendType" SG_ 1171 BMS_Warning_DeltaSoC 4;
BA_ "GenSigTimeoutTime_ALL" SG_ 1171 BMS_Warning_DeltaSoC 5000;
BA_ "InvalidValue" SG_ 1171 BMS_Warning_DeltaSoC "null";
BA_ "GenSigSendType" SG_ 1171 BMS_Warning_HVILSts 4;
BA_ "GenSigTimeoutTime_ALL" SG_ 1171 BMS_Warning_HVILSts 5000;
BA_ "InvalidValue" SG_ 1171 BMS_Warning_HVILSts "null";
BA_ "GenSigSendType" SG_ 1171 BMS_Warning_Isolation 4;
BA_ "GenSigTimeoutTime_ALL" SG_ 1171 BMS_Warning_Isolation 5000;
BA_ "InvalidValue" SG_ 1171 BMS_Warning_Isolation "null";
BA_ "GenSigSendType" SG_ 1171 BMS_Warning_CoolantLeakage 4;
BA_ "GenSigTimeoutTime_ALL" SG_ 1171 BMS_Warning_CoolantLeakage 5000;
BA_ "InvalidValue" SG_ 1171 BMS_Warning_CoolantLeakage "null";
BA_ "GenSigSendType" SG_ 1171 BMS_MalfunctionSts 4;
BA_ "GenSigTimeoutTime_ALL" SG_ 1171 BMS_MalfunctionSts 5000;
BA_ "InvalidValue" SG_ 1171 BMS_MalfunctionSts "null";
BA_ "GenSigSendType" SG_ 1171 BMS_LowBattery 4;
BA_ "GenSigTimeoutTime_ALL" SG_ 1171 BMS_LowBattery 5000;
BA_ "InvalidValue" SG_ 1171 BMS_LowBattery "null";
BA_ "GenSigSendType" SG_ 1171 BMS_Warning_DeltaTemperature 4;
BA_ "GenSigTimeoutTime_ALL" SG_ 1171 BMS_Warning_DeltaTemperature 5000;
BA_ "InvalidValue" SG_ 1171 BMS_Warning_DeltaTemperature "null";
BA_ "GenSigSendType" SG_ 1171 BMS_Warning_BDUTemperatureSts 4;
BA_ "GenSigTimeoutTime_ALL" SG_ 1171 BMS_Warning_BDUTemperatureSts 5000;
BA_ "InvalidValue" SG_ 1171 BMS_Warning_BDUTemperatureSts "null";
BA_ "GenSigTimeoutTime_ALL" SG_ 1171 BMS_Warning_Contactor_Aging 5000;
BA_ "GenSigSendType" SG_ 1171 BMS_Warning_Contactor_Aging 4;
BA_ "GenSigSendType" SG_ 1171 BMS_Reserved_signal4 4;
BA_ "GenSigTimeoutTime_ALL" SG_ 1171 BMS_Reserved_signal4 5000;
BA_ "InvalidValue" SG_ 1171 BMS_Reserved_signal4 "null";
BA_ "GenSigSendType" SG_ 1171 BMS_Reserved_signal5 4;
BA_ "GenSigTimeoutTime_ALL" SG_ 1171 BMS_Reserved_signal5 5000;
BA_ "InvalidValue" SG_ 1171 BMS_Reserved_signal5 "null";
BA_ "GenSigTimeoutTime_ALL" SG_ 1211 CHSKM_TRM_WarnMsg 500;
BA_ "InvalidValue" SG_ 1211 CHSKM_TRM_WarnMsg "null";
BA_ "GenSigTimeoutTime_ALL" SG_ 1211 ALV_TRM_WarnMsg 500;
BA_ "InvalidValue" SG_ 1211 ALV_TRM_WarnMsg "Fh";
BA_ "GenSigTimeoutTime_ALL" SG_ 1211 TRM_LightMalfnc 500;
BA_ "InvalidValue" SG_ 1211 TRM_LightMalfnc "null";
BA_ "GenSigTimeoutTime_ALL" SG_ 1211 TRM_TurnLeftMafnc 500;
BA_ "InvalidValue" SG_ 1211 TRM_TurnLeftMafnc "null";
BA_ "GenSigTimeoutTime_ALL" SG_ 1211 TRM_TurnRightMafnc 500;
BA_ "InvalidValue" SG_ 1211 TRM_TurnRightMafnc "null";
BA_ "GenSigTimeoutTime_ALL" SG_ 1211 TRM_TrailerMalfnc 500;
BA_ "InvalidValue" SG_ 1211 TRM_TrailerMalfnc "null";
BA_ "GenSigTimeoutTime_ALL" SG_ 1211 TRM_Warning_Flag_5 500;
BA_ "InvalidValue" SG_ 1211 TRM_Warning_Flag_5 "null";
BA_ "GenSigTimeoutTime_ALL" SG_ 1211 TRM_Warning_Flag_6 500;
BA_ "InvalidValue" SG_ 1211 TRM_Warning_Flag_6 "null";
BA_ "GenSigTimeoutTime_ALL" SG_ 1211 TRM_Warning_Flag_7 500;
BA_ "InvalidValue" SG_ 1211 TRM_Warning_Flag_7 "null";
BA_ "GenSigTimeoutTime_ALL" SG_ 1211 TRM_Warning_Flag_8 500;
BA_ "InvalidValue" SG_ 1211 TRM_Warning_Flag_8 "null";
BA_ "GenSigTimeoutTime_ALL" SG_ 1211 TRM_Warning_Flag_9 500;
BA_ "InvalidValue" SG_ 1211 TRM_Warning_Flag_9 "null";
BA_ "GenSigTimeoutTime_ALL" SG_ 1211 TRM_Warning_Flag_10 500;
BA_ "InvalidValue" SG_ 1211 TRM_Warning_Flag_10 "null";
BA_ "GenSigTimeoutTime_ALL" SG_ 1211 TRM_Warning_Flag_11 500;
BA_ "InvalidValue" SG_ 1211 TRM_Warning_Flag_11 "null";
BA_ "GenSigTimeoutTime_ALL" SG_ 1211 TRM_Warning_Flag_12 500;
BA_ "InvalidValue" SG_ 1211 TRM_Warning_Flag_12 "null";
BA_ "GenSigSendType" SG_ 1216 BCM_STAT_DoorHandleRR 3;
BA_ "GenSigSendType" SG_ 1216 BCM_STAT_DoorHandleRL 3;
BA_ "GenSigSendType" SG_ 1216 BCM_STAT_DoorHandleFR 3;
BA_ "GenSigSendType" SG_ 1216 BCM_STAT_DoorHandleFL 3;
BA_ "GenSigSendType" SG_ 1217 CHSKM_APM_WarnMsg 3;
BA_ "GenSigTimeoutTime_ALL" SG_ 1217 CHSKM_APM_WarnMsg 5000;
BA_ "GenSigSendType" SG_ 1217 ALV_APM_WarnMsg 3;
BA_ "GenSigTimeoutTime_ALL" SG_ 1217 ALV_APM_WarnMsg 5000;
BA_ "InvalidValue" SG_ 1217 ALV_APM_WarnMsg "Fh";
BA_ "GenSigSendType" SG_ 1217 APM_Malfunction 4;
BA_ "GenSigTimeoutTime_ALL" SG_ 1217 APM_Malfunction 5000;
BA_ "InvalidValue" SG_ 1217 APM_Malfunction "null";
BA_ "GenSigSendType" SG_ 1217 ChildWindowLockStS 4;
BA_ "GenSigTimeoutTime_ALL" SG_ 1217 ChildWindowLockStS 5000;
BA_ "GenSigSendType" SG_ 1217 APM_Warning_Flag_3 4;
BA_ "GenSigTimeoutTime_ALL" SG_ 1217 APM_Warning_Flag_3 5000;
BA_ "GenSigSendType" SG_ 1217 APM_Warning_Flag_4 4;
BA_ "GenSigTimeoutTime_ALL" SG_ 1217 APM_Warning_Flag_4 5000;
BA_ "GenSigSendType" SG_ 1217 APM_Warning_Flag_5 4;
BA_ "GenSigTimeoutTime_ALL" SG_ 1217 APM_Warning_Flag_5 5000;
BA_ "GenSigSendType" SG_ 1217 APM_Warning_Flag_6 4;
BA_ "GenSigTimeoutTime_ALL" SG_ 1217 APM_Warning_Flag_6 5000;
BA_ "GenSigSendType" SG_ 1217 APM_Warning_Flag_7 4;
BA_ "GenSigTimeoutTime_ALL" SG_ 1217 APM_Warning_Flag_7 5000;
BA_ "GenSigSendType" SG_ 1217 APM_Warning_Flag_8 4;
BA_ "GenSigTimeoutTime_ALL" SG_ 1217 APM_Warning_Flag_8 5000;
BA_ "GenSigSendType" SG_ 1217 APM_Warning_Flag_9 4;
BA_ "GenSigTimeoutTime_ALL" SG_ 1217 APM_Warning_Flag_9 5000;
BA_ "GenSigSendType" SG_ 1217 APM_Warning_Flag_10 4;
BA_ "GenSigTimeoutTime_ALL" SG_ 1217 APM_Warning_Flag_10 5000;
BA_ "GenSigSendType" SG_ 1217 APM_Warning_Flag_11 4;
BA_ "GenSigTimeoutTime_ALL" SG_ 1217 APM_Warning_Flag_11 5000;
BA_ "GenSigSendType" SG_ 1217 APM_Warning_Flag_12 4;
BA_ "GenSigTimeoutTime_ALL" SG_ 1217 APM_Warning_Flag_12 5000;
BA_ "GenSigTimeoutTime_ALL" SG_ 1281 BCM_srcNodeID 2000;
BA_ "InvalidValue" SG_ 1281 BCM_srcNodeID "null";
BA_ "GenSigTimeoutTime_ALL" SG_ 1281 BCM_CtrlBitVector 2000;
BA_ "InvalidValue" SG_ 1281 BCM_CtrlBitVector "null";
BA_ "GenSigStartValue" SG_ 1281 BCM_usrData0 255;
BA_ "GenSigTimeoutTime_ALL" SG_ 1281 BCM_usrData0 2000;
BA_ "InvalidValue" SG_ 1281 BCM_usrData0 "null";
BA_ "GenSigStartValue" SG_ 1281 BCM_usrData1 255;
BA_ "GenSigTimeoutTime_ALL" SG_ 1281 BCM_usrData1 2000;
BA_ "InvalidValue" SG_ 1281 BCM_usrData1 "null";
BA_ "GenSigStartValue" SG_ 1281 BCM_usrData2 255;
BA_ "GenSigTimeoutTime_ALL" SG_ 1281 BCM_usrData2 2000;
BA_ "InvalidValue" SG_ 1281 BCM_usrData2 "null";
BA_ "GenSigStartValue" SG_ 1281 BCM_usrData3 255;
BA_ "GenSigTimeoutTime_ALL" SG_ 1281 BCM_usrData3 2000;
BA_ "InvalidValue" SG_ 1281 BCM_usrData3 "null";
BA_ "GenSigStartValue" SG_ 1281 BCM_usrData4 255;
BA_ "GenSigTimeoutTime_ALL" SG_ 1281 BCM_usrData4 2000;
BA_ "InvalidValue" SG_ 1281 BCM_usrData4 "null";
BA_ "GenSigStartValue" SG_ 1281 BCM_usrData5 255;
BA_ "GenSigTimeoutTime_ALL" SG_ 1281 BCM_usrData5 2000;
BA_ "InvalidValue" SG_ 1281 BCM_usrData5 "null";
BA_ "GenSigTimeoutTime_ALL" SG_ 1282 XGW_srcNodeID 2000;
BA_ "InvalidValue" SG_ 1282 XGW_srcNodeID "null";
BA_ "GenSigTimeoutTime_ALL" SG_ 1282 XGW_CtrlBitVector 2000;
BA_ "InvalidValue" SG_ 1282 XGW_CtrlBitVector "null";
BA_ "GenSigStartValue" SG_ 1282 XGW_usrData0 255;
BA_ "GenSigTimeoutTime_ALL" SG_ 1282 XGW_usrData0 2000;
BA_ "InvalidValue" SG_ 1282 XGW_usrData0 "null";
BA_ "GenSigStartValue" SG_ 1282 XGW_usrData1 255;
BA_ "GenSigTimeoutTime_ALL" SG_ 1282 XGW_usrData1 2000;
BA_ "InvalidValue" SG_ 1282 XGW_usrData1 "null";
BA_ "GenSigStartValue" SG_ 1282 XGW_usrData2 255;
BA_ "GenSigTimeoutTime_ALL" SG_ 1282 XGW_usrData2 2000;
BA_ "InvalidValue" SG_ 1282 XGW_usrData2 "null";
BA_ "GenSigStartValue" SG_ 1282 XGW_usrData3 255;
BA_ "GenSigTimeoutTime_ALL" SG_ 1282 XGW_usrData3 2000;
BA_ "InvalidValue" SG_ 1282 XGW_usrData3 "null";
BA_ "GenSigStartValue" SG_ 1282 XGW_usrData4 255;
BA_ "GenSigTimeoutTime_ALL" SG_ 1282 XGW_usrData4 2000;
BA_ "InvalidValue" SG_ 1282 XGW_usrData4 "null";
BA_ "GenSigStartValue" SG_ 1282 XGW_usrData5 255;
BA_ "GenSigTimeoutTime_ALL" SG_ 1282 XGW_usrData5 2000;
BA_ "InvalidValue" SG_ 1282 XGW_usrData5 "null";
BA_ "GenSigTimeoutTime_ALL" SG_ 1289 CCUF_srcNodeID 2000;
BA_ "InvalidValue" SG_ 1289 CCUF_srcNodeID "null";
BA_ "GenSigTimeoutTime_ALL" SG_ 1289 CCUF_CtrlBitVector 2000;
BA_ "InvalidValue" SG_ 1289 CCUF_CtrlBitVector "null";
BA_ "GenSigStartValue" SG_ 1289 CCUF_usrData0 255;
BA_ "GenSigTimeoutTime_ALL" SG_ 1289 CCUF_usrData0 2000;
BA_ "InvalidValue" SG_ 1289 CCUF_usrData0 "null";
BA_ "GenSigStartValue" SG_ 1289 CCUF_usrData1 255;
BA_ "GenSigTimeoutTime_ALL" SG_ 1289 CCUF_usrData1 2000;
BA_ "InvalidValue" SG_ 1289 CCUF_usrData1 "null";
BA_ "GenSigStartValue" SG_ 1289 CCUF_usrData2 255;
BA_ "GenSigTimeoutTime_ALL" SG_ 1289 CCUF_usrData2 2000;
BA_ "InvalidValue" SG_ 1289 CCUF_usrData2 "null";
BA_ "GenSigStartValue" SG_ 1289 CCUF_usrData3 255;
BA_ "GenSigTimeoutTime_ALL" SG_ 1289 CCUF_usrData3 2000;
BA_ "InvalidValue" SG_ 1289 CCUF_usrData3 "null";
BA_ "GenSigStartValue" SG_ 1289 CCUF_usrData4 255;
BA_ "GenSigTimeoutTime_ALL" SG_ 1289 CCUF_usrData4 2000;
BA_ "InvalidValue" SG_ 1289 CCUF_usrData4 "null";
BA_ "GenSigStartValue" SG_ 1289 CCUF_usrData5 255;
BA_ "GenSigTimeoutTime_ALL" SG_ 1289 CCUF_usrData5 2000;
BA_ "InvalidValue" SG_ 1289 CCUF_usrData5 "null";
BA_ "GenSigTimeoutTime_ALL" SG_ 1294 ETG_srcNodeID 2000;
BA_ "InvalidValue" SG_ 1294 ETG_srcNodeID "null";
BA_ "GenSigTimeoutTime_ALL" SG_ 1294 ETG_CtrlBitVector 2000;
BA_ "InvalidValue" SG_ 1294 ETG_CtrlBitVector "null";
BA_ "GenSigStartValue" SG_ 1294 ETG_usrData0 255;
BA_ "GenSigTimeoutTime_ALL" SG_ 1294 ETG_usrData0 2000;
BA_ "InvalidValue" SG_ 1294 ETG_usrData0 "null";
BA_ "GenSigStartValue" SG_ 1294 ETG_usrData1 255;
BA_ "GenSigTimeoutTime_ALL" SG_ 1294 ETG_usrData1 2000;
BA_ "InvalidValue" SG_ 1294 ETG_usrData1 "null";
BA_ "GenSigStartValue" SG_ 1294 ETG_usrData2 255;
BA_ "GenSigTimeoutTime_ALL" SG_ 1294 ETG_usrData2 2000;
BA_ "InvalidValue" SG_ 1294 ETG_usrData2 "null";
BA_ "GenSigStartValue" SG_ 1294 ETG_usrData3 255;
BA_ "GenSigTimeoutTime_ALL" SG_ 1294 ETG_usrData3 2000;
BA_ "InvalidValue" SG_ 1294 ETG_usrData3 "null";
BA_ "GenSigStartValue" SG_ 1294 ETG_usrData4 255;
BA_ "GenSigTimeoutTime_ALL" SG_ 1294 ETG_usrData4 2000;
BA_ "InvalidValue" SG_ 1294 ETG_usrData4 "null";
BA_ "GenSigStartValue" SG_ 1294 ETG_usrData5 255;
BA_ "GenSigTimeoutTime_ALL" SG_ 1294 ETG_usrData5 2000;
BA_ "InvalidValue" SG_ 1294 ETG_usrData5 "null";
BA_ "GenSigTimeoutTime_ALL" SG_ 1310 PSM_D_srcNodeID 2000;
BA_ "InvalidValue" SG_ 1310 PSM_D_srcNodeID "null";
BA_ "GenSigTimeoutTime_ALL" SG_ 1310 PSM_D_CtrlBitVector 2000;
BA_ "InvalidValue" SG_ 1310 PSM_D_CtrlBitVector "null";
BA_ "GenSigStartValue" SG_ 1310 PSM_D_usrData0 255;
BA_ "GenSigTimeoutTime_ALL" SG_ 1310 PSM_D_usrData0 2000;
BA_ "InvalidValue" SG_ 1310 PSM_D_usrData0 "null";
BA_ "GenSigStartValue" SG_ 1310 PSM_D_usrData1 255;
BA_ "GenSigTimeoutTime_ALL" SG_ 1310 PSM_D_usrData1 2000;
BA_ "InvalidValue" SG_ 1310 PSM_D_usrData1 "null";
BA_ "GenSigStartValue" SG_ 1310 PSM_D_usrData2 255;
BA_ "GenSigTimeoutTime_ALL" SG_ 1310 PSM_D_usrData2 2000;
BA_ "InvalidValue" SG_ 1310 PSM_D_usrData2 "null";
BA_ "GenSigStartValue" SG_ 1310 PSM_D_usrData3 255;
BA_ "GenSigTimeoutTime_ALL" SG_ 1310 PSM_D_usrData3 2000;
BA_ "InvalidValue" SG_ 1310 PSM_D_usrData3 "null";
BA_ "GenSigStartValue" SG_ 1310 PSM_D_usrData4 255;
BA_ "GenSigTimeoutTime_ALL" SG_ 1310 PSM_D_usrData4 2000;
BA_ "InvalidValue" SG_ 1310 PSM_D_usrData4 "null";
BA_ "GenSigStartValue" SG_ 1310 PSM_D_usrData5 255;
BA_ "GenSigTimeoutTime_ALL" SG_ 1310 PSM_D_usrData5 2000;
BA_ "InvalidValue" SG_ 1310 PSM_D_usrData5 "null";
BA_ "GenSigTimeoutTime_ALL" SG_ 1339 TRM_srcNodeID 2000;
BA_ "InvalidValue" SG_ 1339 TRM_srcNodeID "FFh";
BA_ "GenSigTimeoutTime_ALL" SG_ 1339 TRM_CtrlBitVector 2000;
BA_ "InvalidValue" SG_ 1339 TRM_CtrlBitVector "null";
BA_ "GenSigStartValue" SG_ 1339 TRM_usrData0 255;
BA_ "GenSigTimeoutTime_ALL" SG_ 1339 TRM_usrData0 2000;
BA_ "InvalidValue" SG_ 1339 TRM_usrData0 "null";
BA_ "GenSigStartValue" SG_ 1339 TRM_usrData1 255;
BA_ "GenSigTimeoutTime_ALL" SG_ 1339 TRM_usrData1 2000;
BA_ "InvalidValue" SG_ 1339 TRM_usrData1 "null";
BA_ "GenSigStartValue" SG_ 1339 TRM_usrData2 255;
BA_ "GenSigTimeoutTime_ALL" SG_ 1339 TRM_usrData2 2000;
BA_ "InvalidValue" SG_ 1339 TRM_usrData2 "null";
BA_ "GenSigStartValue" SG_ 1339 TRM_usrData3 255;
BA_ "GenSigTimeoutTime_ALL" SG_ 1339 TRM_usrData3 2000;
BA_ "InvalidValue" SG_ 1339 TRM_usrData3 "null";
BA_ "GenSigStartValue" SG_ 1339 TRM_usrData4 255;
BA_ "GenSigTimeoutTime_ALL" SG_ 1339 TRM_usrData4 2000;
BA_ "InvalidValue" SG_ 1339 TRM_usrData4 "null";
BA_ "GenSigStartValue" SG_ 1339 TRM_usrData5 255;
BA_ "GenSigTimeoutTime_ALL" SG_ 1339 TRM_usrData5 2000;
BA_ "InvalidValue" SG_ 1339 TRM_usrData5 "null";
BA_ "GenSigTimeoutTime_ALL" SG_ 1344 ADAS_srcNodeID 2000;
BA_ "InvalidValue" SG_ 1344 ADAS_srcNodeID "FFh";
BA_ "GenSigTimeoutTime_ALL" SG_ 1344 ADAS_CtrlBitVector 2000;
BA_ "InvalidValue" SG_ 1344 ADAS_CtrlBitVector "null";
BA_ "GenSigStartValue" SG_ 1344 ADAS_usrData0 255;
BA_ "GenSigTimeoutTime_ALL" SG_ 1344 ADAS_usrData0 2000;
BA_ "InvalidValue" SG_ 1344 ADAS_usrData0 "null";
BA_ "GenSigStartValue" SG_ 1344 ADAS_usrData1 255;
BA_ "GenSigTimeoutTime_ALL" SG_ 1344 ADAS_usrData1 2000;
BA_ "InvalidValue" SG_ 1344 ADAS_usrData1 "null";
BA_ "GenSigStartValue" SG_ 1344 ADAS_usrData2 255;
BA_ "GenSigTimeoutTime_ALL" SG_ 1344 ADAS_usrData2 2000;
BA_ "InvalidValue" SG_ 1344 ADAS_usrData2 "null";
BA_ "GenSigStartValue" SG_ 1344 ADAS_usrData3 255;
BA_ "GenSigTimeoutTime_ALL" SG_ 1344 ADAS_usrData3 2000;
BA_ "InvalidValue" SG_ 1344 ADAS_usrData3 "null";
BA_ "GenSigStartValue" SG_ 1344 ADAS_usrData4 255;
BA_ "GenSigTimeoutTime_ALL" SG_ 1344 ADAS_usrData4 2000;
BA_ "InvalidValue" SG_ 1344 ADAS_usrData4 "null";
BA_ "GenSigStartValue" SG_ 1344 ADAS_usrData5 255;
BA_ "GenSigTimeoutTime_ALL" SG_ 1344 ADAS_usrData5 2000;
BA_ "InvalidValue" SG_ 1344 ADAS_usrData5 "null";
BA_ "GenSigTimeoutTime_ALL" SG_ 1345 APM_srcNodeID 2000;
BA_ "InvalidValue" SG_ 1345 APM_srcNodeID "null";
BA_ "GenSigTimeoutTime_ALL" SG_ 1345 APM_CtrlBitVector 2000;
BA_ "InvalidValue" SG_ 1345 APM_CtrlBitVector "null";
BA_ "GenSigStartValue" SG_ 1345 APM_usrData0 255;
BA_ "GenSigTimeoutTime_ALL" SG_ 1345 APM_usrData0 2000;
BA_ "InvalidValue" SG_ 1345 APM_usrData0 "null";
BA_ "GenSigStartValue" SG_ 1345 APM_usrData1 255;
BA_ "GenSigTimeoutTime_ALL" SG_ 1345 APM_usrData1 2000;
BA_ "InvalidValue" SG_ 1345 APM_usrData1 "null";
BA_ "GenSigStartValue" SG_ 1345 APM_usrData2 255;
BA_ "GenSigTimeoutTime_ALL" SG_ 1345 APM_usrData2 2000;
BA_ "InvalidValue" SG_ 1345 APM_usrData2 "null";
BA_ "GenSigStartValue" SG_ 1345 APM_usrData3 255;
BA_ "GenSigTimeoutTime_ALL" SG_ 1345 APM_usrData3 2000;
BA_ "InvalidValue" SG_ 1345 APM_usrData3 "null";
BA_ "GenSigStartValue" SG_ 1345 APM_usrData4 255;
BA_ "GenSigTimeoutTime_ALL" SG_ 1345 APM_usrData4 2000;
BA_ "InvalidValue" SG_ 1345 APM_usrData4 "null";
BA_ "GenSigStartValue" SG_ 1345 APM_usrData5 255;
BA_ "GenSigTimeoutTime_ALL" SG_ 1345 APM_usrData5 2000;
BA_ "InvalidValue" SG_ 1345 APM_usrData5 "null";
BA_ "GenSigTimeoutTime_ALL" SG_ 1353 LDM_L_srcNodeID 2000;
BA_ "InvalidValue" SG_ 1353 LDM_L_srcNodeID "null";
BA_ "GenSigTimeoutTime_ALL" SG_ 1353 LDM_L_CtrlBitVector 2000;
BA_ "InvalidValue" SG_ 1353 LDM_L_CtrlBitVector "null";
BA_ "GenSigTimeoutTime_ALL" SG_ 1353 LDM_L_usrData0 2000;
BA_ "InvalidValue" SG_ 1353 LDM_L_usrData0 "null";
BA_ "GenSigTimeoutTime_ALL" SG_ 1353 LDM_L_usrData1 2000;
BA_ "InvalidValue" SG_ 1353 LDM_L_usrData1 "null";
BA_ "GenSigTimeoutTime_ALL" SG_ 1353 LDM_L_usrData2 2000;
BA_ "InvalidValue" SG_ 1353 LDM_L_usrData2 "null";
BA_ "GenSigTimeoutTime_ALL" SG_ 1353 LDM_L_usrData3 2000;
BA_ "InvalidValue" SG_ 1353 LDM_L_usrData3 "null";
BA_ "GenSigTimeoutTime_ALL" SG_ 1353 LDM_L_usrData4 2000;
BA_ "InvalidValue" SG_ 1353 LDM_L_usrData4 "null";
BA_ "GenSigTimeoutTime_ALL" SG_ 1353 LDM_L_usrData5 2000;
BA_ "InvalidValue" SG_ 1353 LDM_L_usrData5 "null";
BA_ "GenSigTimeoutTime_ALL" SG_ 1354 LDM_R_srcNodeID 2000;
BA_ "InvalidValue" SG_ 1354 LDM_R_srcNodeID "null";
BA_ "GenSigTimeoutTime_ALL" SG_ 1354 LDM_R_CtrlBitVector 2000;
BA_ "InvalidValue" SG_ 1354 LDM_R_CtrlBitVector "null";
BA_ "GenSigTimeoutTime_ALL" SG_ 1354 LDM_R_usrData0 2000;
BA_ "InvalidValue" SG_ 1354 LDM_R_usrData0 "null";
BA_ "GenSigTimeoutTime_ALL" SG_ 1354 LDM_R_usrData1 2000;
BA_ "InvalidValue" SG_ 1354 LDM_R_usrData1 "null";
BA_ "GenSigTimeoutTime_ALL" SG_ 1354 LDM_R_usrData2 2000;
BA_ "InvalidValue" SG_ 1354 LDM_R_usrData2 "null";
BA_ "GenSigTimeoutTime_ALL" SG_ 1354 LDM_R_usrData3 2000;
BA_ "InvalidValue" SG_ 1354 LDM_R_usrData3 "null";
BA_ "GenSigTimeoutTime_ALL" SG_ 1354 LDM_R_usrData4 2000;
BA_ "InvalidValue" SG_ 1354 LDM_R_usrData4 "null";
BA_ "GenSigTimeoutTime_ALL" SG_ 1354 LDM_R_usrData5 2000;
BA_ "InvalidValue" SG_ 1354 LDM_R_usrData5 "null";
BA_ "GenSigTimeoutTime_ALL" SG_ 1360 CCUR_srcNodeID 2000;
BA_ "InvalidValue" SG_ 1360 CCUR_srcNodeID "null";
BA_ "GenSigTimeoutTime_ALL" SG_ 1360 CCUR_CtrlBitVector 2000;
BA_ "InvalidValue" SG_ 1360 CCUR_CtrlBitVector "null";
BA_ "GenSigStartValue" SG_ 1360 CCUR_usrData0 255;
BA_ "GenSigTimeoutTime_ALL" SG_ 1360 CCUR_usrData0 2000;
BA_ "InvalidValue" SG_ 1360 CCUR_usrData0 "null";
BA_ "GenSigStartValue" SG_ 1360 CCUR_usrData1 255;
BA_ "GenSigTimeoutTime_ALL" SG_ 1360 CCUR_usrData1 2000;
BA_ "InvalidValue" SG_ 1360 CCUR_usrData1 "null";
BA_ "GenSigStartValue" SG_ 1360 CCUR_usrData2 255;
BA_ "GenSigTimeoutTime_ALL" SG_ 1360 CCUR_usrData2 2000;
BA_ "InvalidValue" SG_ 1360 CCUR_usrData2 "null";
BA_ "GenSigStartValue" SG_ 1360 CCUR_usrData3 255;
BA_ "GenSigTimeoutTime_ALL" SG_ 1360 CCUR_usrData3 2000;
BA_ "InvalidValue" SG_ 1360 CCUR_usrData3 "null";
BA_ "GenSigStartValue" SG_ 1360 CCUR_usrData4 255;
BA_ "GenSigTimeoutTime_ALL" SG_ 1360 CCUR_usrData4 2000;
BA_ "InvalidValue" SG_ 1360 CCUR_usrData4 "null";
BA_ "GenSigStartValue" SG_ 1360 CCUR_usrData5 255;
BA_ "GenSigTimeoutTime_ALL" SG_ 1360 CCUR_usrData5 2000;
BA_ "InvalidValue" SG_ 1360 CCUR_usrData5 "null";
BA_ "GenSigSendType" SG_ 1537 BCM_DiagRespData0 7;
BA_ "InvalidValue" SG_ 1537 BCM_DiagRespData0 "null";
BA_ "GenSigSendType" SG_ 1537 BCM_DiagRespData1 7;
BA_ "InvalidValue" SG_ 1537 BCM_DiagRespData1 "null";
BA_ "GenSigSendType" SG_ 1537 BCM_DiagRespData2 7;
BA_ "InvalidValue" SG_ 1537 BCM_DiagRespData2 "null";
BA_ "GenSigSendType" SG_ 1537 BCM_DiagRespData3 7;
BA_ "InvalidValue" SG_ 1537 BCM_DiagRespData3 "null";
BA_ "GenSigSendType" SG_ 1537 BCM_DiagRespData4 7;
BA_ "InvalidValue" SG_ 1537 BCM_DiagRespData4 "null";
BA_ "GenSigSendType" SG_ 1537 BCM_DiagRespData5 7;
BA_ "InvalidValue" SG_ 1537 BCM_DiagRespData5 "null";
BA_ "GenSigSendType" SG_ 1537 BCM_DiagRespData6 7;
BA_ "InvalidValue" SG_ 1537 BCM_DiagRespData6 "null";
BA_ "GenSigSendType" SG_ 1537 BCM_DiagRespData7 7;
BA_ "InvalidValue" SG_ 1537 BCM_DiagRespData7 "null";
BA_ "GenSigSendType" SG_ 1544 ACM_DiagRespData0 7;
BA_ "InvalidValue" SG_ 1544 ACM_DiagRespData0 "null";
BA_ "GenSigSendType" SG_ 1544 ACM_DiagRespData1 7;
BA_ "InvalidValue" SG_ 1544 ACM_DiagRespData1 "null";
BA_ "GenSigSendType" SG_ 1544 ACM_DiagRespData2 7;
BA_ "InvalidValue" SG_ 1544 ACM_DiagRespData2 "null";
BA_ "GenSigSendType" SG_ 1544 ACM_DiagRespData3 7;
BA_ "InvalidValue" SG_ 1544 ACM_DiagRespData3 "null";
BA_ "GenSigSendType" SG_ 1544 ACM_DiagRespData4 7;
BA_ "InvalidValue" SG_ 1544 ACM_DiagRespData4 "null";
BA_ "GenSigSendType" SG_ 1544 ACM_DiagRespData5 7;
BA_ "InvalidValue" SG_ 1544 ACM_DiagRespData5 "null";
BA_ "GenSigSendType" SG_ 1544 ACM_DiagRespData6 7;
BA_ "InvalidValue" SG_ 1544 ACM_DiagRespData6 "null";
BA_ "GenSigSendType" SG_ 1544 ACM_DiagRespData7 7;
BA_ "InvalidValue" SG_ 1544 ACM_DiagRespData7 "null";
BA_ "GenSigSendType" SG_ 1545 CCUF_DiagRespData0 7;
BA_ "InvalidValue" SG_ 1545 CCUF_DiagRespData0 "null";
BA_ "GenSigSendType" SG_ 1545 CCUF_DiagRespData1 7;
BA_ "InvalidValue" SG_ 1545 CCUF_DiagRespData1 "null";
BA_ "GenSigSendType" SG_ 1545 CCUF_DiagRespData2 7;
BA_ "InvalidValue" SG_ 1545 CCUF_DiagRespData2 "null";
BA_ "GenSigSendType" SG_ 1545 CCUF_DiagRespData3 7;
BA_ "InvalidValue" SG_ 1545 CCUF_DiagRespData3 "null";
BA_ "GenSigSendType" SG_ 1545 CCUF_DiagRespData4 7;
BA_ "InvalidValue" SG_ 1545 CCUF_DiagRespData4 "null";
BA_ "GenSigSendType" SG_ 1545 CCUF_DiagRespData5 7;
BA_ "InvalidValue" SG_ 1545 CCUF_DiagRespData5 "null";
BA_ "GenSigSendType" SG_ 1545 CCUF_DiagRespData6 7;
BA_ "InvalidValue" SG_ 1545 CCUF_DiagRespData6 "null";
BA_ "GenSigSendType" SG_ 1545 CCUF_DiagRespData7 7;
BA_ "InvalidValue" SG_ 1545 CCUF_DiagRespData7 "null";
BA_ "GenSigSendType" SG_ 1550 ETG_DiagRespData0 7;
BA_ "InvalidValue" SG_ 1550 ETG_DiagRespData0 "null";
BA_ "GenSigSendType" SG_ 1550 ETG_DiagRespData1 7;
BA_ "InvalidValue" SG_ 1550 ETG_DiagRespData1 "null";
BA_ "GenSigSendType" SG_ 1550 ETG_DiagRespData2 7;
BA_ "InvalidValue" SG_ 1550 ETG_DiagRespData2 "null";
BA_ "GenSigSendType" SG_ 1550 ETG_DiagRespData3 7;
BA_ "InvalidValue" SG_ 1550 ETG_DiagRespData3 "null";
BA_ "GenSigSendType" SG_ 1550 ETG_DiagRespData4 7;
BA_ "InvalidValue" SG_ 1550 ETG_DiagRespData4 "null";
BA_ "GenSigSendType" SG_ 1550 ETG_DiagRespData5 7;
BA_ "InvalidValue" SG_ 1550 ETG_DiagRespData5 "null";
BA_ "GenSigSendType" SG_ 1550 ETG_DiagRespData6 7;
BA_ "InvalidValue" SG_ 1550 ETG_DiagRespData6 "null";
BA_ "GenSigSendType" SG_ 1550 ETG_DiagRespData7 7;
BA_ "InvalidValue" SG_ 1550 ETG_DiagRespData7 "null";
BA_ "GenSigSendType" SG_ 1553 ASU_Gateway_DiagRespData0 7;
BA_ "InvalidValue" SG_ 1553 ASU_Gateway_DiagRespData0 "null";
BA_ "GenSigSendType" SG_ 1553 ASU_Gateway_DiagRespData1 7;
BA_ "InvalidValue" SG_ 1553 ASU_Gateway_DiagRespData1 "null";
BA_ "GenSigSendType" SG_ 1553 ASU_Gateway_DiagRespData2 7;
BA_ "InvalidValue" SG_ 1553 ASU_Gateway_DiagRespData2 "null";
BA_ "GenSigSendType" SG_ 1553 ASU_Gateway_DiagRespData3 7;
BA_ "InvalidValue" SG_ 1553 ASU_Gateway_DiagRespData3 "null";
BA_ "GenSigSendType" SG_ 1553 ASU_Gateway_DiagRespData4 7;
BA_ "InvalidValue" SG_ 1553 ASU_Gateway_DiagRespData4 "null";
BA_ "GenSigSendType" SG_ 1553 ASU_Gateway_DiagRespData5 7;
BA_ "InvalidValue" SG_ 1553 ASU_Gateway_DiagRespData5 "null";
BA_ "GenSigSendType" SG_ 1553 ASU_Gateway_DiagRespData6 7;
BA_ "InvalidValue" SG_ 1553 ASU_Gateway_DiagRespData6 "null";
BA_ "GenSigSendType" SG_ 1553 ASU_Gateway_DiagRespData7 7;
BA_ "InvalidValue" SG_ 1553 ASU_Gateway_DiagRespData7 "null";
BA_ "GenSigSendType" SG_ 1556 CCUR_DiagRespData0 7;
BA_ "InvalidValue" SG_ 1556 CCUR_DiagRespData0 "null";
BA_ "GenSigSendType" SG_ 1556 CCUR_DiagRespData1 7;
BA_ "InvalidValue" SG_ 1556 CCUR_DiagRespData1 "null";
BA_ "GenSigSendType" SG_ 1556 CCUR_DiagRespData2 7;
BA_ "InvalidValue" SG_ 1556 CCUR_DiagRespData2 "null";
BA_ "GenSigSendType" SG_ 1556 CCUR_DiagRespData3 7;
BA_ "InvalidValue" SG_ 1556 CCUR_DiagRespData3 "null";
BA_ "GenSigSendType" SG_ 1556 CCUR_DiagRespData4 7;
BA_ "InvalidValue" SG_ 1556 CCUR_DiagRespData4 "null";
BA_ "GenSigSendType" SG_ 1556 CCUR_DiagRespData5 7;
BA_ "InvalidValue" SG_ 1556 CCUR_DiagRespData5 "null";
BA_ "GenSigSendType" SG_ 1556 CCUR_DiagRespData6 7;
BA_ "InvalidValue" SG_ 1556 CCUR_DiagRespData6 "null";
BA_ "GenSigSendType" SG_ 1556 CCUR_DiagRespData7 7;
BA_ "InvalidValue" SG_ 1556 CCUR_DiagRespData7 "null";
BA_ "GenSigSendType" SG_ 1566 PSM_D_DiagRespData0 7;
BA_ "InvalidValue" SG_ 1566 PSM_D_DiagRespData0 "null";
BA_ "GenSigSendType" SG_ 1566 PSM_D_DiagRespData1 7;
BA_ "InvalidValue" SG_ 1566 PSM_D_DiagRespData1 "null";
BA_ "GenSigSendType" SG_ 1566 PSM_D_DiagRespData2 7;
BA_ "InvalidValue" SG_ 1566 PSM_D_DiagRespData2 "null";
BA_ "GenSigSendType" SG_ 1566 PSM_D_DiagRespData3 7;
BA_ "InvalidValue" SG_ 1566 PSM_D_DiagRespData3 "null";
BA_ "GenSigSendType" SG_ 1566 PSM_D_DiagRespData4 7;
BA_ "InvalidValue" SG_ 1566 PSM_D_DiagRespData4 "null";
BA_ "GenSigSendType" SG_ 1566 PSM_D_DiagRespData5 7;
BA_ "InvalidValue" SG_ 1566 PSM_D_DiagRespData5 "null";
BA_ "GenSigSendType" SG_ 1566 PSM_D_DiagRespData6 7;
BA_ "InvalidValue" SG_ 1566 PSM_D_DiagRespData6 "null";
BA_ "GenSigSendType" SG_ 1566 PSM_D_DiagRespData7 7;
BA_ "InvalidValue" SG_ 1566 PSM_D_DiagRespData7 "null";
BA_ "GenSigSendType" SG_ 1592 ASU_DiagRespData0 7;
BA_ "GenSigSendType" SG_ 1592 ASU_DiagRespData1 7;
BA_ "GenSigSendType" SG_ 1592 ASU_DiagRespData2 7;
BA_ "GenSigSendType" SG_ 1592 ASU_DiagRespData3 7;
BA_ "GenSigSendType" SG_ 1592 ASU_DiagRespData4 7;
BA_ "GenSigSendType" SG_ 1592 ASU_DiagRespData5 7;
BA_ "GenSigSendType" SG_ 1592 ASU_DiagRespData6 7;
BA_ "GenSigSendType" SG_ 1592 ASU_DiagRespData7 7;
BA_ "GenSigSendType" SG_ 1595 TRM_DiagRespData0 7;
BA_ "InvalidValue" SG_ 1595 TRM_DiagRespData0 "null";
BA_ "GenSigSendType" SG_ 1595 TRM_DiagRespData1 7;
BA_ "InvalidValue" SG_ 1595 TRM_DiagRespData1 "null";
BA_ "GenSigSendType" SG_ 1595 TRM_DiagRespData2 7;
BA_ "InvalidValue" SG_ 1595 TRM_DiagRespData2 "null";
BA_ "GenSigSendType" SG_ 1595 TRM_DiagRespData3 7;
BA_ "InvalidValue" SG_ 1595 TRM_DiagRespData3 "null";
BA_ "GenSigSendType" SG_ 1595 TRM_DiagRespData4 7;
BA_ "InvalidValue" SG_ 1595 TRM_DiagRespData4 "null";
BA_ "GenSigSendType" SG_ 1595 TRM_DiagRespData5 7;
BA_ "InvalidValue" SG_ 1595 TRM_DiagRespData5 "null";
BA_ "GenSigSendType" SG_ 1595 TRM_DiagRespData6 7;
BA_ "InvalidValue" SG_ 1595 TRM_DiagRespData6 "null";
BA_ "GenSigSendType" SG_ 1595 TRM_DiagRespData7 7;
BA_ "InvalidValue" SG_ 1595 TRM_DiagRespData7 "null";
BA_ "GenSigSendType" SG_ 1601 APM_DiagRespData0 7;
BA_ "InvalidValue" SG_ 1601 APM_DiagRespData0 "null";
BA_ "GenSigSendType" SG_ 1601 APM_DiagRespData1 7;
BA_ "InvalidValue" SG_ 1601 APM_DiagRespData1 "null";
BA_ "GenSigSendType" SG_ 1601 APM_DiagRespData2 7;
BA_ "InvalidValue" SG_ 1601 APM_DiagRespData2 "null";
BA_ "GenSigSendType" SG_ 1601 APM_DiagRespData3 7;
BA_ "InvalidValue" SG_ 1601 APM_DiagRespData3 "null";
BA_ "GenSigSendType" SG_ 1601 APM_DiagRespData4 7;
BA_ "InvalidValue" SG_ 1601 APM_DiagRespData4 "null";
BA_ "GenSigSendType" SG_ 1601 APM_DiagRespData5 7;
BA_ "InvalidValue" SG_ 1601 APM_DiagRespData5 "null";
BA_ "GenSigSendType" SG_ 1601 APM_DiagRespData6 7;
BA_ "InvalidValue" SG_ 1601 APM_DiagRespData6 "null";
BA_ "GenSigSendType" SG_ 1601 APM_DiagRespData7 7;
BA_ "InvalidValue" SG_ 1601 APM_DiagRespData7 "null";
BA_ "GenSigSendType" SG_ 1602 SHVU_F_DiagRespData0 7;
BA_ "InvalidValue" SG_ 1602 SHVU_F_DiagRespData0 "null";
BA_ "GenSigSendType" SG_ 1602 SHVU_F_DiagRespData1 7;
BA_ "InvalidValue" SG_ 1602 SHVU_F_DiagRespData1 "null";
BA_ "GenSigSendType" SG_ 1602 SHVU_F_DiagRespData2 7;
BA_ "InvalidValue" SG_ 1602 SHVU_F_DiagRespData2 "null";
BA_ "GenSigSendType" SG_ 1602 SHVU_F_DiagRespData3 7;
BA_ "InvalidValue" SG_ 1602 SHVU_F_DiagRespData3 "null";
BA_ "GenSigSendType" SG_ 1602 SHVU_F_DiagRespData4 7;
BA_ "InvalidValue" SG_ 1602 SHVU_F_DiagRespData4 "null";
BA_ "GenSigSendType" SG_ 1602 SHVU_F_DiagRespData5 7;
BA_ "InvalidValue" SG_ 1602 SHVU_F_DiagRespData5 "null";
BA_ "GenSigSendType" SG_ 1602 SHVU_F_DiagRespData6 7;
BA_ "InvalidValue" SG_ 1602 SHVU_F_DiagRespData6 "null";
BA_ "GenSigSendType" SG_ 1602 SHVU_F_DiagRespData7 7;
BA_ "InvalidValue" SG_ 1602 SHVU_F_DiagRespData7 "null";
BA_ "GenSigSendType" SG_ 1603 SHVU_R_DiagRespData0 7;
BA_ "InvalidValue" SG_ 1603 SHVU_R_DiagRespData0 "null";
BA_ "GenSigSendType" SG_ 1603 SHVU_R_DiagRespData1 7;
BA_ "InvalidValue" SG_ 1603 SHVU_R_DiagRespData1 "null";
BA_ "GenSigSendType" SG_ 1603 SHVU_R_DiagRespData2 7;
BA_ "InvalidValue" SG_ 1603 SHVU_R_DiagRespData2 "null";
BA_ "GenSigSendType" SG_ 1603 SHVU_R_DiagRespData3 7;
BA_ "InvalidValue" SG_ 1603 SHVU_R_DiagRespData3 "null";
BA_ "GenSigSendType" SG_ 1603 SHVU_R_DiagRespData4 7;
BA_ "InvalidValue" SG_ 1603 SHVU_R_DiagRespData4 "null";
BA_ "GenSigSendType" SG_ 1603 SHVU_R_DiagRespData5 7;
BA_ "InvalidValue" SG_ 1603 SHVU_R_DiagRespData5 "null";
BA_ "GenSigSendType" SG_ 1603 SHVU_R_DiagRespData6 7;
BA_ "InvalidValue" SG_ 1603 SHVU_R_DiagRespData6 "null";
BA_ "GenSigSendType" SG_ 1603 SHVU_R_DiagRespData7 7;
BA_ "InvalidValue" SG_ 1603 SHVU_R_DiagRespData7 "null";
BA_ "GenSigSendType" SG_ 1604 OCS_P_DiagRespData0 7;
BA_ "InvalidValue" SG_ 1604 OCS_P_DiagRespData0 "null";
BA_ "GenSigSendType" SG_ 1604 OCS_P_DiagRespData1 7;
BA_ "InvalidValue" SG_ 1604 OCS_P_DiagRespData1 "null";
BA_ "GenSigSendType" SG_ 1604 OCS_P_DiagRespData2 7;
BA_ "InvalidValue" SG_ 1604 OCS_P_DiagRespData2 "null";
BA_ "GenSigSendType" SG_ 1604 OCS_P_DiagRespData3 7;
BA_ "InvalidValue" SG_ 1604 OCS_P_DiagRespData3 "null";
BA_ "GenSigSendType" SG_ 1604 OCS_P_DiagRespData4 7;
BA_ "InvalidValue" SG_ 1604 OCS_P_DiagRespData4 "null";
BA_ "GenSigSendType" SG_ 1604 OCS_P_DiagRespData5 7;
BA_ "InvalidValue" SG_ 1604 OCS_P_DiagRespData5 "null";
BA_ "GenSigSendType" SG_ 1604 OCS_P_DiagRespData6 7;
BA_ "InvalidValue" SG_ 1604 OCS_P_DiagRespData6 "null";
BA_ "GenSigSendType" SG_ 1604 OCS_P_DiagRespData7 7;
BA_ "InvalidValue" SG_ 1604 OCS_P_DiagRespData7 "null";
BA_ "GenSigSendType" SG_ 1609 LDM_L_DiagRespData0 7;
BA_ "InvalidValue" SG_ 1609 LDM_L_DiagRespData0 "null";
BA_ "GenSigSendType" SG_ 1609 LDM_L_DiagRespData1 7;
BA_ "InvalidValue" SG_ 1609 LDM_L_DiagRespData1 "null";
BA_ "GenSigSendType" SG_ 1609 LDM_L_DiagRespData2 7;
BA_ "InvalidValue" SG_ 1609 LDM_L_DiagRespData2 "null";
BA_ "GenSigSendType" SG_ 1609 LDM_L_DiagRespData3 7;
BA_ "InvalidValue" SG_ 1609 LDM_L_DiagRespData3 "null";
BA_ "GenSigSendType" SG_ 1609 LDM_L_DiagRespData4 7;
BA_ "InvalidValue" SG_ 1609 LDM_L_DiagRespData4 "null";
BA_ "GenSigSendType" SG_ 1609 LDM_L_DiagRespData5 7;
BA_ "InvalidValue" SG_ 1609 LDM_L_DiagRespData5 "null";
BA_ "GenSigSendType" SG_ 1609 LDM_L_DiagRespData6 7;
BA_ "InvalidValue" SG_ 1609 LDM_L_DiagRespData6 "null";
BA_ "GenSigSendType" SG_ 1609 LDM_L_DiagRespData7 7;
BA_ "InvalidValue" SG_ 1609 LDM_L_DiagRespData7 "null";
BA_ "GenSigSendType" SG_ 1610 LDM_R_DiagRespData0 7;
BA_ "InvalidValue" SG_ 1610 LDM_R_DiagRespData0 "null";
BA_ "GenSigSendType" SG_ 1610 LDM_R_DiagRespData1 7;
BA_ "InvalidValue" SG_ 1610 LDM_R_DiagRespData1 "null";
BA_ "GenSigSendType" SG_ 1610 LDM_R_DiagRespData2 7;
BA_ "InvalidValue" SG_ 1610 LDM_R_DiagRespData2 "null";
BA_ "GenSigSendType" SG_ 1610 LDM_R_DiagRespData3 7;
BA_ "InvalidValue" SG_ 1610 LDM_R_DiagRespData3 "null";
BA_ "GenSigSendType" SG_ 1610 LDM_R_DiagRespData4 7;
BA_ "InvalidValue" SG_ 1610 LDM_R_DiagRespData4 "null";
BA_ "GenSigSendType" SG_ 1610 LDM_R_DiagRespData5 7;
BA_ "InvalidValue" SG_ 1610 LDM_R_DiagRespData5 "null";
BA_ "GenSigSendType" SG_ 1610 LDM_R_DiagRespData6 7;
BA_ "InvalidValue" SG_ 1610 LDM_R_DiagRespData6 "null";
BA_ "GenSigSendType" SG_ 1610 LDM_R_DiagRespData7 7;
BA_ "InvalidValue" SG_ 1610 LDM_R_DiagRespData7 "null";
BA_ "GenSigSendType" SG_ 1624 BAS_DiagRespData0 7;
BA_ "InvalidValue" SG_ 1624 BAS_DiagRespData0 "null";
BA_ "GenSigSendType" SG_ 1624 BAS_DiagRespData1 7;
BA_ "InvalidValue" SG_ 1624 BAS_DiagRespData1 "null";
BA_ "GenSigSendType" SG_ 1624 BAS_DiagRespData2 7;
BA_ "InvalidValue" SG_ 1624 BAS_DiagRespData2 "null";
BA_ "GenSigSendType" SG_ 1624 BAS_DiagRespData3 7;
BA_ "InvalidValue" SG_ 1624 BAS_DiagRespData3 "null";
BA_ "GenSigSendType" SG_ 1624 BAS_DiagRespData4 7;
BA_ "InvalidValue" SG_ 1624 BAS_DiagRespData4 "null";
BA_ "GenSigSendType" SG_ 1624 BAS_DiagRespData5 7;
BA_ "InvalidValue" SG_ 1624 BAS_DiagRespData5 "null";
BA_ "GenSigSendType" SG_ 1624 BAS_DiagRespData6 7;
BA_ "InvalidValue" SG_ 1624 BAS_DiagRespData6 "null";
BA_ "GenSigSendType" SG_ 1624 BAS_DiagRespData7 7;
BA_ "InvalidValue" SG_ 1624 BAS_DiagRespData7 "null";
BA_ "GenSigSendType" SG_ 1636 DCM_APM_DiagRespData0 7;
BA_ "InvalidValue" SG_ 1636 DCM_APM_DiagRespData0 "null";
BA_ "GenSigSendType" SG_ 1636 DCM_APM_DiagRespData1 7;
BA_ "InvalidValue" SG_ 1636 DCM_APM_DiagRespData1 "null";
BA_ "GenSigSendType" SG_ 1636 DCM_APM_DiagRespData2 7;
BA_ "InvalidValue" SG_ 1636 DCM_APM_DiagRespData2 "null";
BA_ "GenSigSendType" SG_ 1636 DCM_APM_DiagRespData3 7;
BA_ "InvalidValue" SG_ 1636 DCM_APM_DiagRespData3 "null";
BA_ "GenSigSendType" SG_ 1636 DCM_APM_DiagRespData4 7;
BA_ "InvalidValue" SG_ 1636 DCM_APM_DiagRespData4 "null";
BA_ "GenSigSendType" SG_ 1636 DCM_APM_DiagRespData5 7;
BA_ "InvalidValue" SG_ 1636 DCM_APM_DiagRespData5 "null";
BA_ "GenSigSendType" SG_ 1636 DCM_APM_DiagRespData6 7;
BA_ "InvalidValue" SG_ 1636 DCM_APM_DiagRespData6 "null";
BA_ "GenSigSendType" SG_ 1636 DCM_APM_DiagRespData7 7;
BA_ "InvalidValue" SG_ 1636 DCM_APM_DiagRespData7 "null";
BA_ "GenSigSendType" SG_ 1659 BCM_BPM_DiagRespData0 7;
BA_ "InvalidValue" SG_ 1659 BCM_BPM_DiagRespData0 "null";
BA_ "GenSigSendType" SG_ 1659 BCM_BPM_DiagRespData1 7;
BA_ "InvalidValue" SG_ 1659 BCM_BPM_DiagRespData1 "null";
BA_ "GenSigSendType" SG_ 1659 BCM_BPM_DiagRespData2 7;
BA_ "InvalidValue" SG_ 1659 BCM_BPM_DiagRespData2 "null";
BA_ "GenSigSendType" SG_ 1659 BCM_BPM_DiagRespData3 7;
BA_ "InvalidValue" SG_ 1659 BCM_BPM_DiagRespData3 "null";
BA_ "GenSigSendType" SG_ 1659 BCM_BPM_DiagRespData4 7;
BA_ "InvalidValue" SG_ 1659 BCM_BPM_DiagRespData4 "null";
BA_ "GenSigSendType" SG_ 1659 BCM_BPM_DiagRespData5 7;
BA_ "InvalidValue" SG_ 1659 BCM_BPM_DiagRespData5 "null";
BA_ "GenSigSendType" SG_ 1659 BCM_BPM_DiagRespData6 7;
BA_ "InvalidValue" SG_ 1659 BCM_BPM_DiagRespData6 "null";
BA_ "GenSigSendType" SG_ 1659 BCM_BPM_DiagRespData7 7;
BA_ "InvalidValue" SG_ 1659 BCM_BPM_DiagRespData7 "null";
BA_ "GenSigSendType" SG_ 1665 BCM_DiagReqData0 7;
BA_ "InvalidValue" SG_ 1665 BCM_DiagReqData0 "null";
BA_ "GenSigSendType" SG_ 1665 BCM_DiagReqData1 7;
BA_ "InvalidValue" SG_ 1665 BCM_DiagReqData1 "null";
BA_ "GenSigSendType" SG_ 1665 BCM_DiagReqData2 7;
BA_ "InvalidValue" SG_ 1665 BCM_DiagReqData2 "null";
BA_ "GenSigSendType" SG_ 1665 BCM_DiagReqData3 7;
BA_ "InvalidValue" SG_ 1665 BCM_DiagReqData3 "null";
BA_ "GenSigSendType" SG_ 1665 BCM_DiagReqData4 7;
BA_ "InvalidValue" SG_ 1665 BCM_DiagReqData4 "null";
BA_ "GenSigSendType" SG_ 1665 BCM_DiagReqData5 7;
BA_ "InvalidValue" SG_ 1665 BCM_DiagReqData5 "null";
BA_ "GenSigSendType" SG_ 1665 BCM_DiagReqData6 7;
BA_ "InvalidValue" SG_ 1665 BCM_DiagReqData6 "null";
BA_ "GenSigSendType" SG_ 1665 BCM_DiagReqData7 7;
BA_ "InvalidValue" SG_ 1665 BCM_DiagReqData7 "null";
BA_ "GenSigSendType" SG_ 1672 ACM_DiagReqData0 7;
BA_ "InvalidValue" SG_ 1672 ACM_DiagReqData0 "null";
BA_ "GenSigSendType" SG_ 1672 ACM_DiagReqData1 7;
BA_ "InvalidValue" SG_ 1672 ACM_DiagReqData1 "null";
BA_ "GenSigSendType" SG_ 1672 ACM_DiagReqData2 7;
BA_ "InvalidValue" SG_ 1672 ACM_DiagReqData2 "null";
BA_ "GenSigSendType" SG_ 1672 ACM_DiagReqData3 7;
BA_ "InvalidValue" SG_ 1672 ACM_DiagReqData3 "null";
BA_ "GenSigSendType" SG_ 1672 ACM_DiagReqData4 7;
BA_ "InvalidValue" SG_ 1672 ACM_DiagReqData4 "null";
BA_ "GenSigSendType" SG_ 1672 ACM_DiagReqData5 7;
BA_ "InvalidValue" SG_ 1672 ACM_DiagReqData5 "null";
BA_ "GenSigSendType" SG_ 1672 ACM_DiagReqData6 7;
BA_ "InvalidValue" SG_ 1672 ACM_DiagReqData6 "null";
BA_ "GenSigSendType" SG_ 1672 ACM_DiagReqData7 7;
BA_ "InvalidValue" SG_ 1672 ACM_DiagReqData7 "null";
BA_ "GenSigSendType" SG_ 1673 CCUF_DiagReqData0 7;
BA_ "InvalidValue" SG_ 1673 CCUF_DiagReqData0 "null";
BA_ "GenSigSendType" SG_ 1673 CCUF_DiagReqData1 7;
BA_ "InvalidValue" SG_ 1673 CCUF_DiagReqData1 "null";
BA_ "GenSigSendType" SG_ 1673 CCUF_DiagReqData2 7;
BA_ "InvalidValue" SG_ 1673 CCUF_DiagReqData2 "null";
BA_ "GenSigSendType" SG_ 1673 CCUF_DiagReqData3 7;
BA_ "InvalidValue" SG_ 1673 CCUF_DiagReqData3 "null";
BA_ "GenSigSendType" SG_ 1673 CCUF_DiagReqData4 7;
BA_ "InvalidValue" SG_ 1673 CCUF_DiagReqData4 "null";
BA_ "GenSigSendType" SG_ 1673 CCUF_DiagReqData5 7;
BA_ "InvalidValue" SG_ 1673 CCUF_DiagReqData5 "null";
BA_ "GenSigSendType" SG_ 1673 CCUF_DiagReqData6 7;
BA_ "InvalidValue" SG_ 1673 CCUF_DiagReqData6 "null";
BA_ "GenSigSendType" SG_ 1673 CCUF_DiagReqData7 7;
BA_ "InvalidValue" SG_ 1673 CCUF_DiagReqData7 "null";
BA_ "GenSigSendType" SG_ 1678 ETG_DiagReqData0 7;
BA_ "InvalidValue" SG_ 1678 ETG_DiagReqData0 "null";
BA_ "GenSigSendType" SG_ 1678 ETG_DiagReqData1 7;
BA_ "InvalidValue" SG_ 1678 ETG_DiagReqData1 "null";
BA_ "GenSigSendType" SG_ 1678 ETG_DiagReqData2 7;
BA_ "InvalidValue" SG_ 1678 ETG_DiagReqData2 "null";
BA_ "GenSigSendType" SG_ 1678 ETG_DiagReqData3 7;
BA_ "InvalidValue" SG_ 1678 ETG_DiagReqData3 "null";
BA_ "GenSigSendType" SG_ 1678 ETG_DiagReqData4 7;
BA_ "InvalidValue" SG_ 1678 ETG_DiagReqData4 "null";
BA_ "GenSigSendType" SG_ 1678 ETG_DiagReqData5 7;
BA_ "InvalidValue" SG_ 1678 ETG_DiagReqData5 "null";
BA_ "GenSigSendType" SG_ 1678 ETG_DiagReqData6 7;
BA_ "InvalidValue" SG_ 1678 ETG_DiagReqData6 "null";
BA_ "GenSigSendType" SG_ 1678 ETG_DiagReqData7 7;
BA_ "InvalidValue" SG_ 1678 ETG_DiagReqData7 "null";
BA_ "GenSigSendType" SG_ 1681 ASU_Gateway_DiagReqData0 7;
BA_ "InvalidValue" SG_ 1681 ASU_Gateway_DiagReqData0 "null";
BA_ "GenSigSendType" SG_ 1681 ASU_Gateway_DiagReqData1 7;
BA_ "InvalidValue" SG_ 1681 ASU_Gateway_DiagReqData1 "null";
BA_ "GenSigSendType" SG_ 1681 ASU_Gateway_DiagReqData2 7;
BA_ "InvalidValue" SG_ 1681 ASU_Gateway_DiagReqData2 "null";
BA_ "GenSigSendType" SG_ 1681 ASU_Gateway_DiagReqData3 7;
BA_ "InvalidValue" SG_ 1681 ASU_Gateway_DiagReqData3 "null";
BA_ "GenSigSendType" SG_ 1681 ASU_Gateway_DiagReqData4 7;
BA_ "InvalidValue" SG_ 1681 ASU_Gateway_DiagReqData4 "null";
BA_ "GenSigSendType" SG_ 1681 ASU_Gateway_DiagReqData5 7;
BA_ "InvalidValue" SG_ 1681 ASU_Gateway_DiagReqData5 "null";
BA_ "GenSigSendType" SG_ 1681 ASU_Gateway_DiagReqData6 7;
BA_ "InvalidValue" SG_ 1681 ASU_Gateway_DiagReqData6 "null";
BA_ "GenSigSendType" SG_ 1681 ASU_Gateway_DiagReqData7 7;
BA_ "InvalidValue" SG_ 1681 ASU_Gateway_DiagReqData7 "null";
BA_ "GenSigSendType" SG_ 1684 CCUR_DiagReqData0 7;
BA_ "InvalidValue" SG_ 1684 CCUR_DiagReqData0 "null";
BA_ "GenSigSendType" SG_ 1684 CCUR_DiagReqData1 7;
BA_ "InvalidValue" SG_ 1684 CCUR_DiagReqData1 "null";
BA_ "GenSigSendType" SG_ 1684 CCUR_DiagReqData2 7;
BA_ "InvalidValue" SG_ 1684 CCUR_DiagReqData2 "null";
BA_ "GenSigSendType" SG_ 1684 CCUR_DiagReqData3 7;
BA_ "InvalidValue" SG_ 1684 CCUR_DiagReqData3 "null";
BA_ "GenSigSendType" SG_ 1684 CCUR_DiagReqData4 7;
BA_ "InvalidValue" SG_ 1684 CCUR_DiagReqData4 "null";
BA_ "GenSigSendType" SG_ 1684 CCUR_DiagReqData5 7;
BA_ "InvalidValue" SG_ 1684 CCUR_DiagReqData5 "null";
BA_ "GenSigSendType" SG_ 1684 CCUR_DiagReqData6 7;
BA_ "InvalidValue" SG_ 1684 CCUR_DiagReqData6 "null";
BA_ "GenSigSendType" SG_ 1684 CCUR_DiagReqData7 7;
BA_ "InvalidValue" SG_ 1684 CCUR_DiagReqData7 "null";
BA_ "GenSigSendType" SG_ 1694 PSM_D_DiagReqData0 7;
BA_ "InvalidValue" SG_ 1694 PSM_D_DiagReqData0 "null";
BA_ "GenSigSendType" SG_ 1694 PSM_D_DiagReqData1 7;
BA_ "InvalidValue" SG_ 1694 PSM_D_DiagReqData1 "null";
BA_ "GenSigSendType" SG_ 1694 PSM_D_DiagReqData2 7;
BA_ "InvalidValue" SG_ 1694 PSM_D_DiagReqData2 "null";
BA_ "GenSigSendType" SG_ 1694 PSM_D_DiagReqData3 7;
BA_ "InvalidValue" SG_ 1694 PSM_D_DiagReqData3 "null";
BA_ "GenSigSendType" SG_ 1694 PSM_D_DiagReqData4 7;
BA_ "InvalidValue" SG_ 1694 PSM_D_DiagReqData4 "null";
BA_ "GenSigSendType" SG_ 1694 PSM_D_DiagReqData5 7;
BA_ "InvalidValue" SG_ 1694 PSM_D_DiagReqData5 "null";
BA_ "GenSigSendType" SG_ 1694 PSM_D_DiagReqData6 7;
BA_ "InvalidValue" SG_ 1694 PSM_D_DiagReqData6 "null";
BA_ "GenSigSendType" SG_ 1694 PSM_D_DiagReqData7 7;
BA_ "InvalidValue" SG_ 1694 PSM_D_DiagReqData7 "null";
BA_ "GenSigSendType" SG_ 1723 TRM_DiagReqData0 7;
BA_ "InvalidValue" SG_ 1723 TRM_DiagReqData0 "null";
BA_ "GenSigSendType" SG_ 1723 TRM_DiagReqData1 7;
BA_ "InvalidValue" SG_ 1723 TRM_DiagReqData1 "null";
BA_ "GenSigSendType" SG_ 1723 TRM_DiagReqData2 7;
BA_ "InvalidValue" SG_ 1723 TRM_DiagReqData2 "null";
BA_ "GenSigSendType" SG_ 1723 TRM_DiagReqData3 7;
BA_ "InvalidValue" SG_ 1723 TRM_DiagReqData3 "null";
BA_ "GenSigSendType" SG_ 1723 TRM_DiagReqData4 7;
BA_ "InvalidValue" SG_ 1723 TRM_DiagReqData4 "null";
BA_ "GenSigSendType" SG_ 1723 TRM_DiagReqData5 7;
BA_ "InvalidValue" SG_ 1723 TRM_DiagReqData5 "null";
BA_ "GenSigSendType" SG_ 1723 TRM_DiagReqData6 7;
BA_ "InvalidValue" SG_ 1723 TRM_DiagReqData6 "null";
BA_ "GenSigSendType" SG_ 1723 TRM_DiagReqData7 7;
BA_ "InvalidValue" SG_ 1723 TRM_DiagReqData7 "null";
BA_ "GenSigSendType" SG_ 1729 APM_DiagReqData0 7;
BA_ "InvalidValue" SG_ 1729 APM_DiagReqData0 "null";
BA_ "GenSigSendType" SG_ 1729 APM_DiagReqData1 7;
BA_ "InvalidValue" SG_ 1729 APM_DiagReqData1 "null";
BA_ "GenSigSendType" SG_ 1729 APM_DiagReqData2 7;
BA_ "InvalidValue" SG_ 1729 APM_DiagReqData2 "null";
BA_ "GenSigSendType" SG_ 1729 APM_DiagReqData3 7;
BA_ "InvalidValue" SG_ 1729 APM_DiagReqData3 "null";
BA_ "GenSigSendType" SG_ 1729 APM_DiagReqData4 7;
BA_ "InvalidValue" SG_ 1729 APM_DiagReqData4 "null";
BA_ "GenSigSendType" SG_ 1729 APM_DiagReqData5 7;
BA_ "InvalidValue" SG_ 1729 APM_DiagReqData5 "null";
BA_ "GenSigSendType" SG_ 1729 APM_DiagReqData6 7;
BA_ "InvalidValue" SG_ 1729 APM_DiagReqData6 "null";
BA_ "GenSigSendType" SG_ 1729 APM_DiagReqData7 7;
BA_ "InvalidValue" SG_ 1729 APM_DiagReqData7 "null";
BA_ "GenSigSendType" SG_ 1730 SHVU_F_DiagReqData0 7;
BA_ "InvalidValue" SG_ 1730 SHVU_F_DiagReqData0 "null";
BA_ "GenSigSendType" SG_ 1730 SHVU_F_DiagReqData1 7;
BA_ "InvalidValue" SG_ 1730 SHVU_F_DiagReqData1 "null";
BA_ "GenSigSendType" SG_ 1730 SHVU_F_DiagReqData2 7;
BA_ "InvalidValue" SG_ 1730 SHVU_F_DiagReqData2 "null";
BA_ "GenSigSendType" SG_ 1730 SHVU_F_DiagReqData3 7;
BA_ "InvalidValue" SG_ 1730 SHVU_F_DiagReqData3 "null";
BA_ "GenSigSendType" SG_ 1730 SHVU_F_DiagReqData4 7;
BA_ "InvalidValue" SG_ 1730 SHVU_F_DiagReqData4 "null";
BA_ "GenSigSendType" SG_ 1730 SHVU_F_DiagReqData5 7;
BA_ "InvalidValue" SG_ 1730 SHVU_F_DiagReqData5 "null";
BA_ "GenSigSendType" SG_ 1730 SHVU_F_DiagReqData6 7;
BA_ "InvalidValue" SG_ 1730 SHVU_F_DiagReqData6 "null";
BA_ "GenSigSendType" SG_ 1730 SHVU_F_DiagReqData7 7;
BA_ "InvalidValue" SG_ 1730 SHVU_F_DiagReqData7 "null";
BA_ "GenSigSendType" SG_ 1731 SHVU_R_DiagReqData0 7;
BA_ "InvalidValue" SG_ 1731 SHVU_R_DiagReqData0 "null";
BA_ "GenSigSendType" SG_ 1731 SHVU_R_DiagReqData1 7;
BA_ "InvalidValue" SG_ 1731 SHVU_R_DiagReqData1 "null";
BA_ "GenSigSendType" SG_ 1731 SHVU_R_DiagReqData2 7;
BA_ "InvalidValue" SG_ 1731 SHVU_R_DiagReqData2 "null";
BA_ "GenSigSendType" SG_ 1731 SHVU_R_DiagReqData3 7;
BA_ "InvalidValue" SG_ 1731 SHVU_R_DiagReqData3 "null";
BA_ "GenSigSendType" SG_ 1731 SHVU_R_DiagReqData4 7;
BA_ "InvalidValue" SG_ 1731 SHVU_R_DiagReqData4 "null";
BA_ "GenSigSendType" SG_ 1731 SHVU_R_DiagReqData5 7;
BA_ "InvalidValue" SG_ 1731 SHVU_R_DiagReqData5 "null";
BA_ "GenSigSendType" SG_ 1731 SHVU_R_DiagReqData6 7;
BA_ "InvalidValue" SG_ 1731 SHVU_R_DiagReqData6 "null";
BA_ "GenSigSendType" SG_ 1731 SHVU_R_DiagReqData7 7;
BA_ "InvalidValue" SG_ 1731 SHVU_R_DiagReqData7 "null";
BA_ "GenSigSendType" SG_ 1732 OCS_P_DiagReqData0 7;
BA_ "InvalidValue" SG_ 1732 OCS_P_DiagReqData0 "null";
BA_ "GenSigSendType" SG_ 1732 OCS_P_DiagReqData1 7;
BA_ "InvalidValue" SG_ 1732 OCS_P_DiagReqData1 "null";
BA_ "GenSigSendType" SG_ 1732 OCS_P_DiagReqData2 7;
BA_ "InvalidValue" SG_ 1732 OCS_P_DiagReqData2 "null";
BA_ "GenSigSendType" SG_ 1732 OCS_P_DiagReqData3 7;
BA_ "InvalidValue" SG_ 1732 OCS_P_DiagReqData3 "null";
BA_ "GenSigSendType" SG_ 1732 OCS_P_DiagReqData4 7;
BA_ "InvalidValue" SG_ 1732 OCS_P_DiagReqData4 "null";
BA_ "GenSigSendType" SG_ 1732 OCS_P_DiagReqData5 7;
BA_ "InvalidValue" SG_ 1732 OCS_P_DiagReqData5 "null";
BA_ "GenSigSendType" SG_ 1732 OCS_P_DiagReqData6 7;
BA_ "InvalidValue" SG_ 1732 OCS_P_DiagReqData6 "null";
BA_ "GenSigSendType" SG_ 1732 OCS_P_DiagReqData7 7;
BA_ "InvalidValue" SG_ 1732 OCS_P_DiagReqData7 "null";
BA_ "GenSigSendType" SG_ 1737 LDM_L_DiagReqData0 7;
BA_ "InvalidValue" SG_ 1737 LDM_L_DiagReqData0 "null";
BA_ "GenSigSendType" SG_ 1737 LDM_L_DiagReqData1 7;
BA_ "InvalidValue" SG_ 1737 LDM_L_DiagReqData1 "null";
BA_ "GenSigSendType" SG_ 1737 LDM_L_DiagReqData2 7;
BA_ "InvalidValue" SG_ 1737 LDM_L_DiagReqData2 "null";
BA_ "GenSigSendType" SG_ 1737 LDM_L_DiagReqData3 7;
BA_ "InvalidValue" SG_ 1737 LDM_L_DiagReqData3 "null";
BA_ "GenSigSendType" SG_ 1737 LDM_L_DiagReqData4 7;
BA_ "InvalidValue" SG_ 1737 LDM_L_DiagReqData4 "null";
BA_ "GenSigSendType" SG_ 1737 LDM_L_DiagReqData5 7;
BA_ "InvalidValue" SG_ 1737 LDM_L_DiagReqData5 "null";
BA_ "GenSigSendType" SG_ 1737 LDM_L_DiagReqData6 7;
BA_ "InvalidValue" SG_ 1737 LDM_L_DiagReqData6 "null";
BA_ "GenSigSendType" SG_ 1737 LDM_L_DiagReqData7 7;
BA_ "InvalidValue" SG_ 1737 LDM_L_DiagReqData7 "null";
BA_ "GenSigSendType" SG_ 1738 LDM_R_DiagReqData0 7;
BA_ "InvalidValue" SG_ 1738 LDM_R_DiagReqData0 "null";
BA_ "GenSigSendType" SG_ 1738 LDM_R_DiagReqData1 7;
BA_ "InvalidValue" SG_ 1738 LDM_R_DiagReqData1 "null";
BA_ "GenSigSendType" SG_ 1738 LDM_R_DiagReqData2 7;
BA_ "InvalidValue" SG_ 1738 LDM_R_DiagReqData2 "null";
BA_ "GenSigSendType" SG_ 1738 LDM_R_DiagReqData3 7;
BA_ "InvalidValue" SG_ 1738 LDM_R_DiagReqData3 "null";
BA_ "GenSigSendType" SG_ 1738 LDM_R_DiagReqData4 7;
BA_ "InvalidValue" SG_ 1738 LDM_R_DiagReqData4 "null";
BA_ "GenSigSendType" SG_ 1738 LDM_R_DiagReqData5 7;
BA_ "InvalidValue" SG_ 1738 LDM_R_DiagReqData5 "null";
BA_ "GenSigSendType" SG_ 1738 LDM_R_DiagReqData6 7;
BA_ "InvalidValue" SG_ 1738 LDM_R_DiagReqData6 "null";
BA_ "GenSigSendType" SG_ 1738 LDM_R_DiagReqData7 7;
BA_ "InvalidValue" SG_ 1738 LDM_R_DiagReqData7 "null";
BA_ "GenSigSendType" SG_ 1752 BAS_DiagReqData0 7;
BA_ "InvalidValue" SG_ 1752 BAS_DiagReqData0 "null";
BA_ "GenSigSendType" SG_ 1752 BAS_DiagReqData1 7;
BA_ "InvalidValue" SG_ 1752 BAS_DiagReqData1 "null";
BA_ "GenSigSendType" SG_ 1752 BAS_DiagReqData2 7;
BA_ "InvalidValue" SG_ 1752 BAS_DiagReqData2 "null";
BA_ "GenSigSendType" SG_ 1752 BAS_DiagReqData3 7;
BA_ "InvalidValue" SG_ 1752 BAS_DiagReqData3 "null";
BA_ "GenSigSendType" SG_ 1752 BAS_DiagReqData4 7;
BA_ "InvalidValue" SG_ 1752 BAS_DiagReqData4 "null";
BA_ "GenSigSendType" SG_ 1752 BAS_DiagReqData5 7;
BA_ "InvalidValue" SG_ 1752 BAS_DiagReqData5 "null";
BA_ "GenSigSendType" SG_ 1752 BAS_DiagReqData6 7;
BA_ "InvalidValue" SG_ 1752 BAS_DiagReqData6 "null";
BA_ "GenSigSendType" SG_ 1752 BAS_DiagReqData7 7;
BA_ "InvalidValue" SG_ 1752 BAS_DiagReqData7 "null";
BA_ "GenSigSendType" SG_ 1764 DCM_APM_DiagReqData0 7;
BA_ "InvalidValue" SG_ 1764 DCM_APM_DiagReqData0 "null";
BA_ "GenSigSendType" SG_ 1764 DCM_APM_DiagReqData1 7;
BA_ "InvalidValue" SG_ 1764 DCM_APM_DiagReqData1 "null";
BA_ "GenSigSendType" SG_ 1764 DCM_APM_DiagReqData2 7;
BA_ "InvalidValue" SG_ 1764 DCM_APM_DiagReqData2 "null";
BA_ "GenSigSendType" SG_ 1764 DCM_APM_DiagReqData3 7;
BA_ "InvalidValue" SG_ 1764 DCM_APM_DiagReqData3 "null";
BA_ "GenSigSendType" SG_ 1764 DCM_APM_DiagReqData4 7;
BA_ "InvalidValue" SG_ 1764 DCM_APM_DiagReqData4 "null";
BA_ "GenSigSendType" SG_ 1764 DCM_APM_DiagReqData5 7;
BA_ "InvalidValue" SG_ 1764 DCM_APM_DiagReqData5 "null";
BA_ "GenSigSendType" SG_ 1764 DCM_APM_DiagReqData6 7;
BA_ "InvalidValue" SG_ 1764 DCM_APM_DiagReqData6 "null";
BA_ "GenSigSendType" SG_ 1764 DCM_APM_DiagReqData7 7;
BA_ "InvalidValue" SG_ 1764 DCM_APM_DiagReqData7 "null";
BA_ "GenSigSendType" SG_ 1775 DiagReqAllCANData0 7;
BA_ "InvalidValue" SG_ 1775 DiagReqAllCANData0 "null";
BA_ "GenSigSendType" SG_ 1775 DiagReqAllCANData1 7;
BA_ "InvalidValue" SG_ 1775 DiagReqAllCANData1 "null";
BA_ "GenSigSendType" SG_ 1775 DiagReqAllCANData2 7;
BA_ "InvalidValue" SG_ 1775 DiagReqAllCANData2 "null";
BA_ "GenSigSendType" SG_ 1775 DiagReqAllCANData3 7;
BA_ "InvalidValue" SG_ 1775 DiagReqAllCANData3 "null";
BA_ "GenSigSendType" SG_ 1775 DiagReqAllCANData4 7;
BA_ "InvalidValue" SG_ 1775 DiagReqAllCANData4 "null";
BA_ "GenSigSendType" SG_ 1775 DiagReqAllCANData5 7;
BA_ "InvalidValue" SG_ 1775 DiagReqAllCANData5 "null";
BA_ "GenSigSendType" SG_ 1775 DiagReqAllCANData6 7;
BA_ "InvalidValue" SG_ 1775 DiagReqAllCANData6 "null";
BA_ "GenSigSendType" SG_ 1775 DiagReqAllCANData7 7;
BA_ "InvalidValue" SG_ 1775 DiagReqAllCANData7 "null";
BA_ "GenSigSendType" SG_ 1777 ASU_DiagReqData0 7;
BA_ "GenSigSendType" SG_ 1777 ASU_DiagReqData1 7;
BA_ "GenSigSendType" SG_ 1777 ASU_DiagReqData2 7;
BA_ "GenSigSendType" SG_ 1777 ASU_DiagReqData3 7;
BA_ "GenSigSendType" SG_ 1777 ASU_DiagReqData4 7;
BA_ "GenSigSendType" SG_ 1777 ASU_DiagReqData5 7;
BA_ "GenSigSendType" SG_ 1777 ASU_DiagReqData6 7;
BA_ "GenSigSendType" SG_ 1777 ASU_DiagReqData7 7;
BA_ "GenSigSendType" SG_ 1787 BCM_BPM_DiagReqData0 7;
BA_ "InvalidValue" SG_ 1787 BCM_BPM_DiagReqData0 "null";
BA_ "GenSigSendType" SG_ 1787 BCM_BPM_DiagReqData1 7;
BA_ "InvalidValue" SG_ 1787 BCM_BPM_DiagReqData1 "null";
BA_ "GenSigSendType" SG_ 1787 BCM_BPM_DiagReqData2 7;
BA_ "InvalidValue" SG_ 1787 BCM_BPM_DiagReqData2 "null";
BA_ "GenSigSendType" SG_ 1787 BCM_BPM_DiagReqData3 7;
BA_ "InvalidValue" SG_ 1787 BCM_BPM_DiagReqData3 "null";
BA_ "GenSigSendType" SG_ 1787 BCM_BPM_DiagReqData4 7;
BA_ "InvalidValue" SG_ 1787 BCM_BPM_DiagReqData4 "null";
BA_ "GenSigSendType" SG_ 1787 BCM_BPM_DiagReqData5 7;
BA_ "InvalidValue" SG_ 1787 BCM_BPM_DiagReqData5 "null";
BA_ "GenSigSendType" SG_ 1787 BCM_BPM_DiagReqData6 7;
BA_ "InvalidValue" SG_ 1787 BCM_BPM_DiagReqData6 "null";
BA_ "GenSigSendType" SG_ 1787 BCM_BPM_DiagReqData7 7;
BA_ "InvalidValue" SG_ 1787 BCM_BPM_DiagReqData7 "null";
BA_ "GenSigSendType" SG_ 1791 OBD_Func_DiagReqData0 7;
BA_ "InvalidValue" SG_ 1791 OBD_Func_DiagReqData0 "null";
BA_ "GenSigSendType" SG_ 1791 OBD_Func_DiagReqData1 7;
BA_ "InvalidValue" SG_ 1791 OBD_Func_DiagReqData1 "null";
BA_ "GenSigSendType" SG_ 1791 OBD_Func_DiagReqData2 7;
BA_ "InvalidValue" SG_ 1791 OBD_Func_DiagReqData2 "null";
BA_ "GenSigSendType" SG_ 1791 OBD_Func_DiagReqData3 7;
BA_ "InvalidValue" SG_ 1791 OBD_Func_DiagReqData3 "null";
BA_ "GenSigSendType" SG_ 1791 OBD_Func_DiagReqData4 7;
BA_ "InvalidValue" SG_ 1791 OBD_Func_DiagReqData4 "null";
BA_ "GenSigSendType" SG_ 1791 OBD_Func_DiagReqData5 7;
BA_ "InvalidValue" SG_ 1791 OBD_Func_DiagReqData5 "null";
BA_ "GenSigSendType" SG_ 1791 OBD_Func_DiagReqData6 7;
BA_ "InvalidValue" SG_ 1791 OBD_Func_DiagReqData6 "null";
BA_ "GenSigSendType" SG_ 1791 OBD_Func_DiagReqData7 7;
BA_ "InvalidValue" SG_ 1791 OBD_Func_DiagReqData7 "null";
BA_ "GenSigSendType" SG_ 1793 SEED_CAN_Req1 7;
BA_ "InvalidValue" SG_ 1793 SEED_CAN_Req1 "null";
BA_ "GenSigSendType" SG_ 1795 SEED_CAN_Req2 7;
BA_ "InvalidValue" SG_ 1795 SEED_CAN_Req2 "null";
BA_ "GenSigSendType" SG_ 1797 SEED_CAN_Req3 7;
BA_ "InvalidValue" SG_ 1797 SEED_CAN_Req3 "null";
BA_ "GenSigSendType" SG_ 1803 SEED_CAN_Req6 7;
BA_ "InvalidValue" SG_ 1803 SEED_CAN_Req6 "null";
BA_ "GenSigSendType" SG_ 1805 SEED_CAN_Req7 7;
BA_ "InvalidValue" SG_ 1805 SEED_CAN_Req7 "null";
BA_ "GenSigSendType" SG_ 1809 BCM_Data0 4;
BA_ "GenSigTimeoutTime_ALL" SG_ 1809 BCM_Data0 500;
BA_ "InvalidValue" SG_ 1809 BCM_Data0 "null";
BA_ "GenSigSendType" SG_ 1809 BCM_Data1 4;
BA_ "GenSigTimeoutTime_ALL" SG_ 1809 BCM_Data1 500;
BA_ "InvalidValue" SG_ 1809 BCM_Data1 "null";
BA_ "GenSigSendType" SG_ 1809 BCM_Data2 4;
BA_ "GenSigTimeoutTime_ALL" SG_ 1809 BCM_Data2 500;
BA_ "InvalidValue" SG_ 1809 BCM_Data2 "null";
BA_ "GenSigSendType" SG_ 1809 BCM_Data3 4;
BA_ "GenSigTimeoutTime_ALL" SG_ 1809 BCM_Data3 500;
BA_ "InvalidValue" SG_ 1809 BCM_Data3 "null";
BA_ "GenSigSendType" SG_ 1809 BCM_Data4 4;
BA_ "GenSigTimeoutTime_ALL" SG_ 1809 BCM_Data4 500;
BA_ "InvalidValue" SG_ 1809 BCM_Data4 "null";
BA_ "GenSigSendType" SG_ 1809 BCM_Data5 4;
BA_ "GenSigTimeoutTime_ALL" SG_ 1809 BCM_Data5 500;
BA_ "InvalidValue" SG_ 1809 BCM_Data5 "null";
BA_ "GenSigSendType" SG_ 1809 BCM_Data6 4;
BA_ "GenSigTimeoutTime_ALL" SG_ 1809 BCM_Data6 500;
BA_ "InvalidValue" SG_ 1809 BCM_Data6 "null";
BA_ "GenSigSendType" SG_ 1809 BCM_Data7 4;
BA_ "GenSigTimeoutTime_ALL" SG_ 1809 BCM_Data7 500;
BA_ "InvalidValue" SG_ 1809 BCM_Data7 "null";
BA_ "GenSigSendType" SG_ 1810 BCM_BPM_Data0 4;
BA_ "GenSigTimeoutTime_ALL" SG_ 1810 BCM_BPM_Data0 500;
BA_ "InvalidValue" SG_ 1810 BCM_BPM_Data0 "null";
BA_ "GenSigSendType" SG_ 1810 BCM_BPM_Data1 4;
BA_ "GenSigTimeoutTime_ALL" SG_ 1810 BCM_BPM_Data1 500;
BA_ "InvalidValue" SG_ 1810 BCM_BPM_Data1 "null";
BA_ "GenSigSendType" SG_ 1810 BCM_BPM_Data2 4;
BA_ "GenSigTimeoutTime_ALL" SG_ 1810 BCM_BPM_Data2 500;
BA_ "InvalidValue" SG_ 1810 BCM_BPM_Data2 "null";
BA_ "GenSigSendType" SG_ 1810 BCM_BPM_Data3 4;
BA_ "GenSigTimeoutTime_ALL" SG_ 1810 BCM_BPM_Data3 500;
BA_ "InvalidValue" SG_ 1810 BCM_BPM_Data3 "null";
BA_ "GenSigSendType" SG_ 1810 BCM_BPM_Data4 4;
BA_ "GenSigTimeoutTime_ALL" SG_ 1810 BCM_BPM_Data4 500;
BA_ "InvalidValue" SG_ 1810 BCM_BPM_Data4 "null";
BA_ "GenSigSendType" SG_ 1810 BCM_BPM_Data5 4;
BA_ "GenSigTimeoutTime_ALL" SG_ 1810 BCM_BPM_Data5 500;
BA_ "InvalidValue" SG_ 1810 BCM_BPM_Data5 "null";
BA_ "GenSigSendType" SG_ 1810 BCM_BPM_Data6 4;
BA_ "GenSigTimeoutTime_ALL" SG_ 1810 BCM_BPM_Data6 500;
BA_ "InvalidValue" SG_ 1810 BCM_BPM_Data6 "null";
BA_ "GenSigSendType" SG_ 1810 BCM_BPM_Data7 4;
BA_ "GenSigTimeoutTime_ALL" SG_ 1810 BCM_BPM_Data7 500;
BA_ "InvalidValue" SG_ 1810 BCM_BPM_Data7 "null";
BA_ "GenSigStartValue" SG_ 1814 CCU_DuctSensor1 60;
BA_ "GenSigTimeoutTime_ALL" SG_ 1814 CCU_DuctSensor1 1000;
BA_ "InvalidValue" SG_ 1814 CCU_DuctSensor1 "0xFF";
BA_ "GenSigStartValue" SG_ 1814 CCU_DuctSensor2 60;
BA_ "GenSigTimeoutTime_ALL" SG_ 1814 CCU_DuctSensor2 1000;
BA_ "InvalidValue" SG_ 1814 CCU_DuctSensor2 "0xFF";
BA_ "GenSigStartValue" SG_ 1814 CCU_DuctSensor3 60;
BA_ "GenSigTimeoutTime_ALL" SG_ 1814 CCU_DuctSensor3 1000;
BA_ "InvalidValue" SG_ 1814 CCU_DuctSensor3 "0xFF";
BA_ "GenSigStartValue" SG_ 1814 CCU_DuctSensor4 60;
BA_ "GenSigTimeoutTime_ALL" SG_ 1814 CCU_DuctSensor4 1000;
BA_ "InvalidValue" SG_ 1814 CCU_DuctSensor4 "0xFF";
BA_ "GenSigTimeoutTime_ALL" SG_ 1814 CCU_AQS_PWM_IN 1000;
BA_ "InvalidValue" SG_ 1814 CCU_AQS_PWM_IN "0xFF";
BA_ "GenSigTimeoutTime_ALL" SG_ 1814 CCU_AQSCtrlFrequency 1000;
BA_ "InvalidValue" SG_ 1814 CCU_AQSCtrlFrequency "0x3FF";
BA_ "GenSigTimeoutTime_ALL" SG_ 1814 CCU_BattVoltSts 1000;
BA_ "InvalidValue" SG_ 1814 CCU_BattVoltSts "0xF";
BA_ "GenSigTimeoutTime_ALL" SG_ 1814 CCU_BattVoltVal 1000;
BA_ "InvalidValue" SG_ 1814 CCU_BattVoltVal "0xFF";
BA_ "GenSigSendType" SG_ 1843 SEED_CAN_Req18 7;
BA_ "InvalidValue" SG_ 1843 SEED_CAN_Req18 "null";
BA_ "GenSigSendType" SG_ 1847 SEED_CAN_Req21 7;
BA_ "InvalidValue" SG_ 1847 SEED_CAN_Req21 "null";
BA_ "GenSigTimeoutTime_ALL" SG_ 1857 CCU_ERL_FL 1000;
BA_ "InvalidValue" SG_ 1857 CCU_ERL_FL "null";
BA_ "GenSigTimeoutTime_ALL" SG_ 1857 CCU_ERL_FR 1000;
BA_ "InvalidValue" SG_ 1857 CCU_ERL_FR "null";
BA_ "GenSigStartValue" SG_ 1857 CCU_EvapTempSet 50;
BA_ "GenSigTimeoutTime_ALL" SG_ 1857 CCU_EvapTempSet 1000;
BA_ "InvalidValue" SG_ 1857 CCU_EvapTempSet "null";
BA_ "GenSigTimeoutTime_ALL" SG_ 1857 CCU_BlowerFltPWM 1000;
BA_ "InvalidValue" SG_ 1857 CCU_BlowerFltPWM "null";
BA_ "GenSigTimeoutTime_ALL" SG_ 1857 CCU_AirDistribFlapPos 1000;
BA_ "InvalidValue" SG_ 1857 CCU_AirDistribFlapPos "null";
BA_ "GenSigTimeoutTime_ALL" SG_ 1857 CCU_RecircFlapPos 1000;
BA_ "InvalidValue" SG_ 1857 CCU_RecircFlapPos "null";
BA_ "GenSigTimeoutTime_ALL" SG_ 1857 CCU_AirDistribFeedback 1000;
BA_ "InvalidValue" SG_ 1857 CCU_AirDistribFeedback "null";
BA_ "GenSigTimeoutTime_ALL" SG_ 1857 CCU_RecircFlapFeedback 1000;
BA_ "InvalidValue" SG_ 1857 CCU_RecircFlapFeedback "null";
BA_ "GenSigTimeoutTime_ALL" SG_ 1858 CCU_TempFlapPos_FL 1000;
BA_ "InvalidValue" SG_ 1858 CCU_TempFlapPos_FL "null";
BA_ "GenSigTimeoutTime_ALL" SG_ 1858 CCU_TempFlapPos_FR 1000;
BA_ "InvalidValue" SG_ 1858 CCU_TempFlapPos_FR "null";
BA_ "GenSigStartValue" SG_ 1858 CCU_DuctTargetTemp_FL 80;
BA_ "GenSigTimeoutTime_ALL" SG_ 1858 CCU_DuctTargetTemp_FL 1000;
BA_ "InvalidValue" SG_ 1858 CCU_DuctTargetTemp_FL "null";
BA_ "GenSigStartValue" SG_ 1858 CCU_DuctTargetTemp_FR 80;
BA_ "GenSigTimeoutTime_ALL" SG_ 1858 CCU_DuctTargetTemp_FR 1000;
BA_ "InvalidValue" SG_ 1858 CCU_DuctTargetTemp_FR "null";
BA_ "GenSigTimeoutTime_ALL" SG_ 1858 CCU_TempFLFeedback 1000;
BA_ "InvalidValue" SG_ 1858 CCU_TempFLFeedback "null";
BA_ "GenSigTimeoutTime_ALL" SG_ 1858 CCU_TempFRFeedback 1000;
BA_ "InvalidValue" SG_ 1858 CCU_TempFRFeedback "null";
BA_ "GenSigTimeoutTime_ALL" SG_ 1858 CCU_PTCSetTemp 1000;
BA_ "InvalidValue" SG_ 1858 CCU_PTCSetTemp "null";
BA_ "GenSigTimeoutTime_ALL" SG_ 2046 TST_TxMsgConfirm_CcuHeatCoolReq 1000;
BA_ "GenSigTimeoutTime_ALL" SG_ 2046 TST_RxMsgConfirm_BCM_CLAMP_STAT 1000;
BA_ "GenSigTimeoutTime_ALL" SG_ 2046 CCU_TST_TxMsgConfirm_CcuWarnMsg 1000;
BA_ "GenSigTimeoutTime_ALL" SG_ 2046 CCU_TST_TxMsgConfirm_CcuNm 1000;
BA_ "GenSigTimeoutTime_ALL" SG_ 2046 CCU_TST_StateMngr_States 1000;
BA_ "GenSigTimeoutTime_ALL" SG_ 2046 CCU_TST_Reserve_6 1000;
BA_ "GenSigTimeoutTime_ALL" SG_ 2046 CCU_TST_Reserve_5 1000;
BA_ "GenSigTimeoutTime_ALL" SG_ 2046 CCU_TST_Reserve_4 1000;
BA_ "GenSigTimeoutTime_ALL" SG_ 2046 CCU_TST_Reserve_3 1000;
BA_ "GenSigTimeoutTime_ALL" SG_ 2046 CCU_TST_Reserve_2 1000;
BA_ "GenSigTimeoutTime_ALL" SG_ 2046 CCU_TST_Reserve_1 1000;
BA_ "GenSigTimeoutTime_ALL" SG_ 2046 CCU_TST_Reserve_0 1000;
BA_ "GenSigTimeoutTime_ALL" SG_ 2046 CCU_TST_NetworkMngr_States 1000;
BA_ "GenSigTimeoutTime_ALL" SG_ 2046 CCU_TST_BCM_CRC 1000;
BA_ "GenSigSendType" SG_ 1938 CCU_Resp_CCP 7;
BA_ "InvalidValue" SG_ 1938 CCU_Resp_CCP "null";
BA_ "GenSigTimeoutTime_ALL" SG_ 1939 LDML_FltReactn 500;
BA_ "InvalidValue" SG_ 1939 LDML_FltReactn "null";
BA_ "GenSigStartValue" SG_ 1939 LDML_RiAdjstAgOutp 1000;
BA_ "GenSigTimeoutTime_ALL" SG_ 1939 LDML_RiAdjstAgOutp 500;
BA_ "InvalidValue" SG_ 1939 LDML_RiAdjstAgOutp "null";
BA_ "GenSigTimeoutTime_ALL" SG_ 1940 LDMR_FltReactn 500;
BA_ "InvalidValue" SG_ 1940 LDMR_FltReactn "null";
BA_ "GenSigStartValue" SG_ 1940 LDMR_ModuleCurAg 1000;
BA_ "GenSigTimeoutTime_ALL" SG_ 1940 LDMR_ModuleCurAg 500;
BA_ "InvalidValue" SG_ 1940 LDMR_ModuleCurAg "null";
BA_ "GenSigSendType" SG_ 1976 CCU_Req_EOL 7;
BA_ "InvalidValue" SG_ 1976 CCU_Req_EOL "null";
BA_ "GenSigSendType" SG_ 1977 CCU_Resp_EOL 7;
BA_ "InvalidValue" SG_ 1977 CCU_Resp_EOL "null";
BA_ "GenSigSendType" SG_ 1978 CCUR_Req_EOL 7;
BA_ "InvalidValue" SG_ 1978 CCUR_Req_EOL "null";
BA_ "GenSigSendType" SG_ 1980 CCUR_Resp_EOL_ 7;
BA_ "InvalidValue" SG_ 1980 CCUR_Resp_EOL_ "null";
BA_ "GenSigSendType" SG_ 1985 CCU_Req_CCP 7;
BA_ "InvalidValue" SG_ 1985 CCU_Req_CCP "null";
BA_ "GenSigSendType" SG_ 2015 Diag_Request_ECU_Data0 7;
BA_ "InvalidValue" SG_ 2015 Diag_Request_ECU_Data0 "null";
BA_ "GenSigSendType" SG_ 2015 Diag_Request_ECU_Data1 7;
BA_ "InvalidValue" SG_ 2015 Diag_Request_ECU_Data1 "null";
BA_ "GenSigSendType" SG_ 2015 Diag_Request_ECU_Data2 7;
BA_ "InvalidValue" SG_ 2015 Diag_Request_ECU_Data2 "null";
BA_ "GenSigSendType" SG_ 2015 Diag_Request_ECU_Data3 7;
BA_ "InvalidValue" SG_ 2015 Diag_Request_ECU_Data3 "null";
BA_ "GenSigSendType" SG_ 2015 Diag_Request_ECU_Data4 7;
BA_ "InvalidValue" SG_ 2015 Diag_Request_ECU_Data4 "null";
BA_ "GenSigSendType" SG_ 2015 Diag_Request_ECU_Data5 7;
BA_ "InvalidValue" SG_ 2015 Diag_Request_ECU_Data5 "null";
BA_ "GenSigSendType" SG_ 2015 Diag_Request_ECU_Data6 7;
BA_ "InvalidValue" SG_ 2015 Diag_Request_ECU_Data6 "null";
BA_ "GenSigSendType" SG_ 2015 Diag_Request_ECU_Data7 7;
BA_ "InvalidValue" SG_ 2015 Diag_Request_ECU_Data7 "null";
BA_ "GenSigSendType" SG_ 2033 Request_Airbag_Deployment 7;
BA_ "InvalidValue" SG_ 2033 Request_Airbag_Deployment "null";
BA_ "GenSigSendType" SG_ 2041 Response_Airbag_Deployment 7;
BA_ "InvalidValue" SG_ 2041 Response_Airbag_Deployment "null";
VAL_ 1112 AmbLightColorZoneReq 0 "no zone" 1 " ALM Zone 1 = CSUV_ALM Cockpit_DSUV_COCKPIT_DRIVER " 2 " ALM Zone 2 = CSUV_ALM Right Front Door_DSUV_COCKPIT_PASSANGER" 3 "ALM Zone 3 = CSUV_ALM Left Front Door_DSUV_FRT_DOOR_LH" 4 "ALM Zone 4 = CSUV_ALM Right Rear Door_DSUV_FRT_DOOR_RH" 5 "ALM Zone 5 = CSUV_ALM Left Rear Door_DSUV_RR_DOOR_RH" 6 "ALM Zone 6 = DSUV_RR_DOOR_RH" 7 "ALM Zone 7 = DSUV_CENTER_CONSOLE_DRIVER" 8 "ALM Zone 8 = DSUV_CENTER_CONSOLE_PASSANGER" 9 "ALM Zone 9 = DSUV_CENTER_CONSOLE_RR_DRIVER" 10 "ALM Zone 10 = DSUV_CENTER_CONSOLE_RR_PASSANGER" ;
VAL_ 1113 AmbLightIntensityTimingTypeReq 0 "None" 1 "Blinking" 2 "Wave" 3 "Morse" 4 "Fading" ;
VAL_ 1115 HOD_steering_wheel_type 0 "LEATHER" 1 "Reserved" 2 "Reserved" 3 "Reserved" 15 "Invalid value" ;
VAL_ 1115 HOD_vehicle_type 0 "VFe35" 1 "VFe36" 2 "Reserved" 3 "Reserved" 4 "Reserved" 255 "invalid value" ;
VAL_ 1115 ADAS_HOD_state_requesting 0 "Sleep_mode_requesting" 1 "Reserved" 2 "Normal_mode_requesting" 3 "Invalid value" ;
VAL_ 1124 LDML_LampAssemblySts 0 "Normal" 1 "Fault" 2 "Reserved" 3 "Signal Invalid" ;
VAL_ 1124 LDML_PosLmpSts 0 "OFF" 1 "ON" 2 "Fault" 3 "Signal Invalid" ;
VAL_ 1124 LDML_ControllerSts 0 "Normal" 1 "Fault" 2 "Reserved" 3 "Signal Invalid" ;
VAL_ 1124 LDML_TurnIndicatorSts 0 "OFF" 1 "ON" 2 "Fault" 3 "Signal Invalid" ;
VAL_ 1124 LDML_AuxLBSts 0 "OFF" 1 "ON" 2 "Fault" 3 "Signal Invalid" ;
VAL_ 1124 LDML_LowBeamSts 0 "OFF" 1 "ON" 2 "Fault" 3 "Signal Invalid " ;
VAL_ 1124 LDML_HighBeamSts 0 "OFF" 1 "ON" 2 "Fault" 3 "Signal Invalid" ;
VAL_ 1124 LDML_DayRunningLampSts 0 "OFF" 1 "ON" 2 "Fault" 3 "Signal Invalid" ;
VAL_ 1124 LDML_DayTimeRunningLightFbSts 0 "OFF" 1 "ON" 2 "Reserved" 3 "Signal Invalid" ;
VAL_ 1124 LDML_AutoLvlFbSts 0 "OFF" 1 "ON" 2 "Reserved" 3 "Signal Invalid" ;
VAL_ 1124 LDML_AdptvDrvBeamFbSts 0 "OFF" 1 "ON" 2 "Reserved" 3 "Signal Invalid" ;
VAL_ 1124 LDML_AuxHBSts 0 "OFF" 1 "ON" 2 "Fault" 3 "Signal Invalid" ;
VAL_ 1124 LDML_FollowMeHomeFbSts 0 "OFF" 1 "30 secs" 2 "60 secs" 3 "90 secs" 4 "120 secs" 5 "Signal Invalid" ;
VAL_ 1124 LDML_ExteriorLightFbSts 0 "OFF" 1 "Parking" 2 "Low Beam" 3 "AUTO" 4 "Signal Invalid" ;
VAL_ 1124 LDML_AHB_ICON_Feed 0 "off " 1 "gray icon" 2 "green icon" 3 "SNA" ;
VAL_ 1125 LDMR_LampAssemblySts 0 "Normal" 1 "Fault" 2 "Reserved" 3 "Signal Invalid" ;
VAL_ 1125 LDMR_PosLmpSts 0 "OFF" 1 "ON" 2 "Fault" 3 "Signal Invalid" ;
VAL_ 1125 LDMR_ControllerSts 0 "Normal" 1 "Fault" 2 "Reserved" 3 "Signal Invalid" ;
VAL_ 1125 LDMR_TurnIndicatorSts 0 "OFF" 1 "ON" 2 "Fault" 3 "Signal Invalid" ;
VAL_ 1125 LDMR_AuxLBSts 0 "OFF" 1 "ON" 2 "Fault" 3 "Signal Invalid" ;
VAL_ 1125 LDMR_LowBeamSts 0 "OFF" 1 "ON" 2 "Fault" 3 "Signal Invalid " ;
VAL_ 1125 LDMR_HighBeamSts 0 "OFF" 1 "ON" 2 "Fault" 3 "Signal Invalid" ;
VAL_ 1125 LDMR_DayRunningLampSts 0 "OFF" 1 "ON" 2 "Fault" 3 "Signal Invalid" ;
VAL_ 1125 LDMR_DayTimeRunningLightFbSts 0 "OFF" 1 "ON" 2 "Reserved" 3 "Signal Invalid" ;
VAL_ 1125 LDMR_AutoLvlFbSts 0 "OFF" 1 "ON" 2 "Reserved" 3 "Signal Invalid" ;
VAL_ 1125 LDMR_AdptvDrvBeamFbSts 0 "OFF" 1 "ON" 2 "Reserved" 3 "Signal Invalid" ;
VAL_ 1125 LDMR_AuxHBSts 0 "OFF" 1 "ON" 2 "Fault" 3 "Signal Invalid" ;
VAL_ 1125 LDMR_FollowMeHomeFbSts 0 "OFF" 1 "30 secs" 2 "60 secs" 3 "90 secs" 4 "120 secs" 5 "Signal Invalid" ;
VAL_ 1125 LDMR_ExteriorLightFbSts 0 "OFF" 1 "Parking" 2 "Low Beam" 3 "AUTO" 4 "Signal Invalid" ;
VAL_ 1125 LDMR_AHB_ICON_Feed 0 "off " 1 "gray icon" 2 "green icon" 3 "SNA" ;
VAL_ 1152 PSM_DrvSeatMissalignment 0 "Off" 1 "Driver Power seat malfunction, Seat Initialization required" ;
VAL_ 1152 PSM_PasSeatMisalignment 0 "Off" 1 "Passenger Power seat malfunction, Seat Initialization required" ;
VAL_ 1153 BCM_NoValidKey_1 0 "None" 1 "Alert";
VAL_ 1153 BCM_SSB_defect 0 "None" 1 "Alert";
VAL_ 1153 BCM_WrongGearPosToStart 0 "None" 1 "Alert";
VAL_ 1153 BCM_NoValidKey_2 0 "None" 1 "Alert";
VAL_ 1153 BCM_PressBrakeToStart 0 "None" 1 "Alert";
VAL_ 1153 BCM_TurnOffPosLightRemindr 0 "None" 1 "Alert";
VAL_ 1153 BCM_KeyFob_LowBattery 0 "None" 1 "Alert";
VAL_ 1153 BCM_StopLightDefect 0 "None" 1 "Alert";
VAL_ 1153 BCM_LowBeamDefect 0 "None" 1 "Alert";
VAL_ 1153 BCM_HighBeamDefect 0 "None" 1 "Alert";
VAL_ 1153 BCM_PositionLightDefect 0 "None" 1 "Alert";
VAL_ 1153 BCM_CHMLS_Defect 0 "None" 1 "Alert";
VAL_ 1153 BCM_LicencePlateLight_Defect 0 "None" 1 "Alert";
VAL_ 1153 BCM_FrontFog_Defect 0 "None" 1 "Alert";
VAL_ 1153 BCM_RearFog_Defect 0 "None" 1 "Alert";
VAL_ 1153 BCM_ReverseLightDefect 0 "None" 1 "Alert";
VAL_ 1153 BCM_RLS_Malfunction 0 "None" 1 "Alert";
VAL_ 1153 BCM_12VBattery_LowLevel 0 "None" 1 "Alert";
VAL_ 1153 BCM_ForgetKeyFOBInCar 0 "None" 1 "Alert";
VAL_ 1153 BCM_12VBattery_Discharging 0 "None" 1 "Alert";
VAL_ 1153 BCM_TurnIndicatorDefect 0 "None" 1 "Alert";
VAL_ 1153 BCM_dTPMS_Malfunc 0 "None" 1 "Alert";
VAL_ 1153 BCM_dTPMS_Malfunc_LostSensor 0 "None" 1 "Alert";
VAL_ 1153 BCM_dTPMS_LowPressure 0 "None" 1 "Alert";
VAL_ 1153 BCM_dTPMS_RapidLeak 0 "None" 1 "Alert";
VAL_ 1153 BCM_dTPMS_HighTemperature 0 "None" 1 "Alert";
VAL_ 1153 BCM_dTPMS_HighPressure 0 "None" 1 "Alert";
VAL_ 1153 BCM_dTPMS_LowBattery 0 "None" 1 "Alert";
VAL_ 1153 BCM_Keyfob_Leftcar 0 "None" 1 "Alert";
VAL_ 1153 BCM_IDB_Brakelight_Malfunction 0 "None" 1 "Alert";
VAL_ 1153 BCM_VCU_Brakelight_Malfunction 0 "None" 1 "Alert";
VAL_ 1153 BCM_ADAS_Turnlight_Malfunction 0 "None" 1 "Alert";
VAL_ 1153 BCM_ADAS_Highbeam_Malfunction 0 "None" 1 "Alert";
VAL_ 1153 BCM_ADAS_LowBeam_Malfunction 0 "None" 1 "Alert";
VAL_ 1153 BCM_MHU_Malfunction 0 "None" 1 "Alert";
VAL_ 1153 BCM_BCM_Malfunction 0 "None" 1 "Alert";
VAL_ 1153 BCM_SCM_Malfunction 0 "None" 1 "Alert";
VAL_ 1153 BCM_CrashSignalDefect 0 "None" 1 "Alert";
VAL_ 1153 BCM_FrontWiperDefect 0 "None" 1 "Alert";
VAL_ 1153 BCM_Rear_RightDoorLockDefect 0 "None" 1 "Alert";
VAL_ 1153 BCM_RearLeftDoorLockDefect 0 "None" 1 "Alert";
VAL_ 1153 BCM_Front_RightDoorLockDefect 0 "None" 1 "Alert";
VAL_ 1153 BCM_FrontLeftDoorLockDefect 0 "None" 1 "Alert";
VAL_ 1153 BCM_LDML_Malfunction 0 "None" 1 "Alert";
VAL_ 1153 BCM_LDMR_Malfunction 0 "None" 1 "Alert";
VAL_ 1153 BCM_RLBL_Malfunction 0 "None" 1 "Alert";
VAL_ 1153 BCM_RLBR_Malfunction 0 "None" 1 "Alert";
VAL_ 1153 BCM_RLT_Malfunction 0 "None" 1 "Alert";
VAL_ 1153 BCM_BCM_POWER_Malfunction 0 "None" 1 "Alert";
VAL_ 1153 BCM_IDB_AutoHazardBlinking_Malf 0 "None" 1 "Alert";
VAL_ 1155 TPMS_FLTirePress 255 "Invalid" ;
VAL_ 1155 TPMS_FRTirePress 255 "Invalid" ;
VAL_ 1155 TPMS_RLTirePress 255 "Invalid" ;
VAL_ 1155 TPMS_RRTirePress 255 "Invalid" ;
VAL_ 1155 TPMS_FLTirePressAlarm 0 "No warning" 1 "High pressure warning" 2 "Low pressure warning" 3 "Quick leakage" 4 "Lost Sensor" 5 "Sensor battery low" 6 "Sensor failure" 7 "Reserved" ;
VAL_ 1155 TPMS_FRTirePressAlarm 0 "No warning" 1 "High pressure warning" 2 "Low pressure warning" 3 "Quick leakage" 4 "Lost Sensor" 5 "Sensor battery low" 6 "Sensor failure" 7 "Reserved" ;
VAL_ 1155 TPMS_RLTirePressAlarm 0 "No warning" 1 "High pressure warning" 2 "Low pressure warning" 3 "Quick leakage" 4 "Lost Sensor" 5 "Sensor battery low" 6 "Sensor failure" 7 "Reserved" ;
VAL_ 1155 TPMS_RRTirePressAlarm 0 "No warning" 1 "High pressure warning" 2 "Low pressure warning" 3 "Quick leakage" 4 "Lost Sensor" 5 "Sensor battery low" 6 "Sensor failure" 7 "Reserved" ;
VAL_ 1155 TPMS_TirePosition 0 "No any sensor" 1 "Left Front tire" 2 "Right Front tire" 3 "Right Rear tire" 4 "Left Rear tire" 5 "reseved" 6 "reseved" 7 "reserved" ;
VAL_ 1155 TPMS_ready2learning 0 "Invalid" 1 "Ready" ;
VAL_ 1155 TPMS_TireTempAlarm 0 "No warning" 1 "High Temperature Warning" ;
VAL_ 1155 TPMS_LearningStatus 0 "invalid" 1 "Left Front tire done" 2 "Right Front tire done" 3 "Right Rear tire done" 4 "Left Rear tire done" 5 "All completed" 6 "Failure" 7 "reserved" ;
VAL_ 1155 TPMS_TireTemp 255 "Invalid" ;
VAL_ 1160 ACM_Malfunction 0 "ACM_Failure" 1 "ACM_Normal_Operation" ;
VAL_ 1160 ACM_Pre_Drive_Check 0 "ACM_Pre_Drive_Check" 1 "ACM_Normal_Operation" ;
VAL_ 1160 ACM_in_Plant_Mode 0 "ACM_in_Plant_Mode" 1 "ACM_in_Normal_Mode" ;
VAL_ 1160 ACM_PAB_Suppression 0 "Not_Suppressed" 1 "Suppressed" 2 "Function Failure" 3 "Invalid_Value" ;
VAL_ 1160 ACM_Airbag_Disabled 0 "ACM_AirBag_Disabled" 1 "ACM_Normal_Operation" ;
VAL_ 1160 ACM_Development_Calibration 0 "ACM_Dev_Calibrated" 1 "ACM_Normal_Operation" ;
VAL_ 1160 ACM_In_Disposal_Mode 0 "ACM_In_Disposal_Mode" 1 "ACM_Normal_Operation" ;
VAL_ 1160 ACM_Seatbelt_Reminder_Request 0 "Seatbelt reminder NOT activated" 1 "Seatbelt reminder activated" ;
VAL_ 1160 ACM_SBR_Chime_Req 0 "No Active Chime" 1 "Active Chime" ;
VAL_ 1160 ACM_SBR_Blinking_Req 0 "No Blinking" 1 "Blinking 1Hz" ;
VAL_ 1161 CCU_Malfunction 0 "No Error" 1 "Error" ;
VAL_ 1161 CCU_Warning_Flag_2 0 "No Error" 1 "Error" ;
VAL_ 1161 CCU_Warning_Flag_3 0 "No Error" 1 "Error" ;
VAL_ 1161 CCU_Warning_Flag_4 0 "No Error" 1 "Error" ;
VAL_ 1161 CCU_Warning_Flag_5 0 "No Error" 1 "Error" ;
VAL_ 1161 CCU_Warning_Flag_6 0 "No Error" 1 "Error" ;
VAL_ 1161 CCU_Warning_Flag_7 0 "No Error" 1 "Error" ;
VAL_ 1161 CCU_Warning_Flag_8 0 "No Error" 1 "Error" ;
VAL_ 1161 CCU_Warning_Flag_9 0 "No Error" 1 "Error" ;
VAL_ 1161 CCU_Warning_Flag_10 0 "No Error" 1 "Error" ;
VAL_ 1161 CCU_Warning_Flag_11 0 "No Error" 1 "Error" ;
VAL_ 1161 CCU_Warning_Flag_12 0 "No Error" 1 "Error" ;
VAL_ 1166 ETG_Malfunction 0 "No Error" 1 "Error" ;
VAL_ 1166 ETG_Warning_Flag_2 0 "No Error" 1 "Error" ;
VAL_ 1166 ETG_Warning_Flag_3 0 "No Error" 1 "Error" ;
VAL_ 1166 ETG_Warning_Flag_4 0 "No Error" 1 "Error" ;
VAL_ 1166 ETG_Warning_Flag_5 0 "No Error" 1 "Error" ;
VAL_ 1166 ETG_Warning_Flag_6 0 "No Error" 1 "Error" ;
VAL_ 1166 ETG_Warning_Flag_7 0 "No Error" 1 "Error" ;
VAL_ 1166 ETG_Warning_Flag_8 0 "No Error" 1 "Error" ;
VAL_ 1166 ETG_Warning_Flag_9 0 "No Error" 1 "Error" ;
VAL_ 1166 ETG_Warning_Flag_10 0 "No Error" 1 "Error" ;
VAL_ 1166 ETG_Warning_Flag_11 0 "No Error" 1 "Error" ;
VAL_ 1166 ETG_Warning_Flag_12 0 "No Error" 1 "Error" ;
VAL_ 1171 BMS_PackTempSts 0 "No warning" 1 "Over Temperature Warning" 2 "Under Temperature Warning" 3 "Extreme low temp error";
VAL_ 1171 BMS_ThermalRunaway 0 "No Warning" 1 "Warning";
VAL_ 1171 BMS_BatteryReplacement 0 "No Warning" 1 "Warning";
VAL_ 1171 BMS_Warning_PowerDegrade 0 "Normal" 1 "Pack Power Degrade";
VAL_ 1171 BMS_Warning_DeltaSoC 0 "Normal" 1 "Delta SOC high";
VAL_ 1171 BMS_Warning_HVILSts 0 "Normal" 1 "HVIL error detected";
VAL_ 1171 BMS_Warning_Isolation 0 "Normal" 1 "Isolation reached level 3";
VAL_ 1171 BMS_Warning_CoolantLeakage 0 "Normal" 1 "Coolant leakage detected";
VAL_ 1171 BMS_MalfunctionSts 0 "No Warning" 1 "Warning";
VAL_ 1171 BMS_LowBattery 0 "No warning" 1 "Low level" 2 "Extremely low level";
VAL_ 1171 BMS_Warning_DeltaTemperature 0 "Normal" 1 "Level 1 warning" 2 "Level 2 extreme";
VAL_ 1171 BMS_Warning_BDUTemperatureSts 0 "Normal" 1 "BDU temp warning" 2 "BDU hot" 3 "BDU extreme hot";
VAL_ 1171 BMS_Warning_Contactor_Aging 0 "No warning" 1 "Warning" ;
VAL_ 1211 TRM_LightMalfnc 0 "No Error" 1 "Error" ;
VAL_ 1211 TRM_TurnLeftMafnc 0 "No Error" 1 "Error" ;
VAL_ 1211 TRM_TurnRightMafnc 0 "No Error" 1 "Error" ;
VAL_ 1211 TRM_TrailerMalfnc 0 "No Error" 1 "Error" ;
VAL_ 1211 TRM_Warning_Flag_5 0 "No Error" 1 "Error" ;
VAL_ 1211 TRM_Warning_Flag_6 0 "No Error" 1 "Error" ;
VAL_ 1211 TRM_Warning_Flag_7 0 "No Error" 1 "Error" ;
VAL_ 1211 TRM_Warning_Flag_8 0 "No Error" 1 "Error" ;
VAL_ 1211 TRM_Warning_Flag_9 0 "No Error" 1 "Error" ;
VAL_ 1211 TRM_Warning_Flag_10 0 "No Error" 1 "Error" ;
VAL_ 1211 TRM_Warning_Flag_11 0 "No Error" 1 "Error" ;
VAL_ 1211 TRM_Warning_Flag_12 0 "No Error" 1 "Error" ;
VAL_ 1216 BCM_STAT_DoorHandleRR 0 "Released" 1 "Pulled" ;
VAL_ 1216 BCM_STAT_DoorHandleRL 0 "Released" 1 "Pulled" ;
VAL_ 1216 BCM_STAT_DoorHandleFR 0 "Released" 1 "Pulled" ;
VAL_ 1216 BCM_STAT_DoorHandleFL 0 "Released" 1 "Pulled" ;
VAL_ 1217 APM_Malfunction 0 "No Error" 1 "Error" ;
VAL_ 1217 ChildWindowLockStS 0 "No Error" 1 "Error" ;
VAL_ 1217 APM_Warning_Flag_3 0 "No Error" 1 "Error" ;
VAL_ 1217 APM_Warning_Flag_4 0 "No Error" 1 "Error" ;
VAL_ 1217 APM_Warning_Flag_5 0 "No Error" 1 "Error" ;
VAL_ 1217 APM_Warning_Flag_6 0 "No Error" 1 "Error" ;
VAL_ 1217 APM_Warning_Flag_7 0 "No Error" 1 "Error" ;
VAL_ 1217 APM_Warning_Flag_8 0 "No Error" 1 "Error" ;
VAL_ 1217 APM_Warning_Flag_9 0 "No Error" 1 "Error" ;
VAL_ 1217 APM_Warning_Flag_10 0 "No Error" 1 "Error" ;
VAL_ 1217 APM_Warning_Flag_11 0 "No Error" 1 "Error" ;
VAL_ 1217 APM_Warning_Flag_12 0 "No Error" 1 "Error" ;
VAL_ 2046 TST_TxMsgConfirm_CcuHeatCoolReq 1 "Message Transmitted" 0 "Message Not Transmitted" ;
VAL_ 2046 TST_RxMsgConfirm_BCM_CLAMP_STAT 1 "Message Received" 0 "Message Not Received" ;
VAL_ 2046 CCU_TST_TxMsgConfirm_CcuWarnMsg 1 "Message Transmitted" 0 "Message Not Transmitted" ;
VAL_ 2046 CCU_TST_TxMsgConfirm_CcuNm 1 "Message Transmitted" 0 "Message Not Transmitted" ;
VAL_ 2046 CCU_TST_StateMngr_States 7 "SM_ACC_STATE" 6 "SM_BET_INIT" 5 "SM_SHUTDOWN" 4 "SM_SLEEPING" 3 "SM_STANDBY" 2 "SM_NORMAL_RUN" 1 "SM_SAFE_STATE" 0 "SM_INIT_CYCLIC" ;
VAL_ 2046 CCU_TST_NetworkMngr_States 7 "Not used" 6 "0x9 NM_STATE_BUS_OFF" 5 "NM_STATE_REPEAT_MESSAGE" 4 "NM_STATE_NORMAL_OPERATION" 3 "NM_STATE_READY_SLEEP" 2 "NM_STATE_PREPARE_BUS_SLEEP" 1 "NM_STATE_BUS_SLEEP" 0 "NM_STATE_UNINIT" ;
VAL_ 2046 CCU_TST_BCM_CRC 1 "CRC correct" 0 "CRC not correct";
